VERSION ""

NS_ :

BS_:

BU_: Device Host
VAL_TABLE_ vtBridgeOperation 0 "Freewheeling" 1 "Forward" 2 "Reverse" 3 "Brake" 6 "Error" 7 "Not Available" ;
VAL_TABLE_ vtBridgeStatus 0 "OK" 1 "Shutdown" 2 "Unconfigured" 3 "Not Available" ;
VAL_TABLE_ vtDigitalInput 0 "InputLow" 1 "InputHigh" 2 "Error" 3 "Not Available" ;
VAL_TABLE_ vtOnOff 0 "Off" 1 "On" 2 "Error" 3 "Not Available" ;
VAL_TABLE_ vtPinMode 0 "Disabled" 1 "VREF" 2 "HighSide" 3 "LowSide" 4 "InputOnly" 5 "Bridge" 14 "Error" 15 "Not Available" ;
VAL_TABLE_ vtPinPullMode 0 "None" 1 "PullDown" 2 "PullUp" 3 "Not Available" ;
VAL_TABLE_ vtPwmFreq 0 "1 Hz" 1 "2 Hz" 2 "5 Hz" 3 "10 Hz" 4 "20 Hz" 5 "50 Hz" 6 "100 Hz" 7 "200 Hz" 8 "500 Hz" 9 "1 KHz" 10 "2 KHz" 11 "5 KHz" 14 "Error" 15 "Not Available" ;
VAL_TABLE_ vtQEncoderDirection 0 "Stopped" 1 "Forward" 2 "Reverse" 3 "NotAvailable" ;

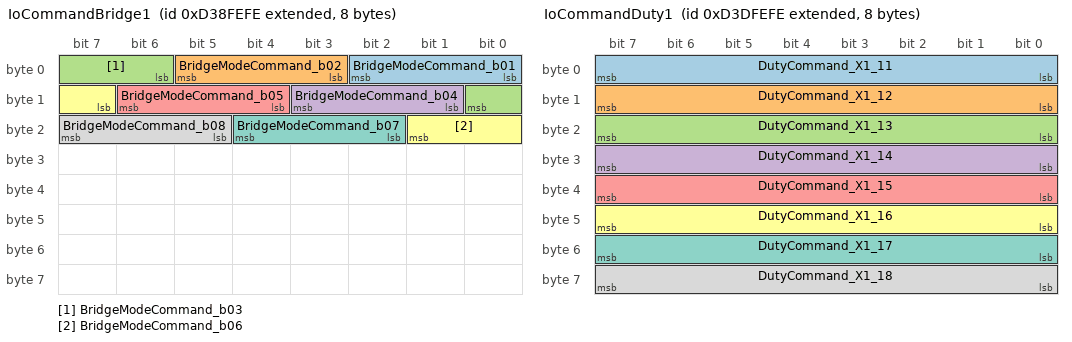
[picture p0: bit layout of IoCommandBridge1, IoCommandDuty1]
BO_ 2369322750 IoCommandBridge1: 8 Host
 SG_ BridgeModeCommand_b01 : 0|3@1+ (1,0) [0|7] ""  Device
 SG_ BridgeModeCommand_b02 : 3|3@1+ (1,0) [0|7] ""  Device
 SG_ BridgeModeCommand_b03 : 6|3@1+ (1,0) [0|7] ""  Device
 SG_ BridgeModeCommand_b04 : 9|3@1+ (1,0) [0|7] ""  Device
 SG_ BridgeModeCommand_b05 : 12|3@1+ (1,0) [0|7] ""  Device
 SG_ BridgeModeCommand_b06 : 15|3@1+ (1,0) [0|7] ""  Device
 SG_ BridgeModeCommand_b07 : 18|3@1+ (1,0) [0|7] ""  Device
 SG_ BridgeModeCommand_b08 : 21|3@1+ (1,0) [0|7] ""  Device

BO_ 2369650430 IoCommandDuty1: 8 Host
 SG_ DutyCommand_X1_11 : 0|8@1+ (0.5,0) [0|100] "%"  Device
 SG_ DutyCommand_X1_12 : 8|8@1+ (0.5,0) [0|100] "%"  Device
 SG_ DutyCommand_X1_13 : 16|8@1+ (0.5,0) [0|100] "%"  Device
 SG_ DutyCommand_X1_14 : 24|8@1+ (0.5,0) [0|100] "%"  Device
 SG_ DutyCommand_X1_15 : 32|8@1+ (0.5,0) [0|100] "%"  Device
 SG_ DutyCommand_X1_16 : 40|8@1+ (0.5,0) [0|100] "%"  Device
 SG_ DutyCommand_X1_17 : 48|8@1+ (0.5,0) [0|100] "%"  Device
 SG_ DutyCommand_X1_18 : 56|8@1+ (0.5,0) [0|100] "%"  Device

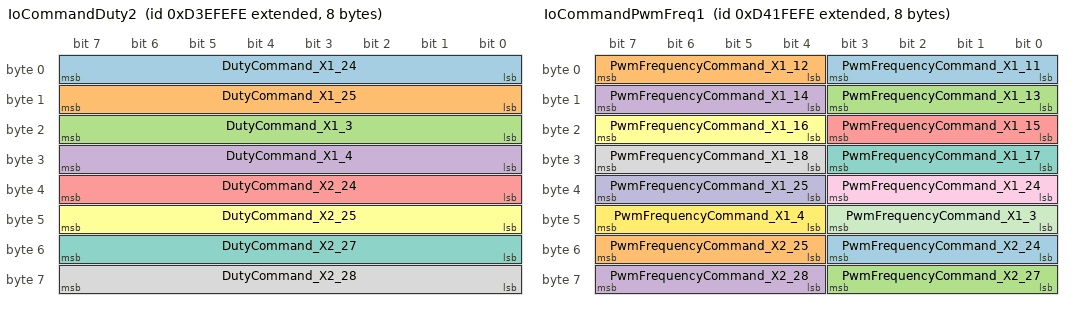
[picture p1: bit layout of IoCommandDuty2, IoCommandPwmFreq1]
BO_ 2369715966 IoCommandDuty2: 8 Host
 SG_ DutyCommand_X1_24 : 0|8@1+ (0.5,0) [0|100] "%"  Device
 SG_ DutyCommand_X1_25 : 8|8@1+ (0.5,0) [0|100] "%"  Device
 SG_ DutyCommand_X1_3 : 16|8@1+ (0.5,0) [0|100] "%"  Device
 SG_ DutyCommand_X1_4 : 24|8@1+ (0.5,0) [0|100] "%"  Device
 SG_ DutyCommand_X2_24 : 32|8@1+ (0.5,0) [0|100] "%"  Device
 SG_ DutyCommand_X2_25 : 40|8@1+ (0.5,0) [0|100] "%"  Device
 SG_ DutyCommand_X2_27 : 48|8@1+ (0.5,0) [0|100] "%"  Device
 SG_ DutyCommand_X2_28 : 56|8@1+ (0.5,0) [0|100] "%"  Device

BO_ 2370043646 IoCommandDutyFD: 32 Host
 SG_ DutyCommand_X1_11 : 0|8@1+ (0.5,0) [0|100] "%"  Device
 SG_ DutyCommand_X1_12 : 8|8@1+ (0.5,0) [0|100] "%"  Device
 SG_ DutyCommand_X1_13 : 16|8@1+ (0.5,0) [0|100] "%"  Device
 SG_ DutyCommand_X1_14 : 24|8@1+ (0.5,0) [0|100] "%"  Device
 SG_ DutyCommand_X1_15 : 32|8@1+ (0.5,0) [0|100] "%"  Device
 SG_ DutyCommand_X1_16 : 40|8@1+ (0.5,0) [0|100] "%"  Device
 SG_ DutyCommand_X1_17 : 48|8@1+ (0.5,0) [0|100] "%"  Device
 SG_ DutyCommand_X1_18 : 56|8@1+ (0.5,0) [0|100] "%"  Device
 SG_ DutyCommand_X1_24 : 64|8@1+ (0.5,0) [0|100] "%"  Device
 SG_ DutyCommand_X1_25 : 72|8@1+ (0.5,0) [0|100] "%"  Device
 SG_ DutyCommand_X1_3 : 80|8@1+ (0.5,0) [0|100] "%"  Device
 SG_ DutyCommand_X1_4 : 88|8@1+ (0.5,0) [0|100] "%"  Device
 SG_ DutyCommand_X2_24 : 96|8@1+ (0.5,0) [0|100] "%"  Device
 SG_ DutyCommand_X2_25 : 104|8@1+ (0.5,0) [0|100] "%"  Device
 SG_ DutyCommand_X2_27 : 112|8@1+ (0.5,0) [0|100] "%"  Device
 SG_ DutyCommand_X2_28 : 120|8@1+ (0.5,0) [0|100] "%"  Device

BO_ 2369388286 IoCommandPinMode1: 8 Host
 SG_ PinModeCommand_X1_11 : 0|4@1+ (1,0) [0|0] ""  Device
 SG_ PinPullModeCommand_X1_11 : 4|2@1+ (1,0) [0|0] ""  Device
 SG_ LoadDetectionCommand_X1_11 : 6|2@1+ (1,0) [0|0] ""  Device
 SG_ PinModeCommand_X1_12 : 8|4@1+ (1,0) [0|0] ""  Device
 SG_ PinPullModeCommand_X1_12 : 12|2@1+ (1,0) [0|0] ""  Device
 SG_ LoadDetectionCommand_X1_12 : 14|2@1+ (1,0) [0|0] ""  Device
 SG_ PinModeCommand_X1_13 : 16|4@1+ (1,0) [0|0] ""  Device
 SG_ PinPullModeCommand_X1_13 : 20|2@1+ (1,0) [0|0] ""  Device
 SG_ LoadDetectionCommand_X1_13 : 22|2@1+ (1,0) [0|0] ""  Device
 SG_ PinModeCommand_X1_14 : 24|4@1+ (1,0) [0|0] ""  Device
 SG_ PinPullModeCommand_X1_14 : 28|2@1+ (1,0) [0|0] ""  Device
 SG_ LoadDetectionCommand_X1_14 : 30|2@1+ (1,0) [0|0] ""  Device
 SG_ PinModeCommand_X1_15 : 32|4@1+ (1,0) [0|0] ""  Device
 SG_ PinPullModeCommand_X1_15 : 36|2@1+ (1,0) [0|0] ""  Device
 SG_ LoadDetectionCommand_X1_15 : 38|2@1+ (1,0) [0|0] ""  Device
 SG_ PinModeCommand_X1_16 : 40|4@1+ (1,0) [0|0] ""  Device
 SG_ PinPullModeCommand_X1_16 : 44|2@1+ (1,0) [0|0] ""  Device
 SG_ LoadDetectionCommand_X1_16 : 46|2@1+ (1,0) [0|0] ""  Device
 SG_ PinModeCommand_X1_17 : 48|4@1+ (1,0) [0|0] ""  Device
 SG_ PinPullModeCommand_X1_17 : 52|2@1+ (1,0) [0|0] ""  Device
 SG_ LoadDetectionCommand_X1_17 : 54|2@1+ (1,0) [0|0] ""  Device
 SG_ PinModeCommand_X1_18 : 56|4@1+ (1,0) [0|0] ""  Device
 SG_ PinPullModeCommand_X1_18 : 60|2@1+ (1,0) [0|0] ""  Device
 SG_ LoadDetectionCommand_X1_18 : 62|2@1+ (1,0) [0|0] ""  Device

BO_ 2369453822 IoCommandPinMode2: 8 Host
 SG_ PinModeCommand_X1_24 : 0|4@1+ (1,0) [0|0] ""  Device
 SG_ PinPullModeCommand_X1_24 : 4|2@1+ (1,0) [0|0] ""  Device
 SG_ LoadDetectionCommand_X1_24 : 6|2@1+ (1,0) [0|0] ""  Device
 SG_ PinModeCommand_X1_25 : 8|4@1+ (1,0) [0|0] ""  Device
 SG_ PinPullModeCommand_X1_25 : 12|2@1+ (1,0) [0|0] ""  Device
 SG_ LoadDetectionCommand_X1_25 : 14|2@1+ (1,0) [0|0] ""  Device
 SG_ PinModeCommand_X1_3 : 16|4@1+ (1,0) [0|0] ""  Device
 SG_ PinPullModeCommand_X1_3 : 20|2@1+ (1,0) [0|0] ""  Device
 SG_ LoadDetectionCommand_X1_3 : 22|2@1+ (1,0) [0|0] ""  Device
 SG_ PinModeCommand_X1_4 : 24|4@1+ (1,0) [0|0] ""  Device
 SG_ PinPullModeCommand_X1_4 : 28|2@1+ (1,0) [0|0] ""  Device
 SG_ LoadDetectionCommand_X1_4 : 30|2@1+ (1,0) [0|0] ""  Device
 SG_ PinModeCommand_X2_24 : 32|4@1+ (1,0) [0|0] ""  Device
 SG_ PinPullModeCommand_X2_24 : 36|2@1+ (1,0) [0|0] ""  Device
 SG_ LoadDetectionCommand_X2_24 : 38|2@1+ (1,0) [0|0] ""  Device
 SG_ PinModeCommand_X2_25 : 40|4@1+ (1,0) [0|0] ""  Device
 SG_ PinPullModeCommand_X2_25 : 44|2@1+ (1,0) [0|0] ""  Device
 SG_ LoadDetectionCommand_X2_25 : 46|2@1+ (1,0) [0|0] ""  Device
 SG_ PinModeCommand_X2_27 : 48|4@1+ (1,0) [0|0] ""  Device
 SG_ PinPullModeCommand_X2_27 : 52|2@1+ (1,0) [0|0] ""  Device
 SG_ LoadDetectionCommand_X2_27 : 54|2@1+ (1,0) [0|0] ""  Device
 SG_ PinModeCommand_X2_28 : 56|4@1+ (1,0) [0|0] ""  Device
 SG_ PinPullModeCommand_X2_28 : 60|2@1+ (1,0) [0|0] ""  Device
 SG_ LoadDetectionCommand_X2_28 : 62|2@1+ (1,0) [0|0] ""  Device

BO_ 2369519358 IoCommandPinMode3: 8 Host
 SG_ PinModeCommand_X2_11 : 0|4@1+ (1,0) [0|0] ""  Device
 SG_ PinPullModeCommand_X2_11 : 4|2@1+ (1,0) [0|0] ""  Device
 SG_ LoadDetectionCommand_X2_11 : 6|2@1+ (1,0) [0|0] ""  Device
 SG_ PinModeCommand_X2_12 : 8|4@1+ (1,0) [0|0] ""  Device
 SG_ PinPullModeCommand_X2_12 : 12|2@1+ (1,0) [0|0] ""  Device
 SG_ LoadDetectionCommand_X2_12 : 14|2@1+ (1,0) [0|0] ""  Device
 SG_ PinModeCommand_X2_13 : 16|4@1+ (1,0) [0|0] ""  Device
 SG_ PinPullModeCommand_X2_13 : 20|2@1+ (1,0) [0|0] ""  Device
 SG_ LoadDetectionCommand_X2_13 : 22|2@1+ (1,0) [0|0] ""  Device
 SG_ PinModeCommand_X2_14 : 24|4@1+ (1,0) [0|0] ""  Device
 SG_ PinPullModeCommand_X2_14 : 28|2@1+ (1,0) [0|0] ""  Device
 SG_ LoadDetectionCommand_X2_14 : 30|2@1+ (1,0) [0|0] ""  Device
 SG_ PinModeCommand_X2_15 : 32|4@1+ (1,0) [0|0] ""  Device
 SG_ PinPullModeCommand_X2_15 : 36|2@1+ (1,0) [0|0] ""  Device
 SG_ LoadDetectionCommand_X2_15 : 38|2@1+ (1,0) [0|0] ""  Device
 SG_ PinModeCommand_X2_16 : 40|4@1+ (1,0) [0|0] ""  Device
 SG_ PinPullModeCommand_X2_16 : 44|2@1+ (1,0) [0|0] ""  Device
 SG_ LoadDetectionCommand_X2_16 : 46|2@1+ (1,0) [0|0] ""  Device
 SG_ PinModeCommand_X2_17 : 48|4@1+ (1,0) [0|0] ""  Device
 SG_ PinPullModeCommand_X2_17 : 52|2@1+ (1,0) [0|0] ""  Device
 SG_ LoadDetectionCommand_X2_17 : 54|2@1+ (1,0) [0|0] ""  Device
 SG_ PinModeCommand_X2_18 : 56|4@1+ (1,0) [0|0] ""  Device
 SG_ PinPullModeCommand_X2_18 : 60|2@1+ (1,0) [0|0] ""  Device
 SG_ LoadDetectionCommand_X2_18 : 62|2@1+ (1,0) [0|0] ""  Device

BO_ 2369912574 IoCommandPwmFreq1: 8 Host
 SG_ PwmFrequencyCommand_X1_11 : 0|4@1+ (1,0) [0|15] ""  Device
 SG_ PwmFrequencyCommand_X1_12 : 4|4@1+ (1,0) [0|15] ""  Device
 SG_ PwmFrequencyCommand_X1_13 : 8|4@1+ (1,0) [0|15] ""  Device
 SG_ PwmFrequencyCommand_X1_14 : 12|4@1+ (1,0) [0|15] ""  Device
 SG_ PwmFrequencyCommand_X1_15 : 16|4@1+ (1,0) [0|15] ""  Device
 SG_ PwmFrequencyCommand_X1_16 : 20|4@1+ (1,0) [0|15] ""  Device
 SG_ PwmFrequencyCommand_X1_17 : 24|4@1+ (1,0) [0|15] ""  Device
 SG_ PwmFrequencyCommand_X1_18 : 28|4@1+ (1,0) [0|15] ""  Device
 SG_ PwmFrequencyCommand_X1_24 : 32|4@1+ (1,0) [0|15] ""  Device
 SG_ PwmFrequencyCommand_X1_25 : 36|4@1+ (1,0) [0|15] ""  Device
 SG_ PwmFrequencyCommand_X1_3 : 40|4@1+ (1,0) [0|15] ""  Device
 SG_ PwmFrequencyCommand_X1_4 : 44|4@1+ (1,0) [0|15] ""  Device
 SG_ PwmFrequencyCommand_X2_24 : 48|4@1+ (1,0) [0|15] ""  Device
 SG_ PwmFrequencyCommand_X2_25 : 52|4@1+ (1,0) [0|15] ""  Device
 SG_ PwmFrequencyCommand_X2_27 : 56|4@1+ (1,0) [0|15] ""  Device
 SG_ PwmFrequencyCommand_X2_28 : 60|4@1+ (1,0) [0|15] ""  Device

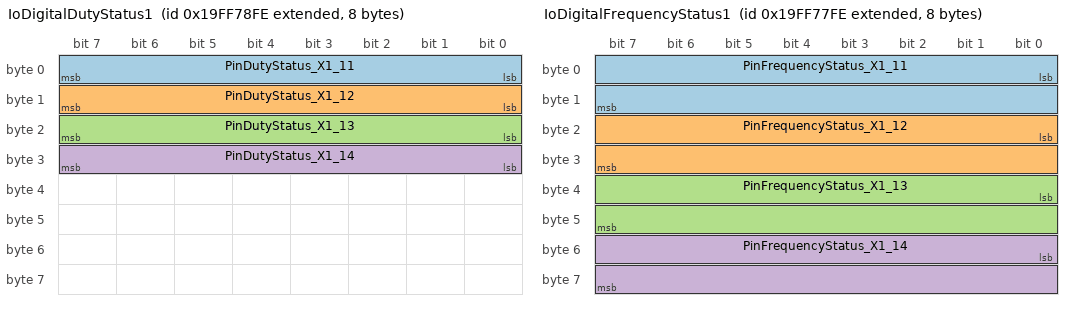
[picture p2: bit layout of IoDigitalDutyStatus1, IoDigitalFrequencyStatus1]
BO_ 2583656702 IoDigitalDutyStatus1: 8 Device
 SG_ PinDutyStatus_X1_11 : 0|8@1+ (0.5,0) [0|100] "%"  Host
 SG_ PinDutyStatus_X1_12 : 8|8@1+ (0.5,0) [0|100] "%"  Host
 SG_ PinDutyStatus_X1_13 : 16|8@1+ (0.5,0) [0|100] "%"  Host
 SG_ PinDutyStatus_X1_14 : 24|8@1+ (0.5,0) [0|100] "%"  Host

BO_ 2583656446 IoDigitalFrequencyStatus1: 8 Device
 SG_ PinFrequencyStatus_X1_11 : 0|16@1+ (0.1,0) [0|6425.5] "Hz"  Host
 SG_ PinFrequencyStatus_X1_12 : 16|16@1+ (0.1,0) [0|6425.5] "Hz"  Host
 SG_ PinFrequencyStatus_X1_13 : 32|16@1+ (0.1,0) [0|6425.5] "Hz"  Host
 SG_ PinFrequencyStatus_X1_14 : 48|16@1+ (0.1,0) [0|6425.5] "Hz"  Host

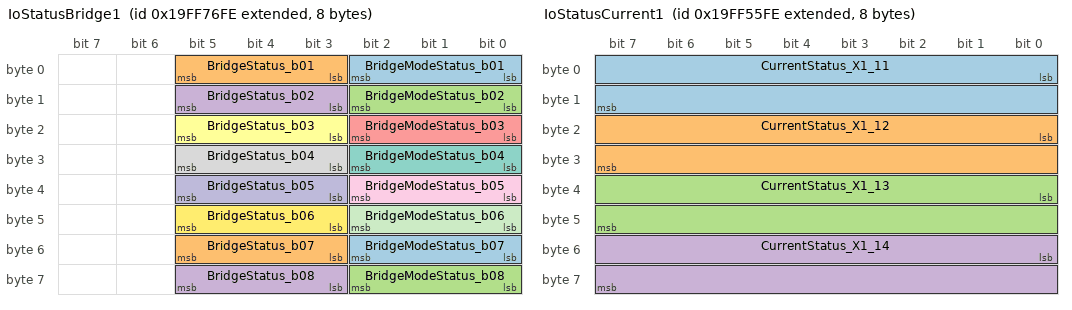
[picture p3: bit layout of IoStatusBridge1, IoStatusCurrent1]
BO_ 2583656190 IoStatusBridge1: 8 Device
 SG_ BridgeModeStatus_b01 : 0|3@1+ (1,0) [0|7] ""  Host
 SG_ BridgeStatus_b01 : 3|3@1+ (1,0) [0|7] ""  Host
 SG_ BridgeModeStatus_b02 : 8|3@1+ (1,0) [0|7] ""  Host
 SG_ BridgeStatus_b02 : 11|3@1+ (1,0) [0|7] ""  Host
 SG_ BridgeModeStatus_b03 : 16|3@1+ (1,0) [0|7] ""  Host
 SG_ BridgeStatus_b03 : 19|3@1+ (1,0) [0|7] ""  Host
 SG_ BridgeModeStatus_b04 : 24|3@1+ (1,0) [0|7] ""  Host
 SG_ BridgeStatus_b04 : 27|3@1+ (1,0) [0|7] ""  Host
 SG_ BridgeModeStatus_b05 : 32|3@1+ (1,0) [0|7] ""  Host
 SG_ BridgeStatus_b05 : 35|3@1+ (1,0) [0|7] ""  Host
 SG_ BridgeModeStatus_b06 : 40|3@1+ (1,0) [0|7] ""  Host
 SG_ BridgeStatus_b06 : 43|3@1+ (1,0) [0|7] ""  Host
 SG_ BridgeModeStatus_b07 : 48|3@1+ (1,0) [0|7] ""  Host
 SG_ BridgeStatus_b07 : 51|3@1+ (1,0) [0|7] ""  Host
 SG_ BridgeModeStatus_b08 : 56|3@1+ (1,0) [0|7] ""  Host
 SG_ BridgeStatus_b08 : 59|3@1+ (1,0) [0|7] ""  Host

BO_ 2583647742 IoStatusCurrent1: 8 Device
 SG_ CurrentStatus_X1_11 : 0|16@1+ (0.01,-320) [-320|320] "A"  Host
 SG_ CurrentStatus_X1_12 : 16|16@1+ (0.01,-320) [-320|320] "A"  Host
 SG_ CurrentStatus_X1_13 : 32|16@1+ (0.01,-320) [-320|320] "A"  Host
 SG_ CurrentStatus_X1_14 : 48|16@1+ (0.01,-320) [-320|320] "A"  Host

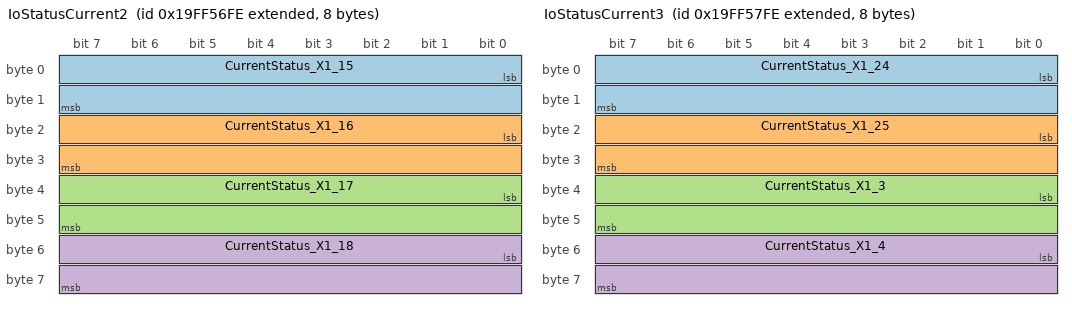
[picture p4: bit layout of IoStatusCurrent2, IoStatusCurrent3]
BO_ 2583647998 IoStatusCurrent2: 8 Device
 SG_ CurrentStatus_X1_15 : 0|16@1+ (0.01,-320) [-320|320] "A"  Host
 SG_ CurrentStatus_X1_16 : 16|16@1+ (0.01,-320) [-320|320] "A"  Host
 SG_ CurrentStatus_X1_17 : 32|16@1+ (0.01,-320) [-320|320] "A"  Host
 SG_ CurrentStatus_X1_18 : 48|16@1+ (0.01,-320) [-320|320] "A"  Host

BO_ 2583648254 IoStatusCurrent3: 8 Device
 SG_ CurrentStatus_X1_24 : 0|16@1+ (0.01,-320) [-320|320] "A"  Host
 SG_ CurrentStatus_X1_25 : 16|16@1+ (0.01,-320) [-320|320] "A"  Host
 SG_ CurrentStatus_X1_3 : 32|16@1+ (0.01,-320) [-320|320] "A"  Host
 SG_ CurrentStatus_X1_4 : 48|16@1+ (0.01,-320) [-320|320] "A"  Host

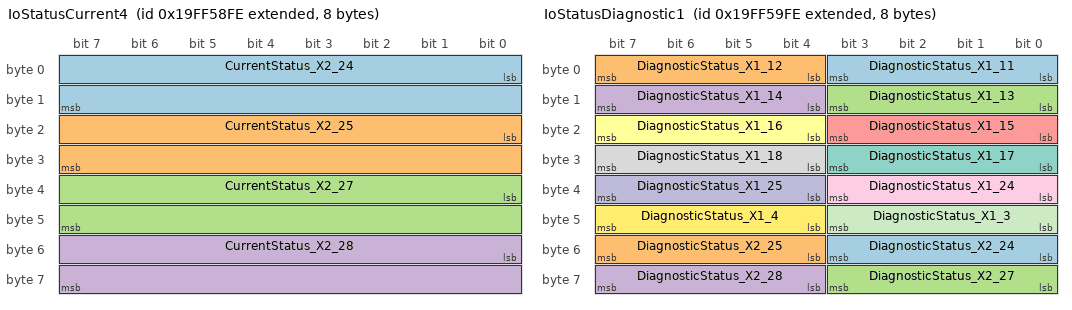
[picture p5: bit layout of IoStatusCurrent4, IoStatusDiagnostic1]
BO_ 2583648510 IoStatusCurrent4: 8 Device
 SG_ CurrentStatus_X2_24 : 0|16@1+ (0.01,-320) [-320|320] "A"  Host
 SG_ CurrentStatus_X2_25 : 16|16@1+ (0.01,-320) [-320|320] "A"  Host
 SG_ CurrentStatus_X2_27 : 32|16@1+ (0.01,-320) [-320|320] "A"  Host
 SG_ CurrentStatus_X2_28 : 48|16@1+ (0.01,-320) [-320|320] "A"  Host

BO_ 2582845950 IoStatusCurrentFD: 64 Device
 SG_ CurrentStatus_X1_11 : 0|16@1+ (0.01,-320) [-320|320] "A"  Host
 SG_ CurrentStatus_X1_12 : 16|16@1+ (0.01,-320) [-320|320] "A"  Host
 SG_ CurrentStatus_X1_13 : 32|16@1+ (0.01,-320) [-320|320] "A"  Host
 SG_ CurrentStatus_X1_14 : 48|16@1+ (0.01,-320) [-320|320] "A"  Host
 SG_ CurrentStatus_X1_15 : 64|16@1+ (0.01,-320) [-320|320] "A"  Host
 SG_ CurrentStatus_X1_16 : 80|16@1+ (0.01,-320) [-320|320] "A"  Host
 SG_ CurrentStatus_X1_17 : 96|16@1+ (0.01,-320) [-320|320] "A"  Host
 SG_ CurrentStatus_X1_18 : 112|16@1+ (0.01,-320) [-320|320] "A"  Host
 SG_ CurrentStatus_X1_24 : 128|16@1+ (0.01,-320) [-320|320] "A"  Host
 SG_ CurrentStatus_X1_25 : 144|16@1+ (0.01,-320) [-320|320] "A"  Host
 SG_ CurrentStatus_X1_3 : 160|16@1+ (0.01,-320) [-320|320] "A"  Host
 SG_ CurrentStatus_X1_4 : 176|16@1+ (0.01,-320) [-320|320] "A"  Host
 SG_ CurrentStatus_X2_24 : 192|16@1+ (0.01,-320) [-320|320] "A"  Host
 SG_ CurrentStatus_X2_25 : 208|16@1+ (0.01,-320) [-320|320] "A"  Host
 SG_ CurrentStatus_X2_27 : 224|16@1+ (0.01,-320) [-320|320] "A"  Host
 SG_ CurrentStatus_X2_28 : 240|16@1+ (0.01,-320) [-320|320] "A"  Host

BO_ 2583648766 IoStatusDiagnostic1: 8 Device
 SG_ DiagnosticStatus_X1_11 : 0|4@1+ (1,0) [0|0] ""  Host
 SG_ DiagnosticStatus_X1_12 : 4|4@1+ (1,0) [0|0] ""  Host
 SG_ DiagnosticStatus_X1_13 : 8|4@1+ (1,0) [0|0] ""  Host
 SG_ DiagnosticStatus_X1_14 : 12|4@1+ (1,0) [0|0] ""  Host
 SG_ DiagnosticStatus_X1_15 : 16|4@1+ (1,0) [0|0] ""  Host
 SG_ DiagnosticStatus_X1_16 : 20|4@1+ (1,0) [0|0] ""  Host
 SG_ DiagnosticStatus_X1_17 : 24|4@1+ (1,0) [0|0] ""  Host
 SG_ DiagnosticStatus_X1_18 : 28|4@1+ (1,0) [0|0] ""  Host
 SG_ DiagnosticStatus_X1_24 : 32|4@1+ (1,0) [0|0] ""  Host
 SG_ DiagnosticStatus_X1_25 : 36|4@1+ (1,0) [0|0] ""  Host
 SG_ DiagnosticStatus_X1_3 : 40|4@1+ (1,0) [0|0] ""  Host
 SG_ DiagnosticStatus_X1_4 : 44|4@1+ (1,0) [0|0] ""  Host
 SG_ DiagnosticStatus_X2_24 : 48|4@1+ (1,0) [0|0] ""  Host
 SG_ DiagnosticStatus_X2_25 : 52|4@1+ (1,0) [0|0] ""  Host
 SG_ DiagnosticStatus_X2_27 : 56|4@1+ (1,0) [0|0] ""  Host
 SG_ DiagnosticStatus_X2_28 : 60|4@1+ (1,0) [0|0] ""  Host

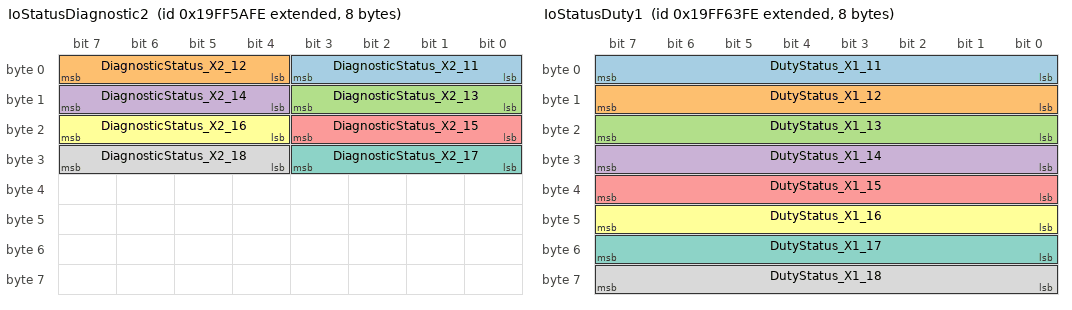
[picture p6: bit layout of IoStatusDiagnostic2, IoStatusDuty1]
BO_ 2583649022 IoStatusDiagnostic2: 8 Device
 SG_ DiagnosticStatus_X2_11 : 0|4@1+ (1,0) [0|0] ""  Host
 SG_ DiagnosticStatus_X2_12 : 4|4@1+ (1,0) [0|0] ""  Host
 SG_ DiagnosticStatus_X2_13 : 8|4@1+ (1,0) [0|0] ""  Host
 SG_ DiagnosticStatus_X2_14 : 12|4@1+ (1,0) [0|0] ""  Host
 SG_ DiagnosticStatus_X2_15 : 16|4@1+ (1,0) [0|0] ""  Host
 SG_ DiagnosticStatus_X2_16 : 20|4@1+ (1,0) [0|0] ""  Host
 SG_ DiagnosticStatus_X2_17 : 24|4@1+ (1,0) [0|0] ""  Host
 SG_ DiagnosticStatus_X2_18 : 28|4@1+ (1,0) [0|0] ""  Host

BO_ 2582847486 IoStatusDiagnosticFD: 16 Device
 SG_ DiagnosticStatus_X1_11 : 0|4@1+ (1,0) [0|0] ""  Host
 SG_ DiagnosticStatus_X1_12 : 4|4@1+ (1,0) [0|0] ""  Host
 SG_ DiagnosticStatus_X1_13 : 8|4@1+ (1,0) [0|0] ""  Host
 SG_ DiagnosticStatus_X1_14 : 12|4@1+ (1,0) [0|0] ""  Host
 SG_ DiagnosticStatus_X1_15 : 16|4@1+ (1,0) [0|0] ""  Host
 SG_ DiagnosticStatus_X1_16 : 20|4@1+ (1,0) [0|0] ""  Host
 SG_ DiagnosticStatus_X1_17 : 24|4@1+ (1,0) [0|0] ""  Host
 SG_ DiagnosticStatus_X1_18 : 28|4@1+ (1,0) [0|0] ""  Host
 SG_ DiagnosticStatus_X1_24 : 32|4@1+ (1,0) [0|0] ""  Host
 SG_ DiagnosticStatus_X1_25 : 36|4@1+ (1,0) [0|0] ""  Host
 SG_ DiagnosticStatus_X1_3 : 40|4@1+ (1,0) [0|0] ""  Host
 SG_ DiagnosticStatus_X1_4 : 44|4@1+ (1,0) [0|0] ""  Host
 SG_ DiagnosticStatus_X2_24 : 48|4@1+ (1,0) [0|0] ""  Host
 SG_ DiagnosticStatus_X2_25 : 52|4@1+ (1,0) [0|0] ""  Host
 SG_ DiagnosticStatus_X2_27 : 56|4@1+ (1,0) [0|0] ""  Host
 SG_ DiagnosticStatus_X2_28 : 60|4@1+ (1,0) [0|0] ""  Host
 SG_ DiagnosticStatus_X2_11 : 64|4@1+ (1,0) [0|0] ""  Host
 SG_ DiagnosticStatus_X2_12 : 68|4@1+ (1,0) [0|0] ""  Host
 SG_ DiagnosticStatus_X2_13 : 72|4@1+ (1,0) [0|0] ""  Host
 SG_ DiagnosticStatus_X2_14 : 76|4@1+ (1,0) [0|0] ""  Host
 SG_ DiagnosticStatus_X2_15 : 80|4@1+ (1,0) [0|0] ""  Host
 SG_ DiagnosticStatus_X2_16 : 84|4@1+ (1,0) [0|0] ""  Host
 SG_ DiagnosticStatus_X2_17 : 88|4@1+ (1,0) [0|0] ""  Host
 SG_ DiagnosticStatus_X2_18 : 92|4@1+ (1,0) [0|0] ""  Host

BO_ 2583651326 IoStatusDuty1: 8 Device
 SG_ DutyStatus_X1_11 : 0|8@1+ (0.5,0) [0|100] "%"  Host
 SG_ DutyStatus_X1_12 : 8|8@1+ (0.5,0) [0|100] "%"  Host
 SG_ DutyStatus_X1_13 : 16|8@1+ (0.5,0) [0|100] "%"  Host
 SG_ DutyStatus_X1_14 : 24|8@1+ (0.5,0) [0|100] "%"  Host
 SG_ DutyStatus_X1_15 : 32|8@1+ (0.5,0) [0|100] "%"  Host
 SG_ DutyStatus_X1_16 : 40|8@1+ (0.5,0) [0|100] "%"  Host
 SG_ DutyStatus_X1_17 : 48|8@1+ (0.5,0) [0|100] "%"  Host
 SG_ DutyStatus_X1_18 : 56|8@1+ (0.5,0) [0|100] "%"  Host

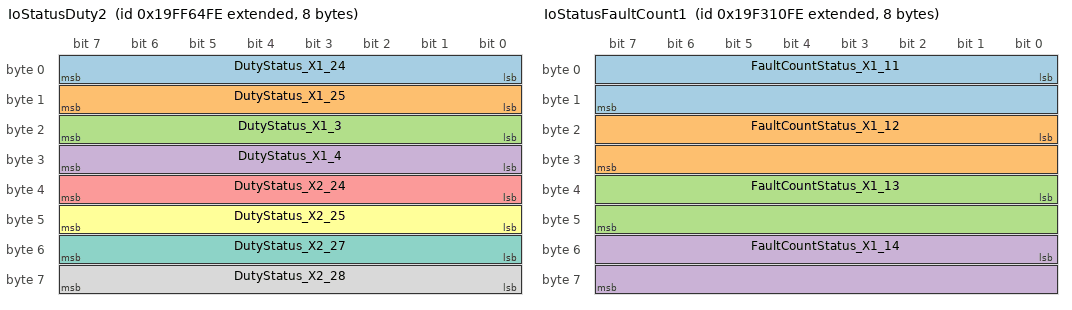
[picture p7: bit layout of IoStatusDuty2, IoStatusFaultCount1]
BO_ 2583651582 IoStatusDuty2: 8 Device
 SG_ DutyStatus_X1_24 : 0|8@1+ (0.5,0) [0|100] "%"  Host
 SG_ DutyStatus_X1_25 : 8|8@1+ (0.5,0) [0|100] "%"  Host
 SG_ DutyStatus_X1_3 : 16|8@1+ (0.5,0) [0|100] "%"  Host
 SG_ DutyStatus_X1_4 : 24|8@1+ (0.5,0) [0|100] "%"  Host
 SG_ DutyStatus_X2_24 : 32|8@1+ (0.5,0) [0|100] "%"  Host
 SG_ DutyStatus_X2_25 : 40|8@1+ (0.5,0) [0|100] "%"  Host
 SG_ DutyStatus_X2_27 : 48|8@1+ (0.5,0) [0|100] "%"  Host
 SG_ DutyStatus_X2_28 : 56|8@1+ (0.5,0) [0|100] "%"  Host

BO_ 2582847742 IoStatusDutyFD: 32 Device
 SG_ DutyStatus_X1_11 : 0|8@1+ (0.5,0) [0|100] "%"  Host
 SG_ DutyStatus_X1_12 : 8|8@1+ (0.5,0) [0|100] "%"  Host
 SG_ DutyStatus_X1_13 : 16|8@1+ (0.5,0) [0|100] "%"  Host
 SG_ DutyStatus_X1_14 : 24|8@1+ (0.5,0) [0|100] "%"  Host
 SG_ DutyStatus_X1_15 : 32|8@1+ (0.5,0) [0|100] "%"  Host
 SG_ DutyStatus_X1_16 : 40|8@1+ (0.5,0) [0|100] "%"  Host
 SG_ DutyStatus_X1_17 : 48|8@1+ (0.5,0) [0|100] "%"  Host
 SG_ DutyStatus_X1_18 : 56|8@1+ (0.5,0) [0|100] "%"  Host
 SG_ DutyStatus_X1_24 : 64|8@1+ (0.5,0) [0|100] "%"  Host
 SG_ DutyStatus_X1_25 : 72|8@1+ (0.5,0) [0|100] "%"  Host
 SG_ DutyStatus_X1_3 : 80|8@1+ (0.5,0) [0|100] "%"  Host
 SG_ DutyStatus_X1_4 : 88|8@1+ (0.5,0) [0|100] "%"  Host
 SG_ DutyStatus_X2_24 : 96|8@1+ (0.5,0) [0|100] "%"  Host
 SG_ DutyStatus_X2_25 : 104|8@1+ (0.5,0) [0|100] "%"  Host
 SG_ DutyStatus_X2_27 : 112|8@1+ (0.5,0) [0|100] "%"  Host
 SG_ DutyStatus_X2_28 : 120|8@1+ (0.5,0) [0|100] "%"  Host

BO_ 2582843646 IoStatusFaultCount1: 8 Device
 SG_ FaultCountStatus_X1_11 : 0|16@1+ (1,0) [0|64255] ""  Host
 SG_ FaultCountStatus_X1_12 : 16|16@1+ (1,0) [0|64255] ""  Host
 SG_ FaultCountStatus_X1_13 : 32|16@1+ (1,0) [0|64255] ""  Host
 SG_ FaultCountStatus_X1_14 : 48|16@1+ (1,0) [0|64255] ""  Host

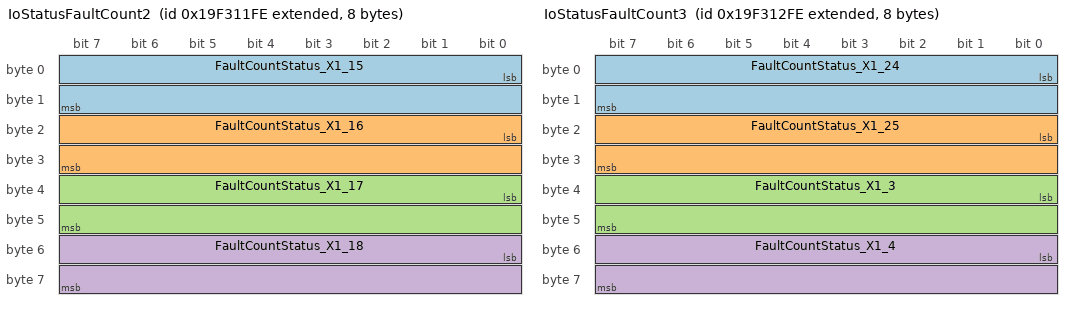
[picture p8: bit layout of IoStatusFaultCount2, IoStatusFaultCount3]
BO_ 2582843902 IoStatusFaultCount2: 8 Device
 SG_ FaultCountStatus_X1_15 : 0|16@1+ (1,0) [0|64255] ""  Host
 SG_ FaultCountStatus_X1_16 : 16|16@1+ (1,0) [0|64255] ""  Host
 SG_ FaultCountStatus_X1_17 : 32|16@1+ (1,0) [0|64255] ""  Host
 SG_ FaultCountStatus_X1_18 : 48|16@1+ (1,0) [0|64255] ""  Host

BO_ 2582844158 IoStatusFaultCount3: 8 Device
 SG_ FaultCountStatus_X1_24 : 0|16@1+ (1,0) [0|64255] ""  Host
 SG_ FaultCountStatus_X1_25 : 16|16@1+ (1,0) [0|64255] ""  Host
 SG_ FaultCountStatus_X1_3 : 32|16@1+ (1,0) [0|64255] ""  Host
 SG_ FaultCountStatus_X1_4 : 48|16@1+ (1,0) [0|64255] ""  Host

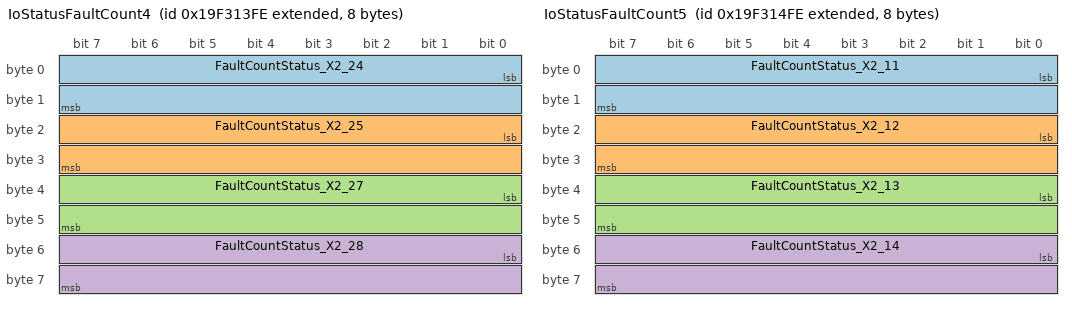
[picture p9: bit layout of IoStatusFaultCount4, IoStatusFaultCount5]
BO_ 2582844414 IoStatusFaultCount4: 8 Device
 SG_ FaultCountStatus_X2_24 : 0|16@1+ (1,0) [0|64255] ""  Host
 SG_ FaultCountStatus_X2_25 : 16|16@1+ (1,0) [0|64255] ""  Host
 SG_ FaultCountStatus_X2_27 : 32|16@1+ (1,0) [0|64255] ""  Host
 SG_ FaultCountStatus_X2_28 : 48|16@1+ (1,0) [0|64255] ""  Host

BO_ 2582844670 IoStatusFaultCount5: 8 Device
 SG_ FaultCountStatus_X2_11 : 0|16@1+ (1,0) [0|64255] ""  Host
 SG_ FaultCountStatus_X2_12 : 16|16@1+ (1,0) [0|64255] ""  Host
 SG_ FaultCountStatus_X2_13 : 32|16@1+ (1,0) [0|64255] ""  Host
 SG_ FaultCountStatus_X2_14 : 48|16@1+ (1,0) [0|64255] ""  Host

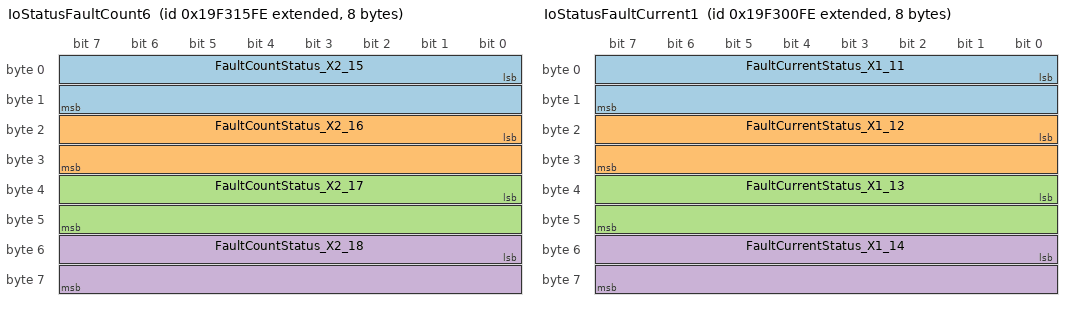
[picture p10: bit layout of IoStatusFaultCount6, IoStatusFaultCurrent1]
BO_ 2582844926 IoStatusFaultCount6: 8 Device
 SG_ FaultCountStatus_X2_15 : 0|16@1+ (1,0) [0|64255] ""  Host
 SG_ FaultCountStatus_X2_16 : 16|16@1+ (1,0) [0|64255] ""  Host
 SG_ FaultCountStatus_X2_17 : 32|16@1+ (1,0) [0|64255] ""  Host
 SG_ FaultCountStatus_X2_18 : 48|16@1+ (1,0) [0|64255] ""  Host

BO_ 2582846206 IoStatusFaultCountFD: 64 Device
 SG_ FaultCountStatus_X1_11 : 0|16@1+ (1,0) [0|64255] ""  Host
 SG_ FaultCountStatus_X1_12 : 16|16@1+ (1,0) [0|64255] ""  Host
 SG_ FaultCountStatus_X1_13 : 32|16@1+ (1,0) [0|64255] ""  Host
 SG_ FaultCountStatus_X1_14 : 48|16@1+ (1,0) [0|64255] ""  Host
 SG_ FaultCountStatus_X1_15 : 64|16@1+ (1,0) [0|64255] ""  Host
 SG_ FaultCountStatus_X1_16 : 80|16@1+ (1,0) [0|64255] ""  Host
 SG_ FaultCountStatus_X1_17 : 96|16@1+ (1,0) [0|64255] ""  Host
 SG_ FaultCountStatus_X1_18 : 112|16@1+ (1,0) [0|64255] ""  Host
 SG_ FaultCountStatus_X1_24 : 128|16@1+ (1,0) [0|64255] ""  Host
 SG_ FaultCountStatus_X1_25 : 144|16@1+ (1,0) [0|64255] ""  Host
 SG_ FaultCountStatus_X1_3 : 160|16@1+ (1,0) [0|64255] ""  Host
 SG_ FaultCountStatus_X1_4 : 176|16@1+ (1,0) [0|64255] ""  Host
 SG_ FaultCountStatus_X2_24 : 192|16@1+ (1,0) [0|64255] ""  Host
 SG_ FaultCountStatus_X2_25 : 208|16@1+ (1,0) [0|64255] ""  Host
 SG_ FaultCountStatus_X2_27 : 224|16@1+ (1,0) [0|64255] ""  Host
 SG_ FaultCountStatus_X2_28 : 240|16@1+ (1,0) [0|64255] ""  Host
 SG_ FaultCountStatus_X2_11 : 256|16@1+ (1,0) [0|64255] ""  Host
 SG_ FaultCountStatus_X2_12 : 272|16@1+ (1,0) [0|64255] ""  Host
 SG_ FaultCountStatus_X2_13 : 288|16@1+ (1,0) [0|64255] ""  Host
 SG_ FaultCountStatus_X2_14 : 304|16@1+ (1,0) [0|64255] ""  Host
 SG_ FaultCountStatus_X2_15 : 320|16@1+ (1,0) [0|64255] ""  Host
 SG_ FaultCountStatus_X2_16 : 336|16@1+ (1,0) [0|64255] ""  Host
 SG_ FaultCountStatus_X2_17 : 352|16@1+ (1,0) [0|64255] ""  Host
 SG_ FaultCountStatus_X2_18 : 368|16@1+ (1,0) [0|64255] ""  Host

BO_ 2582839550 IoStatusFaultCurrent1: 8 Device
 SG_ FaultCurrentStatus_X1_11 : 0|16@1+ (0.01,-320) [-320|320] "A"  Host
 SG_ FaultCurrentStatus_X1_12 : 16|16@1+ (0.01,-320) [-320|320] "A"  Host
 SG_ FaultCurrentStatus_X1_13 : 32|16@1+ (0.01,-320) [-320|320] "A"  Host
 SG_ FaultCurrentStatus_X1_14 : 48|16@1+ (0.01,-320) [-320|320] "A"  Host

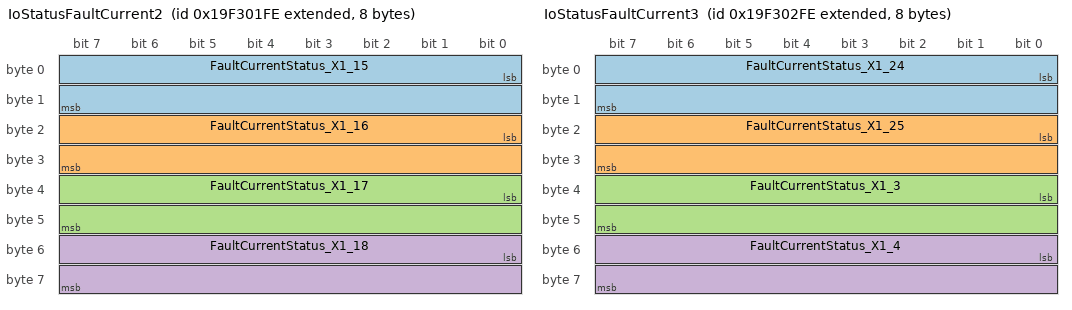
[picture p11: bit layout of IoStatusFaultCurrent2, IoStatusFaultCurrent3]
BO_ 2582839806 IoStatusFaultCurrent2: 8 Device
 SG_ FaultCurrentStatus_X1_15 : 0|16@1+ (0.01,-320) [-320|320] "A"  Host
 SG_ FaultCurrentStatus_X1_16 : 16|16@1+ (0.01,-320) [-320|320] "A"  Host
 SG_ FaultCurrentStatus_X1_17 : 32|16@1+ (0.01,-320) [-320|320] "A"  Host
 SG_ FaultCurrentStatus_X1_18 : 48|16@1+ (0.01,-320) [-320|320] "A"  Host

BO_ 2582840062 IoStatusFaultCurrent3: 8 Device
 SG_ FaultCurrentStatus_X1_24 : 0|16@1+ (0.01,-320) [-320|320] "A"  Host
 SG_ FaultCurrentStatus_X1_25 : 16|16@1+ (0.01,-320) [-320|320] "A"  Host
 SG_ FaultCurrentStatus_X1_3 : 32|16@1+ (0.01,-320) [-320|320] "A"  Host
 SG_ FaultCurrentStatus_X1_4 : 48|16@1+ (0.01,-320) [-320|320] "A"  Host

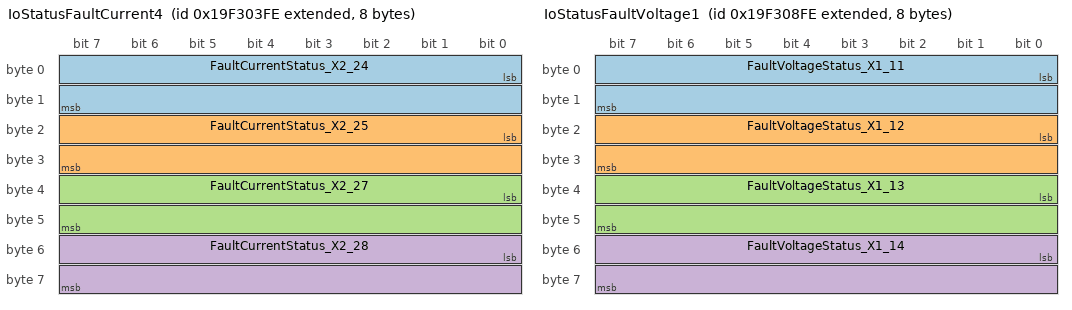
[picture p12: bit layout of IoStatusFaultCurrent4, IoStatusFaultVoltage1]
BO_ 2582840318 IoStatusFaultCurrent4: 8 Device
 SG_ FaultCurrentStatus_X2_24 : 0|16@1+ (0.01,-320) [-320|320] "A"  Host
 SG_ FaultCurrentStatus_X2_25 : 16|16@1+ (0.01,-320) [-320|320] "A"  Host
 SG_ FaultCurrentStatus_X2_27 : 32|16@1+ (0.01,-320) [-320|320] "A"  Host
 SG_ FaultCurrentStatus_X2_28 : 48|16@1+ (0.01,-320) [-320|320] "A"  Host

BO_ 2582846462 IoStatusFaultCurrentFD: 64 Device
 SG_ FaultCurrentStatus_X1_11 : 0|16@1+ (0.01,-320) [-320|320] "A"  Host
 SG_ FaultCurrentStatus_X1_12 : 16|16@1+ (0.01,-320) [-320|320] "A"  Host
 SG_ FaultCurrentStatus_X1_13 : 32|16@1+ (0.01,-320) [-320|320] "A"  Host
 SG_ FaultCurrentStatus_X1_14 : 48|16@1+ (0.01,-320) [-320|320] "A"  Host
 SG_ FaultCurrentStatus_X1_15 : 64|16@1+ (0.01,-320) [-320|320] "A"  Host
 SG_ FaultCurrentStatus_X1_16 : 80|16@1+ (0.01,-320) [-320|320] "A"  Host
 SG_ FaultCurrentStatus_X1_17 : 96|16@1+ (0.01,-320) [-320|320] "A"  Host
 SG_ FaultCurrentStatus_X1_18 : 112|16@1+ (0.01,-320) [-320|320] "A"  Host
 SG_ FaultCurrentStatus_X1_24 : 128|16@1+ (0.01,-320) [-320|320] "A"  Host
 SG_ FaultCurrentStatus_X1_25 : 144|16@1+ (0.01,-320) [-320|320] "A"  Host
 SG_ FaultCurrentStatus_X1_3 : 160|16@1+ (0.01,-320) [-320|320] "A"  Host
 SG_ FaultCurrentStatus_X1_4 : 176|16@1+ (0.01,-320) [-320|320] "A"  Host
 SG_ FaultCurrentStatus_X2_24 : 192|16@1+ (0.01,-320) [-320|320] "A"  Host
 SG_ FaultCurrentStatus_X2_25 : 208|16@1+ (0.01,-320) [-320|320] "A"  Host
 SG_ FaultCurrentStatus_X2_27 : 224|16@1+ (0.01,-320) [-320|320] "A"  Host
 SG_ FaultCurrentStatus_X2_28 : 240|16@1+ (0.01,-320) [-320|320] "A"  Host

BO_ 2582841598 IoStatusFaultVoltage1: 8 Device
 SG_ FaultVoltageStatus_X1_11 : 0|16@1+ (0.001,0) [0|64.255] "V"  Host
 SG_ FaultVoltageStatus_X1_12 : 16|16@1+ (0.001,0) [0|64.255] "V"  Host
 SG_ FaultVoltageStatus_X1_13 : 32|16@1+ (0.001,0) [0|64.255] "V"  Host
 SG_ FaultVoltageStatus_X1_14 : 48|16@1+ (0.001,0) [0|64.255] "V"  Host

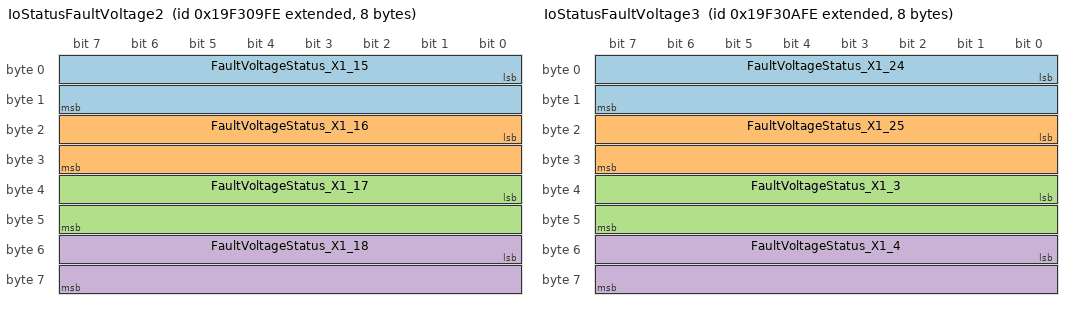
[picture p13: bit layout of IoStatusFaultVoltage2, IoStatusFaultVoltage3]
BO_ 2582841854 IoStatusFaultVoltage2: 8 Device
 SG_ FaultVoltageStatus_X1_15 : 0|16@1+ (0.001,0) [0|64.255] "V"  Host
 SG_ FaultVoltageStatus_X1_16 : 16|16@1+ (0.001,0) [0|64.255] "V"  Host
 SG_ FaultVoltageStatus_X1_17 : 32|16@1+ (0.001,0) [0|64.255] "V"  Host
 SG_ FaultVoltageStatus_X1_18 : 48|16@1+ (0.001,0) [0|64.255] "V"  Host

BO_ 2582842110 IoStatusFaultVoltage3: 8 Device
 SG_ FaultVoltageStatus_X1_24 : 0|16@1+ (0.001,0) [0|64.255] "V"  Host
 SG_ FaultVoltageStatus_X1_25 : 16|16@1+ (0.001,0) [0|64.255] "V"  Host
 SG_ FaultVoltageStatus_X1_3 : 32|16@1+ (0.001,0) [0|64.255] "V"  Host
 SG_ FaultVoltageStatus_X1_4 : 48|16@1+ (0.001,0) [0|64.255] "V"  Host

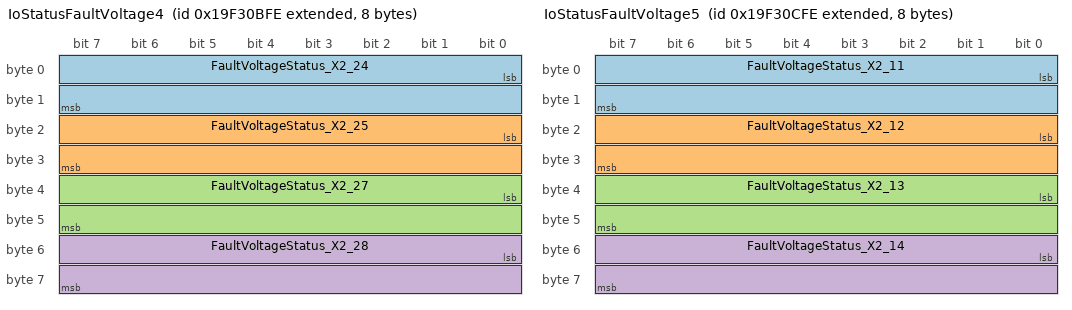
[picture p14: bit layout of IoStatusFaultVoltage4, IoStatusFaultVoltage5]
BO_ 2582842366 IoStatusFaultVoltage4: 8 Device
 SG_ FaultVoltageStatus_X2_24 : 0|16@1+ (0.001,0) [0|64.255] "V"  Host
 SG_ FaultVoltageStatus_X2_25 : 16|16@1+ (0.001,0) [0|64.255] "V"  Host
 SG_ FaultVoltageStatus_X2_27 : 32|16@1+ (0.001,0) [0|64.255] "V"  Host
 SG_ FaultVoltageStatus_X2_28 : 48|16@1+ (0.001,0) [0|64.255] "V"  Host

BO_ 2582842622 IoStatusFaultVoltage5: 8 Device
 SG_ FaultVoltageStatus_X2_11 : 0|16@1+ (0.001,0) [0|64.255] "V"  Host
 SG_ FaultVoltageStatus_X2_12 : 16|16@1+ (0.001,0) [0|64.255] "V"  Host
 SG_ FaultVoltageStatus_X2_13 : 32|16@1+ (0.001,0) [0|64.255] "V"  Host
 SG_ FaultVoltageStatus_X2_14 : 48|16@1+ (0.001,0) [0|64.255] "V"  Host

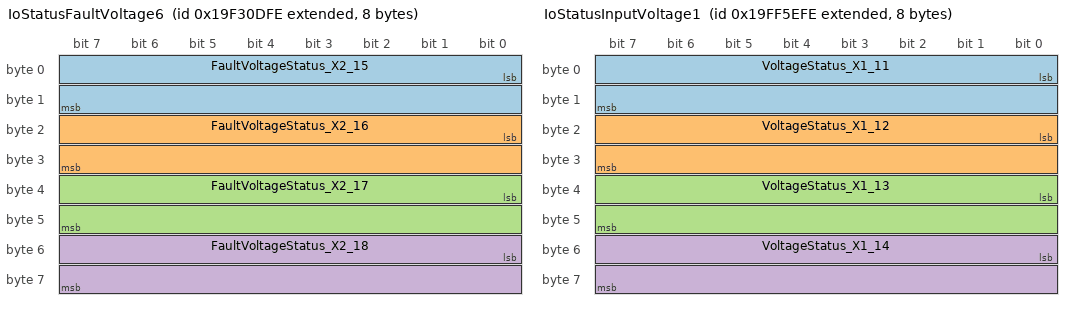
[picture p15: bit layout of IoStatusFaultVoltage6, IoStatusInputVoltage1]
BO_ 2582842878 IoStatusFaultVoltage6: 8 Device
 SG_ FaultVoltageStatus_X2_15 : 0|16@1+ (0.001,0) [0|64.255] "V"  Host
 SG_ FaultVoltageStatus_X2_16 : 16|16@1+ (0.001,0) [0|64.255] "V"  Host
 SG_ FaultVoltageStatus_X2_17 : 32|16@1+ (0.001,0) [0|64.255] "V"  Host
 SG_ FaultVoltageStatus_X2_18 : 48|16@1+ (0.001,0) [0|64.255] "V"  Host

BO_ 2582846718 IoStatusFaultVoltageFD: 64 Device
 SG_ FaultVoltageStatus_X1_11 : 0|16@1+ (0.001,0) [0|64.255] "V"  Host
 SG_ FaultVoltageStatus_X1_12 : 16|16@1+ (0.001,0) [0|64.255] "V"  Host
 SG_ FaultVoltageStatus_X1_13 : 32|16@1+ (0.001,0) [0|64.255] "V"  Host
 SG_ FaultVoltageStatus_X1_14 : 48|16@1+ (0.001,0) [0|64.255] "V"  Host
 SG_ FaultVoltageStatus_X1_15 : 64|16@1+ (0.001,0) [0|64.255] "V"  Host
 SG_ FaultVoltageStatus_X1_16 : 80|16@1+ (0.001,0) [0|64.255] "V"  Host
 SG_ FaultVoltageStatus_X1_17 : 96|16@1+ (0.001,0) [0|64.255] "V"  Host
 SG_ FaultVoltageStatus_X1_18 : 112|16@1+ (0.001,0) [0|64.255] "V"  Host
 SG_ FaultVoltageStatus_X1_24 : 128|16@1+ (0.001,0) [0|64.255] "V"  Host
 SG_ FaultVoltageStatus_X1_25 : 144|16@1+ (0.001,0) [0|64.255] "V"  Host
 SG_ FaultVoltageStatus_X1_3 : 160|16@1+ (0.001,0) [0|64.255] "V"  Host
 SG_ FaultVoltageStatus_X1_4 : 176|16@1+ (0.001,0) [0|64.255] "V"  Host
 SG_ FaultVoltageStatus_X2_24 : 192|16@1+ (0.001,0) [0|64.255] "V"  Host
 SG_ FaultVoltageStatus_X2_25 : 208|16@1+ (0.001,0) [0|64.255] "V"  Host
 SG_ FaultVoltageStatus_X2_27 : 224|16@1+ (0.001,0) [0|64.255] "V"  Host
 SG_ FaultVoltageStatus_X2_28 : 240|16@1+ (0.001,0) [0|64.255] "V"  Host
 SG_ FaultVoltageStatus_X2_11 : 256|16@1+ (0.001,0) [0|64.255] "V"  Host
 SG_ FaultVoltageStatus_X2_12 : 272|16@1+ (0.001,0) [0|64.255] "V"  Host
 SG_ FaultVoltageStatus_X2_13 : 288|16@1+ (0.001,0) [0|64.255] "V"  Host
 SG_ FaultVoltageStatus_X2_14 : 304|16@1+ (0.001,0) [0|64.255] "V"  Host
 SG_ FaultVoltageStatus_X2_15 : 320|16@1+ (0.001,0) [0|64.255] "V"  Host
 SG_ FaultVoltageStatus_X2_16 : 336|16@1+ (0.001,0) [0|64.255] "V"  Host
 SG_ FaultVoltageStatus_X2_17 : 352|16@1+ (0.001,0) [0|64.255] "V"  Host
 SG_ FaultVoltageStatus_X2_18 : 368|16@1+ (0.001,0) [0|64.255] "V"  Host

BO_ 2583650046 IoStatusInputVoltage1: 8 Device
 SG_ VoltageStatus_X1_11 : 0|16@1+ (0.001,0) [0|64.255] "V"  Host
 SG_ VoltageStatus_X1_12 : 16|16@1+ (0.001,0) [0|64.255] "V"  Host
 SG_ VoltageStatus_X1_13 : 32|16@1+ (0.001,0) [0|64.255] "V"  Host
 SG_ VoltageStatus_X1_14 : 48|16@1+ (0.001,0) [0|64.255] "V"  Host

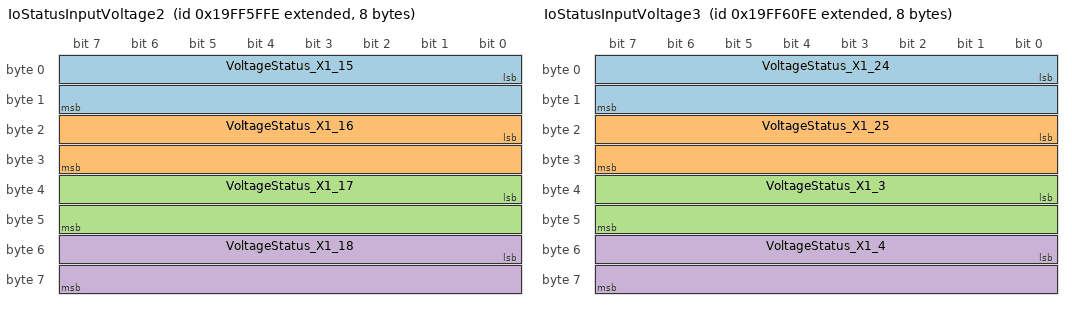
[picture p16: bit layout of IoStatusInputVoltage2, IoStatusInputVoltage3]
BO_ 2583650302 IoStatusInputVoltage2: 8 Device
 SG_ VoltageStatus_X1_15 : 0|16@1+ (0.001,0) [0|64.255] "V"  Host
 SG_ VoltageStatus_X1_16 : 16|16@1+ (0.001,0) [0|64.255] "V"  Host
 SG_ VoltageStatus_X1_17 : 32|16@1+ (0.001,0) [0|64.255] "V"  Host
 SG_ VoltageStatus_X1_18 : 48|16@1+ (0.001,0) [0|64.255] "V"  Host

BO_ 2583650558 IoStatusInputVoltage3: 8 Device
 SG_ VoltageStatus_X1_24 : 0|16@1+ (0.001,0) [0|64.255] "V"  Host
 SG_ VoltageStatus_X1_25 : 16|16@1+ (0.001,0) [0|64.255] "V"  Host
 SG_ VoltageStatus_X1_3 : 32|16@1+ (0.001,0) [0|64.255] "V"  Host
 SG_ VoltageStatus_X1_4 : 48|16@1+ (0.001,0) [0|64.255] "V"  Host

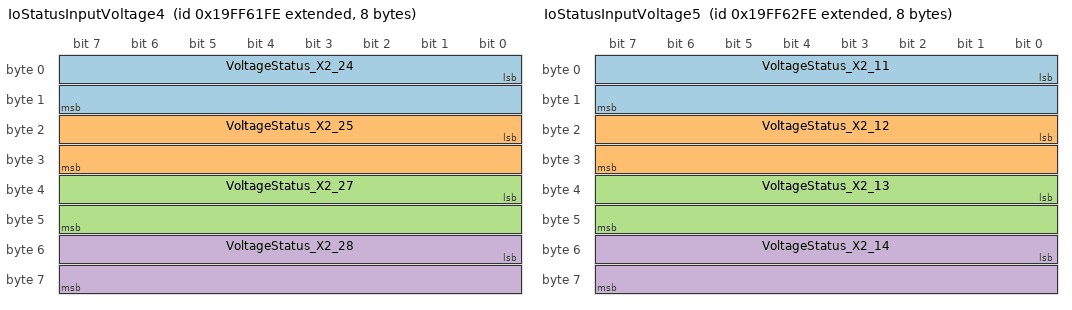
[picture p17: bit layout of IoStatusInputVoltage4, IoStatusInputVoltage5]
BO_ 2583650814 IoStatusInputVoltage4: 8 Device
 SG_ VoltageStatus_X2_24 : 0|16@1+ (0.001,0) [0|64.255] "V"  Host
 SG_ VoltageStatus_X2_25 : 16|16@1+ (0.001,0) [0|64.255] "V"  Host
 SG_ VoltageStatus_X2_27 : 32|16@1+ (0.001,0) [0|64.255] "V"  Host
 SG_ VoltageStatus_X2_28 : 48|16@1+ (0.001,0) [0|64.255] "V"  Host

BO_ 2583651070 IoStatusInputVoltage5: 8 Device
 SG_ VoltageStatus_X2_11 : 0|16@1+ (0.001,0) [0|64.255] "V"  Host
 SG_ VoltageStatus_X2_12 : 16|16@1+ (0.001,0) [0|64.255] "V"  Host
 SG_ VoltageStatus_X2_13 : 32|16@1+ (0.001,0) [0|64.255] "V"  Host
 SG_ VoltageStatus_X2_14 : 48|16@1+ (0.001,0) [0|64.255] "V"  Host

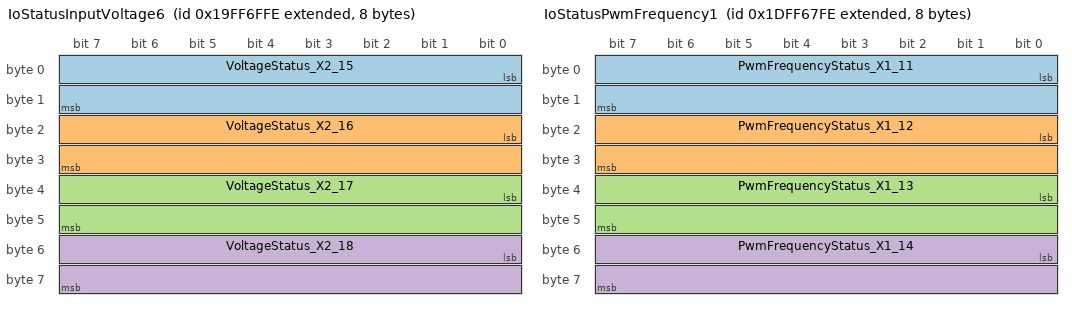
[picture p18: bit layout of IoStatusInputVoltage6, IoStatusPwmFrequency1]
BO_ 2583654398 IoStatusInputVoltage6: 8 Device
 SG_ VoltageStatus_X2_15 : 0|16@1+ (0.001,0) [0|64.255] "V"  Host
 SG_ VoltageStatus_X2_16 : 16|16@1+ (0.001,0) [0|64.255] "V"  Host
 SG_ VoltageStatus_X2_17 : 32|16@1+ (0.001,0) [0|64.255] "V"  Host
 SG_ VoltageStatus_X2_18 : 48|16@1+ (0.001,0) [0|64.255] "V"  Host

BO_ 2582845694 IoStatusInputVoltageFD: 64 Device
 SG_ VoltageStatus_X1_11 : 0|16@1+ (0.001,0) [0|64.255] "V"  Host
 SG_ VoltageStatus_X1_12 : 16|16@1+ (0.001,0) [0|64.255] "V"  Host
 SG_ VoltageStatus_X1_13 : 32|16@1+ (0.001,0) [0|64.255] "V"  Host
 SG_ VoltageStatus_X1_14 : 48|16@1+ (0.001,0) [0|64.255] "V"  Host
 SG_ VoltageStatus_X1_15 : 64|16@1+ (0.001,0) [0|64.255] "V"  Host
 SG_ VoltageStatus_X1_16 : 80|16@1+ (0.001,0) [0|64.255] "V"  Host
 SG_ VoltageStatus_X1_17 : 96|16@1+ (0.001,0) [0|64.255] "V"  Host
 SG_ VoltageStatus_X1_18 : 112|16@1+ (0.001,0) [0|64.255] "V"  Host
 SG_ VoltageStatus_X1_24 : 128|16@1+ (0.001,0) [0|64.255] "V"  Host
 SG_ VoltageStatus_X1_25 : 144|16@1+ (0.001,0) [0|64.255] "V"  Host
 SG_ VoltageStatus_X1_3 : 160|16@1+ (0.001,0) [0|64.255] "V"  Host
 SG_ VoltageStatus_X1_4 : 176|16@1+ (0.001,0) [0|64.255] "V"  Host
 SG_ VoltageStatus_X2_24 : 192|16@1+ (0.001,0) [0|64.255] "V"  Host
 SG_ VoltageStatus_X2_25 : 208|16@1+ (0.001,0) [0|64.255] "V"  Host
 SG_ VoltageStatus_X2_27 : 224|16@1+ (0.001,0) [0|64.255] "V"  Host
 SG_ VoltageStatus_X2_28 : 240|16@1+ (0.001,0) [0|64.255] "V"  Host
 SG_ VoltageStatus_X2_11 : 256|16@1+ (0.001,0) [0|64.255] "V"  Host
 SG_ VoltageStatus_X2_12 : 272|16@1+ (0.001,0) [0|64.255] "V"  Host
 SG_ VoltageStatus_X2_13 : 288|16@1+ (0.001,0) [0|64.255] "V"  Host
 SG_ VoltageStatus_X2_14 : 304|16@1+ (0.001,0) [0|64.255] "V"  Host
 SG_ VoltageStatus_X2_15 : 320|16@1+ (0.001,0) [0|64.255] "V"  Host
 SG_ VoltageStatus_X2_16 : 336|16@1+ (0.001,0) [0|64.255] "V"  Host
 SG_ VoltageStatus_X2_17 : 352|16@1+ (0.001,0) [0|64.255] "V"  Host
 SG_ VoltageStatus_X2_18 : 368|16@1+ (0.001,0) [0|64.255] "V"  Host

BO_ 2583646718 IoStatusPinMode1: 8 Device
 SG_ PinModeStatus_X1_11 : 0|4@1+ (1,0) [0|0] ""  Host
 SG_ PinPullModeStatus_X1_11 : 4|2@1+ (1,0) [0|0] ""  Host
 SG_ LoadDetectionStatus_X1_11 : 6|2@1+ (1,0) [0|0] ""  Host
 SG_ PinModeStatus_X1_12 : 8|4@1+ (1,0) [0|0] ""  Host
 SG_ PinPullModeStatus_X1_12 : 12|2@1+ (1,0) [0|0] ""  Host
 SG_ LoadDetectionStatus_X1_12 : 14|2@1+ (1,0) [0|0] ""  Host
 SG_ PinModeStatus_X1_13 : 16|4@1+ (1,0) [0|0] ""  Host
 SG_ PinPullModeStatus_X1_13 : 20|2@1+ (1,0) [0|0] ""  Host
 SG_ LoadDetectionStatus_X1_13 : 22|2@1+ (1,0) [0|0] ""  Host
 SG_ PinModeStatus_X1_14 : 24|4@1+ (1,0) [0|0] ""  Host
 SG_ PinPullModeStatus_X1_14 : 28|2@1+ (1,0) [0|0] ""  Host
 SG_ LoadDetectionStatus_X1_14 : 30|2@1+ (1,0) [0|0] ""  Host
 SG_ PinModeStatus_X1_15 : 32|4@1+ (1,0) [0|0] ""  Host
 SG_ PinPullModeStatus_X1_15 : 36|2@1+ (1,0) [0|0] ""  Host
 SG_ LoadDetectionStatus_X1_15 : 38|2@1+ (1,0) [0|0] ""  Host
 SG_ PinModeStatus_X1_16 : 40|4@1+ (1,0) [0|0] ""  Host
 SG_ PinPullModeStatus_X1_16 : 44|2@1+ (1,0) [0|0] ""  Host
 SG_ LoadDetectionStatus_X1_16 : 46|2@1+ (1,0) [0|0] ""  Host
 SG_ PinModeStatus_X1_17 : 48|4@1+ (1,0) [0|0] ""  Host
 SG_ PinPullModeStatus_X1_17 : 52|2@1+ (1,0) [0|0] ""  Host
 SG_ LoadDetectionStatus_X1_17 : 54|2@1+ (1,0) [0|0] ""  Host
 SG_ PinModeStatus_X1_18 : 56|4@1+ (1,0) [0|0] ""  Host
 SG_ PinPullModeStatus_X1_18 : 60|2@1+ (1,0) [0|0] ""  Host
 SG_ LoadDetectionStatus_X1_18 : 62|2@1+ (1,0) [0|0] ""  Host

BO_ 2583646974 IoStatusPinMode2: 8 Device
 SG_ PinModeStatus_X1_24 : 0|4@1+ (1,0) [0|0] ""  Host
 SG_ PinPullModeStatus_X1_24 : 4|2@1+ (1,0) [0|0] ""  Host
 SG_ LoadDetectionStatus_X1_24 : 6|2@1+ (1,0) [0|0] ""  Host
 SG_ PinModeStatus_X1_25 : 8|4@1+ (1,0) [0|0] ""  Host
 SG_ PinPullModeStatus_X1_25 : 12|2@1+ (1,0) [0|0] ""  Host
 SG_ LoadDetectionStatus_X1_25 : 14|2@1+ (1,0) [0|0] ""  Host
 SG_ PinModeStatus_X1_3 : 16|4@1+ (1,0) [0|0] ""  Host
 SG_ PinPullModeStatus_X1_3 : 20|2@1+ (1,0) [0|0] ""  Host
 SG_ LoadDetectionStatus_X1_3 : 22|2@1+ (1,0) [0|0] ""  Host
 SG_ PinModeStatus_X1_4 : 24|4@1+ (1,0) [0|0] ""  Host
 SG_ PinPullModeStatus_X1_4 : 28|2@1+ (1,0) [0|0] ""  Host
 SG_ LoadDetectionStatus_X1_4 : 30|2@1+ (1,0) [0|0] ""  Host
 SG_ PinModeStatus_X2_24 : 32|4@1+ (1,0) [0|0] ""  Host
 SG_ PinPullModeStatus_X2_24 : 36|2@1+ (1,0) [0|0] ""  Host
 SG_ LoadDetectionStatus_X2_24 : 38|2@1+ (1,0) [0|0] ""  Host
 SG_ PinModeStatus_X2_25 : 40|4@1+ (1,0) [0|0] ""  Host
 SG_ PinPullModeStatus_X2_25 : 44|2@1+ (1,0) [0|0] ""  Host
 SG_ LoadDetectionStatus_X2_25 : 46|2@1+ (1,0) [0|0] ""  Host
 SG_ PinModeStatus_X2_27 : 48|4@1+ (1,0) [0|0] ""  Host
 SG_ PinPullModeStatus_X2_27 : 52|2@1+ (1,0) [0|0] ""  Host
 SG_ LoadDetectionStatus_X2_27 : 54|2@1+ (1,0) [0|0] ""  Host
 SG_ PinModeStatus_X2_28 : 56|4@1+ (1,0) [0|0] ""  Host
 SG_ PinPullModeStatus_X2_28 : 60|2@1+ (1,0) [0|0] ""  Host
 SG_ LoadDetectionStatus_X2_28 : 62|2@1+ (1,0) [0|0] ""  Host

BO_ 2583647230 IoStatusPinMode3: 8 Device
 SG_ PinModeStatus_X2_11 : 0|4@1+ (1,0) [0|0] ""  Host
 SG_ PinPullModeStatus_X2_11 : 4|2@1+ (1,0) [0|0] ""  Host
 SG_ LoadDetectionStatus_X2_11 : 6|2@1+ (1,0) [0|0] ""  Host
 SG_ PinModeStatus_X2_12 : 8|4@1+ (1,0) [0|0] ""  Host
 SG_ PinPullModeStatus_X2_12 : 12|2@1+ (1,0) [0|0] ""  Host
 SG_ LoadDetectionStatus_X2_12 : 14|2@1+ (1,0) [0|0] ""  Host
 SG_ PinModeStatus_X2_13 : 16|4@1+ (1,0) [0|0] ""  Host
 SG_ PinPullModeStatus_X2_13 : 20|2@1+ (1,0) [0|0] ""  Host
 SG_ LoadDetectionStatus_X2_13 : 22|2@1+ (1,0) [0|0] ""  Host
 SG_ PinModeStatus_X2_14 : 24|4@1+ (1,0) [0|0] ""  Host
 SG_ PinPullModeStatus_X2_14 : 28|2@1+ (1,0) [0|0] ""  Host
 SG_ LoadDetectionStatus_X2_14 : 30|2@1+ (1,0) [0|0] ""  Host
 SG_ PinModeStatus_X2_15 : 32|4@1+ (1,0) [0|0] ""  Host
 SG_ PinPullModeStatus_X2_15 : 36|2@1+ (1,0) [0|0] ""  Host
 SG_ LoadDetectionStatus_X2_15 : 38|2@1+ (1,0) [0|0] ""  Host
 SG_ PinModeStatus_X2_16 : 40|4@1+ (1,0) [0|0] ""  Host
 SG_ PinPullModeStatus_X2_16 : 44|2@1+ (1,0) [0|0] ""  Host
 SG_ LoadDetectionStatus_X2_16 : 46|2@1+ (1,0) [0|0] ""  Host
 SG_ PinModeStatus_X2_17 : 48|4@1+ (1,0) [0|0] ""  Host
 SG_ PinPullModeStatus_X2_17 : 52|2@1+ (1,0) [0|0] ""  Host
 SG_ LoadDetectionStatus_X2_17 : 54|2@1+ (1,0) [0|0] ""  Host
 SG_ PinModeStatus_X2_18 : 56|4@1+ (1,0) [0|0] ""  Host
 SG_ PinPullModeStatus_X2_18 : 60|2@1+ (1,0) [0|0] ""  Host
 SG_ LoadDetectionStatus_X2_18 : 62|2@1+ (1,0) [0|0] ""  Host

BO_ 2582846974 IoStatusPinModeFD: 32 Device
 SG_ PinModeStatus_X1_11 : 0|4@1+ (1,0) [0|0] ""  Host
 SG_ PinPullModeStatus_X1_11 : 4|2@1+ (1,0) [0|0] ""  Host
 SG_ LoadDetectionStatus_X1_11 : 6|2@1+ (1,0) [0|0] ""  Host
 SG_ PinModeStatus_X1_12 : 8|4@1+ (1,0) [0|0] ""  Host
 SG_ PinPullModeStatus_X1_12 : 12|2@1+ (1,0) [0|0] ""  Host
 SG_ LoadDetectionStatus_X1_12 : 14|2@1+ (1,0) [0|0] ""  Host
 SG_ PinModeStatus_X1_13 : 16|4@1+ (1,0) [0|0] ""  Host
 SG_ PinPullModeStatus_X1_13 : 20|2@1+ (1,0) [0|0] ""  Host
 SG_ LoadDetectionStatus_X1_13 : 22|2@1+ (1,0) [0|0] ""  Host
 SG_ PinModeStatus_X1_14 : 24|4@1+ (1,0) [0|0] ""  Host
 SG_ PinPullModeStatus_X1_14 : 28|2@1+ (1,0) [0|0] ""  Host
 SG_ LoadDetectionStatus_X1_14 : 30|2@1+ (1,0) [0|0] ""  Host
 SG_ PinModeStatus_X1_15 : 32|4@1+ (1,0) [0|0] ""  Host
 SG_ PinPullModeStatus_X1_15 : 36|2@1+ (1,0) [0|0] ""  Host
 SG_ LoadDetectionStatus_X1_15 : 38|2@1+ (1,0) [0|0] ""  Host
 SG_ PinModeStatus_X1_16 : 40|4@1+ (1,0) [0|0] ""  Host
 SG_ PinPullModeStatus_X1_16 : 44|2@1+ (1,0) [0|0] ""  Host
 SG_ LoadDetectionStatus_X1_16 : 46|2@1+ (1,0) [0|0] ""  Host
 SG_ PinModeStatus_X1_17 : 48|4@1+ (1,0) [0|0] ""  Host
 SG_ PinPullModeStatus_X1_17 : 52|2@1+ (1,0) [0|0] ""  Host
 SG_ LoadDetectionStatus_X1_17 : 54|2@1+ (1,0) [0|0] ""  Host
 SG_ PinModeStatus_X1_18 : 56|4@1+ (1,0) [0|0] ""  Host
 SG_ PinPullModeStatus_X1_18 : 60|2@1+ (1,0) [0|0] ""  Host
 SG_ LoadDetectionStatus_X1_18 : 62|2@1+ (1,0) [0|0] ""  Host
 SG_ PinModeStatus_X1_24 : 64|4@1+ (1,0) [0|0] ""  Host
 SG_ PinPullModeStatus_X1_24 : 68|2@1+ (1,0) [0|0] ""  Host
 SG_ LoadDetectionStatus_X1_24 : 70|2@1+ (1,0) [0|0] ""  Host
 SG_ PinModeStatus_X1_25 : 72|4@1+ (1,0) [0|0] ""  Host
 SG_ PinPullModeStatus_X1_25 : 76|2@1+ (1,0) [0|0] ""  Host
 SG_ LoadDetectionStatus_X1_25 : 78|2@1+ (1,0) [0|0] ""  Host
 SG_ PinModeStatus_X1_3 : 80|4@1+ (1,0) [0|0] ""  Host
 SG_ PinPullModeStatus_X1_3 : 84|2@1+ (1,0) [0|0] ""  Host
 SG_ LoadDetectionStatus_X1_3 : 86|2@1+ (1,0) [0|0] ""  Host
 SG_ PinModeStatus_X1_4 : 88|4@1+ (1,0) [0|0] ""  Host
 SG_ PinPullModeStatus_X1_4 : 92|2@1+ (1,0) [0|0] ""  Host
 SG_ LoadDetectionStatus_X1_4 : 94|2@1+ (1,0) [0|0] ""  Host
 SG_ PinModeStatus_X2_24 : 96|4@1+ (1,0) [0|0] ""  Host
 SG_ PinPullModeStatus_X2_24 : 100|2@1+ (1,0) [0|0] ""  Host
 SG_ LoadDetectionStatus_X2_24 : 102|2@1+ (1,0) [0|0] ""  Host
 SG_ PinModeStatus_X2_25 : 104|4@1+ (1,0) [0|0] ""  Host
 SG_ PinPullModeStatus_X2_25 : 108|2@1+ (1,0) [0|0] ""  Host
 SG_ LoadDetectionStatus_X2_25 : 110|2@1+ (1,0) [0|0] ""  Host
 SG_ PinModeStatus_X2_27 : 112|4@1+ (1,0) [0|0] ""  Host
 SG_ PinPullModeStatus_X2_27 : 116|2@1+ (1,0) [0|0] ""  Host
 SG_ LoadDetectionStatus_X2_27 : 118|2@1+ (1,0) [0|0] ""  Host
 SG_ PinModeStatus_X2_28 : 120|4@1+ (1,0) [0|0] ""  Host
 SG_ PinPullModeStatus_X2_28 : 124|2@1+ (1,0) [0|0] ""  Host
 SG_ LoadDetectionStatus_X2_28 : 126|2@1+ (1,0) [0|0] ""  Host
 SG_ PinModeStatus_X2_11 : 128|4@1+ (1,0) [0|0] ""  Host
 SG_ PinPullModeStatus_X2_11 : 132|2@1+ (1,0) [0|0] ""  Host
 SG_ LoadDetectionStatus_X2_11 : 134|2@1+ (1,0) [0|0] ""  Host
 SG_ PinModeStatus_X2_12 : 136|4@1+ (1,0) [0|0] ""  Host
 SG_ PinPullModeStatus_X2_12 : 140|2@1+ (1,0) [0|0] ""  Host
 SG_ LoadDetectionStatus_X2_12 : 142|2@1+ (1,0) [0|0] ""  Host
 SG_ PinModeStatus_X2_13 : 144|4@1+ (1,0) [0|0] ""  Host
 SG_ PinPullModeStatus_X2_13 : 148|2@1+ (1,0) [0|0] ""  Host
 SG_ LoadDetectionStatus_X2_13 : 150|2@1+ (1,0) [0|0] ""  Host
 SG_ PinModeStatus_X2_14 : 152|4@1+ (1,0) [0|0] ""  Host
 SG_ PinPullModeStatus_X2_14 : 156|2@1+ (1,0) [0|0] ""  Host
 SG_ LoadDetectionStatus_X2_14 : 158|2@1+ (1,0) [0|0] ""  Host
 SG_ PinModeStatus_X2_15 : 160|4@1+ (1,0) [0|0] ""  Host
 SG_ PinPullModeStatus_X2_15 : 164|2@1+ (1,0) [0|0] ""  Host
 SG_ LoadDetectionStatus_X2_15 : 166|2@1+ (1,0) [0|0] ""  Host
 SG_ PinModeStatus_X2_16 : 168|4@1+ (1,0) [0|0] ""  Host
 SG_ PinPullModeStatus_X2_16 : 172|2@1+ (1,0) [0|0] ""  Host
 SG_ LoadDetectionStatus_X2_16 : 174|2@1+ (1,0) [0|0] ""  Host
 SG_ PinModeStatus_X2_17 : 176|4@1+ (1,0) [0|0] ""  Host
 SG_ PinPullModeStatus_X2_17 : 180|2@1+ (1,0) [0|0] ""  Host
 SG_ LoadDetectionStatus_X2_17 : 182|2@1+ (1,0) [0|0] ""  Host
 SG_ PinModeStatus_X2_18 : 184|4@1+ (1,0) [0|0] ""  Host
 SG_ PinPullModeStatus_X2_18 : 188|2@1+ (1,0) [0|0] ""  Host
 SG_ LoadDetectionStatus_X2_18 : 190|2@1+ (1,0) [0|0] ""  Host

BO_ 2650761214 IoStatusPwmFrequency1: 8 Device
 SG_ PwmFrequencyStatus_X1_11 : 0|16@1+ (0.1,0) [0|6425.5] "Hz"  Host
 SG_ PwmFrequencyStatus_X1_12 : 16|16@1+ (0.1,0) [0|6425.5] "Hz"  Host
 SG_ PwmFrequencyStatus_X1_13 : 32|16@1+ (0.1,0) [0|6425.5] "Hz"  Host
 SG_ PwmFrequencyStatus_X1_14 : 48|16@1+ (0.1,0) [0|6425.5] "Hz"  Host

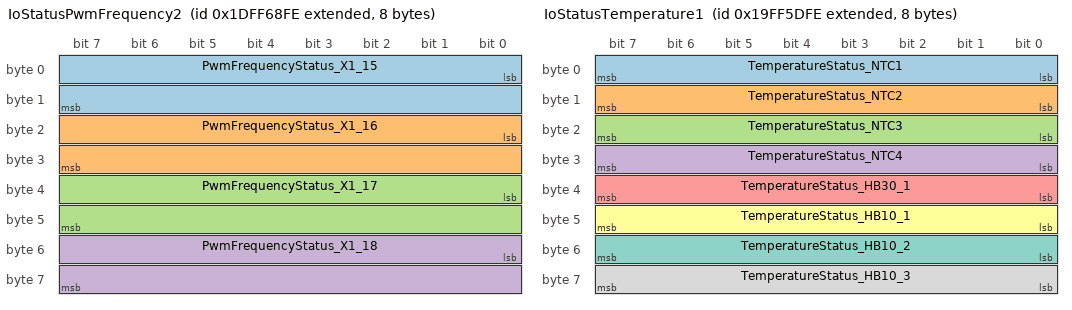
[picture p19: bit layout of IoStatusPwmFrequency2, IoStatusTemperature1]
BO_ 2650761470 IoStatusPwmFrequency2: 8 Device
 SG_ PwmFrequencyStatus_X1_15 : 0|16@1+ (0.1,0) [0|6425.5] "Hz"  Host
 SG_ PwmFrequencyStatus_X1_16 : 16|16@1+ (0.1,0) [0|6425.5] "Hz"  Host
 SG_ PwmFrequencyStatus_X1_17 : 32|16@1+ (0.1,0) [0|6425.5] "Hz"  Host
 SG_ PwmFrequencyStatus_X1_18 : 48|16@1+ (0.1,0) [0|6425.5] "Hz"  Host

BO_ 2650761726 IoStatusPwmFrequency3: 8 Device
 SG_ PwmFrequencyStatus_X1_24 : 0|16@1+ (0.1,0) [0|6425.5] "Hz"  Host
 SG_ PwmFrequencyStatus_X1_25 : 16|16@1+ (0.1,0) [0|6425.5] "Hz"  Host
 SG_ PwmFrequencyStatus_X1_3 : 32|16@1+ (0.1,0) [0|6425.5] "Hz"  Host
 SG_ PwmFrequencyStatus_X1_4 : 48|16@1+ (0.1,0) [0|6425.5] "Hz"  Host

BO_ 2650761982 IoStatusPwmFrequency4: 8 Device
 SG_ PwmFrequencyStatus_X2_24 : 0|16@1+ (0.1,0) [0|6425.5] "Hz"  Host
 SG_ PwmFrequencyStatus_X2_25 : 16|16@1+ (0.1,0) [0|6425.5] "Hz"  Host
 SG_ PwmFrequencyStatus_X2_27 : 32|16@1+ (0.1,0) [0|6425.5] "Hz"  Host

BO_ 2649956094 IoStatusPwmFrequencyFD: 64 Device
 SG_ PwmFrequencyStatus_X1_11 : 0|16@1+ (0.1,0) [0|6425.5] "Hz"  Host
 SG_ PwmFrequencyStatus_X1_12 : 16|16@1+ (0.1,0) [0|6425.5] "Hz"  Host
 SG_ PwmFrequencyStatus_X1_13 : 32|16@1+ (0.1,0) [0|6425.5] "Hz"  Host
 SG_ PwmFrequencyStatus_X1_14 : 48|16@1+ (0.1,0) [0|6425.5] "Hz"  Host
 SG_ PwmFrequencyStatus_X1_15 : 64|16@1+ (0.1,0) [0|6425.5] "Hz"  Host
 SG_ PwmFrequencyStatus_X1_16 : 80|16@1+ (0.1,0) [0|6425.5] "Hz"  Host
 SG_ PwmFrequencyStatus_X1_17 : 96|16@1+ (0.1,0) [0|6425.5] "Hz"  Host
 SG_ PwmFrequencyStatus_X1_18 : 112|16@1+ (0.1,0) [0|6425.5] "Hz"  Host
 SG_ PwmFrequencyStatus_X1_24 : 128|16@1+ (0.1,0) [0|6425.5] "Hz"  Host
 SG_ PwmFrequencyStatus_X1_25 : 144|16@1+ (0.1,0) [0|6425.5] "Hz"  Host
 SG_ PwmFrequencyStatus_X1_3 : 160|16@1+ (0.1,0) [0|6425.5] "Hz"  Host
 SG_ PwmFrequencyStatus_X1_4 : 176|16@1+ (0.1,0) [0|6425.5] "Hz"  Host
 SG_ PwmFrequencyStatus_X2_24 : 192|16@1+ (0.1,0) [0|6425.5] "Hz"  Host
 SG_ PwmFrequencyStatus_X2_25 : 208|16@1+ (0.1,0) [0|6425.5] "Hz"  Host
 SG_ PwmFrequencyStatus_X2_27 : 224|16@1+ (0.1,0) [0|6425.5] "Hz"  Host

BO_ 2582847998 IoStatusQEncoder1: 8 Device
 SG_ QEncoderDirection_Q01 : 0|2@1+ (1,0) [0|0] ""  Host
 SG_ QEncoderCounter_Q01 : 8|24@1+ (1,-8000000) [-8000000|8000000] ""  Host

BO_ 2583649790 IoStatusTemperature1: 8 Device
 SG_ TemperatureStatus_NTC1 : 0|8@1+ (1,-40) [-40|210] "C"  Host
 SG_ TemperatureStatus_NTC2 : 8|8@1+ (1,-40) [-40|210] "C"  Host
 SG_ TemperatureStatus_NTC3 : 16|8@1+ (1,-40) [-40|210] "C"  Host
 SG_ TemperatureStatus_NTC4 : 24|8@1+ (1,-40) [-40|210] "C"  Host
 SG_ TemperatureStatus_HB30_1 : 32|8@1+ (1,-40) [-40|210] "C"  Host
 SG_ TemperatureStatus_HB10_1 : 40|8@1+ (1,-40) [-40|210] "C"  Host
 SG_ TemperatureStatus_HB10_2 : 48|8@1+ (1,-40) [-40|210] "C"  Host
 SG_ TemperatureStatus_HB10_3 : 56|8@1+ (1,-40) [-40|210] "C"  Host

CM_ "Universal IO (UIO) messages
$File: //system_software/components/boards/IO_V4_A/0.36.1.0/dbc/IO_A_v4.dbc $
$Change: 214332 $
$DateTime: 2024/07/01 06:45:19 $
$Revision: #1 $";
CM_ BO_ 2369322750 "Bridge management command";
CM_ BO_ 2369650430 "Comand to change pin duty value. This value will be used if pin on HighSide, LowSide or Bridge mode.";
CM_ BO_ 2369715966 "Comand to change pin duty value. This value will be used if pin on HighSide, LowSide or Bridge mode.";
CM_ BO_ 2370043646 "Comand to change pin duty value. This value will be used if pin on HighSide, LowSide or Bridge mode.";
CM_ BO_ 2369388286 "Command to change pin mode on fly";
CM_ SG_ 2369388286 PinModeCommand_X1_11 "Pin mode Command";
CM_ SG_ 2369388286 PinPullModeCommand_X1_11 "Pin pullup/pulldown mode Command";
CM_ SG_ 2369388286 LoadDetectionCommand_X1_11 "Enable/disable load detection diagnostic";
CM_ SG_ 2369388286 PinModeCommand_X1_12 "Pin mode Command";
CM_ SG_ 2369388286 PinPullModeCommand_X1_12 "Pin pullup/pulldown mode Command";
CM_ SG_ 2369388286 LoadDetectionCommand_X1_12 "Enable/disable load detection diagnostic";
CM_ SG_ 2369388286 PinModeCommand_X1_13 "Pin mode Command";
CM_ SG_ 2369388286 PinPullModeCommand_X1_13 "Pin pullup/pulldown mode Command";
CM_ SG_ 2369388286 LoadDetectionCommand_X1_13 "Enable/disable load detection diagnostic";
CM_ SG_ 2369388286 PinModeCommand_X1_14 "Pin mode Command";
CM_ SG_ 2369388286 PinPullModeCommand_X1_14 "Pin pullup/pulldown mode Command";
CM_ SG_ 2369388286 LoadDetectionCommand_X1_14 "Enable/disable load detection diagnostic";
CM_ SG_ 2369388286 PinModeCommand_X1_15 "Pin mode Command";
CM_ SG_ 2369388286 PinPullModeCommand_X1_15 "Pin pullup/pulldown mode Command";
CM_ SG_ 2369388286 LoadDetectionCommand_X1_15 "Enable/disable load detection diagnostic";
CM_ SG_ 2369388286 PinModeCommand_X1_16 "Pin mode Command";
CM_ SG_ 2369388286 PinPullModeCommand_X1_16 "Pin pullup/pulldown mode Command";
CM_ SG_ 2369388286 LoadDetectionCommand_X1_16 "Enable/disable load detection diagnostic";
CM_ SG_ 2369388286 PinModeCommand_X1_17 "Pin mode Command";
CM_ SG_ 2369388286 PinPullModeCommand_X1_17 "Pin pullup/pulldown mode Command";
CM_ SG_ 2369388286 LoadDetectionCommand_X1_17 "Enable/disable load detection diagnostic";
CM_ SG_ 2369388286 PinModeCommand_X1_18 "Pin mode Command";
CM_ SG_ 2369388286 PinPullModeCommand_X1_18 "Pin pullup/pulldown mode Command";
CM_ SG_ 2369388286 LoadDetectionCommand_X1_18 "Enable/disable load detection diagnostic";
CM_ BO_ 2369453822 "Command to change pin mode on fly";
CM_ SG_ 2369453822 PinModeCommand_X1_24 "Pin mode Command";
CM_ SG_ 2369453822 PinPullModeCommand_X1_24 "Pin pullup/pulldown mode Command";
CM_ SG_ 2369453822 LoadDetectionCommand_X1_24 "Enable/disable load detection diagnostic";
CM_ SG_ 2369453822 PinModeCommand_X1_25 "Pin mode Command";
CM_ SG_ 2369453822 PinPullModeCommand_X1_25 "Pin pullup/pulldown mode Command";
CM_ SG_ 2369453822 LoadDetectionCommand_X1_25 "Enable/disable load detection diagnostic";
CM_ SG_ 2369453822 PinModeCommand_X1_3 "Pin mode Command";
CM_ SG_ 2369453822 PinPullModeCommand_X1_3 "Pin pullup/pulldown mode Command";
CM_ SG_ 2369453822 LoadDetectionCommand_X1_3 "Enable/disable load detection diagnostic";
CM_ SG_ 2369453822 PinModeCommand_X1_4 "Pin mode Command";
CM_ SG_ 2369453822 PinPullModeCommand_X1_4 "Pin pullup/pulldown mode Command";
CM_ SG_ 2369453822 LoadDetectionCommand_X1_4 "Enable/disable load detection diagnostic";
CM_ SG_ 2369453822 PinModeCommand_X2_24 "Pin mode Command";
CM_ SG_ 2369453822 PinPullModeCommand_X2_24 "Pin pullup/pulldown mode Command";
CM_ SG_ 2369453822 LoadDetectionCommand_X2_24 "Enable/disable load detection diagnostic";
CM_ SG_ 2369453822 PinModeCommand_X2_25 "Pin mode Command";
CM_ SG_ 2369453822 PinPullModeCommand_X2_25 "Pin pullup/pulldown mode Command";
CM_ SG_ 2369453822 LoadDetectionCommand_X2_25 "Enable/disable load detection diagnostic";
CM_ SG_ 2369453822 PinModeCommand_X2_27 "Pin mode Command";
CM_ SG_ 2369453822 PinPullModeCommand_X2_27 "Pin pullup/pulldown mode Command";
CM_ SG_ 2369453822 LoadDetectionCommand_X2_27 "Enable/disable load detection diagnostic";
CM_ SG_ 2369453822 PinModeCommand_X2_28 "Pin mode Command";
CM_ SG_ 2369453822 PinPullModeCommand_X2_28 "Pin pullup/pulldown mode Command";
CM_ SG_ 2369453822 LoadDetectionCommand_X2_28 "Enable/disable load detection diagnostic";
CM_ BO_ 2369519358 "Command to change pin mode on fly";
CM_ SG_ 2369519358 PinModeCommand_X2_11 "Pin mode Command";
CM_ SG_ 2369519358 PinPullModeCommand_X2_11 "Pin pullup/pulldown mode Command";
CM_ SG_ 2369519358 LoadDetectionCommand_X2_11 "Enable/disable load detection diagnostic";
CM_ SG_ 2369519358 PinModeCommand_X2_12 "Pin mode Command";
CM_ SG_ 2369519358 PinPullModeCommand_X2_12 "Pin pullup/pulldown mode Command";
CM_ SG_ 2369519358 LoadDetectionCommand_X2_12 "Enable/disable load detection diagnostic";
CM_ SG_ 2369519358 PinModeCommand_X2_13 "Pin mode Command";
CM_ SG_ 2369519358 PinPullModeCommand_X2_13 "Pin pullup/pulldown mode Command";
CM_ SG_ 2369519358 LoadDetectionCommand_X2_13 "Enable/disable load detection diagnostic";
CM_ SG_ 2369519358 PinModeCommand_X2_14 "Pin mode Command";
CM_ SG_ 2369519358 PinPullModeCommand_X2_14 "Pin pullup/pulldown mode Command";
CM_ SG_ 2369519358 LoadDetectionCommand_X2_14 "Enable/disable load detection diagnostic";
CM_ SG_ 2369519358 PinModeCommand_X2_15 "Pin mode Command";
CM_ SG_ 2369519358 PinPullModeCommand_X2_15 "Pin pullup/pulldown mode Command";
CM_ SG_ 2369519358 LoadDetectionCommand_X2_15 "Enable/disable load detection diagnostic";
CM_ SG_ 2369519358 PinModeCommand_X2_16 "Pin mode Command";
CM_ SG_ 2369519358 PinPullModeCommand_X2_16 "Pin pullup/pulldown mode Command";
CM_ SG_ 2369519358 LoadDetectionCommand_X2_16 "Enable/disable load detection diagnostic";
CM_ SG_ 2369519358 PinModeCommand_X2_17 "Pin mode Command";
CM_ SG_ 2369519358 PinPullModeCommand_X2_17 "Pin pullup/pulldown mode Command";
CM_ SG_ 2369519358 LoadDetectionCommand_X2_17 "Enable/disable load detection diagnostic";
CM_ SG_ 2369519358 PinModeCommand_X2_18 "Pin mode Command";
CM_ SG_ 2369519358 PinPullModeCommand_X2_18 "Pin pullup/pulldown mode Command";
CM_ SG_ 2369519358 LoadDetectionCommand_X2_18 "Enable/disable load detection diagnostic";
CM_ BO_ 2369912574 "Comand to change pin PWM frequency value. This value will be used if pin on HighSide, LowSide or Bridge mode.";
CM_ BO_ 2583656702 "Measured frequency on inputs 1";
CM_ SG_ 2583656702 PinDutyStatus_X1_11 "Measured PWM duty in input";
CM_ SG_ 2583656702 PinDutyStatus_X1_12 "Measured PWM duty in input";
CM_ SG_ 2583656702 PinDutyStatus_X1_13 "Measured PWM duty in input";
CM_ SG_ 2583656702 PinDutyStatus_X1_14 "Measured PWM duty in input";
CM_ BO_ 2583656446 "Measured frequency on inputs 1";
CM_ SG_ 2583656446 PinFrequencyStatus_X1_11 "Measured frequency on input 01";
CM_ SG_ 2583656446 PinFrequencyStatus_X1_12 "Measured frequency on input 02";
CM_ SG_ 2583656446 PinFrequencyStatus_X1_13 "Measured frequency on input 03";
CM_ SG_ 2583656446 PinFrequencyStatus_X1_14 "Measured frequency on input 04";
CM_ BO_ 2583656190 "Bridge status";
CM_ BO_ 2583647742 "Measured output current";
CM_ BO_ 2583647998 "Measured output current";
CM_ BO_ 2583648254 "Measured output current";
CM_ BO_ 2583648510 "Measured output current";
CM_ BO_ 2582845950 "Measured output current";
CM_ BO_ 2583648766 "Diagnostic state";
CM_ BO_ 2583649022 "Diagnostic state";
CM_ BO_ 2582847486 "Diagnostic state";
CM_ BO_ 2583651326 "Current configured output duty value";
CM_ SG_ 2583651326 DutyStatus_X1_11 "Configured PWM duty on output";
CM_ SG_ 2583651326 DutyStatus_X1_12 "Configured PWM duty on output";
CM_ SG_ 2583651326 DutyStatus_X1_13 "Configured PWM duty on output";
CM_ SG_ 2583651326 DutyStatus_X1_14 "Configured PWM duty on output";
CM_ SG_ 2583651326 DutyStatus_X1_15 "Configured PWM duty on output";
CM_ SG_ 2583651326 DutyStatus_X1_16 "Configured PWM duty on output";
CM_ SG_ 2583651326 DutyStatus_X1_17 "Configured PWM duty on output";
CM_ SG_ 2583651326 DutyStatus_X1_18 "Configured PWM duty on output";
CM_ BO_ 2583651582 "Current configured output duty value";
CM_ SG_ 2583651582 DutyStatus_X1_24 "Configured PWM duty on output";
CM_ SG_ 2583651582 DutyStatus_X1_25 "Configured PWM duty on output";
CM_ SG_ 2583651582 DutyStatus_X1_3 "Configured PWM duty on output";
CM_ SG_ 2583651582 DutyStatus_X1_4 "Configured PWM duty on output";
CM_ SG_ 2583651582 DutyStatus_X2_24 "Configured PWM duty on output";
CM_ SG_ 2583651582 DutyStatus_X2_25 "Configured PWM duty on output";
CM_ SG_ 2583651582 DutyStatus_X2_27 "Configured PWM duty on output";
CM_ SG_ 2583651582 DutyStatus_X2_28 "Configured PWM duty on output";
CM_ BO_ 2582847742 "Current configured output duty value";
CM_ SG_ 2582847742 DutyStatus_X1_11 "Configured PWM duty on output";
CM_ SG_ 2582847742 DutyStatus_X1_12 "Configured PWM duty on output";
CM_ SG_ 2582847742 DutyStatus_X1_13 "Configured PWM duty on output";
CM_ SG_ 2582847742 DutyStatus_X1_14 "Configured PWM duty on output";
CM_ SG_ 2582847742 DutyStatus_X1_15 "Configured PWM duty on output";
CM_ SG_ 2582847742 DutyStatus_X1_16 "Configured PWM duty on output";
CM_ SG_ 2582847742 DutyStatus_X1_17 "Configured PWM duty on output";
CM_ SG_ 2582847742 DutyStatus_X1_18 "Configured PWM duty on output";
CM_ SG_ 2582847742 DutyStatus_X1_24 "Configured PWM duty on output";
CM_ SG_ 2582847742 DutyStatus_X1_25 "Configured PWM duty on output";
CM_ SG_ 2582847742 DutyStatus_X1_3 "Configured PWM duty on output";
CM_ SG_ 2582847742 DutyStatus_X1_4 "Configured PWM duty on output";
CM_ SG_ 2582847742 DutyStatus_X2_24 "Configured PWM duty on output";
CM_ SG_ 2582847742 DutyStatus_X2_25 "Configured PWM duty on output";
CM_ SG_ 2582847742 DutyStatus_X2_27 "Configured PWM duty on output";
CM_ SG_ 2582847742 DutyStatus_X2_28 "Configured PWM duty on output";
CM_ BO_ 2582843646 "Faults count";
CM_ SG_ 2582843646 FaultCountStatus_X1_11 "Detected faults count";
CM_ SG_ 2582843646 FaultCountStatus_X1_12 "Detected faults count";
CM_ SG_ 2582843646 FaultCountStatus_X1_13 "Detected faults count";
CM_ SG_ 2582843646 FaultCountStatus_X1_14 "Detected faults count";
CM_ BO_ 2582843902 "Faults count";
CM_ SG_ 2582843902 FaultCountStatus_X1_15 "Detected faults count";
CM_ SG_ 2582843902 FaultCountStatus_X1_16 "Detected faults count";
CM_ SG_ 2582843902 FaultCountStatus_X1_17 "Detected faults count";
CM_ SG_ 2582843902 FaultCountStatus_X1_18 "Detected faults count";
CM_ BO_ 2582844158 "Faults count";
CM_ SG_ 2582844158 FaultCountStatus_X1_24 "Detected faults count";
CM_ SG_ 2582844158 FaultCountStatus_X1_25 "Detected faults count";
CM_ SG_ 2582844158 FaultCountStatus_X1_3 "Detected faults count";
CM_ SG_ 2582844158 FaultCountStatus_X1_4 "Detected faults count";
CM_ BO_ 2582844414 "Faults count";
CM_ SG_ 2582844414 FaultCountStatus_X2_24 "Detected faults count";
CM_ SG_ 2582844414 FaultCountStatus_X2_25 "Detected faults count";
CM_ SG_ 2582844414 FaultCountStatus_X2_27 "Detected faults count";
CM_ SG_ 2582844414 FaultCountStatus_X2_28 "Detected faults count";
CM_ BO_ 2582844670 "Faults count";
CM_ SG_ 2582844670 FaultCountStatus_X2_11 "Detected faults count";
CM_ SG_ 2582844670 FaultCountStatus_X2_12 "Detected faults count";
CM_ SG_ 2582844670 FaultCountStatus_X2_13 "Detected faults count";
CM_ SG_ 2582844670 FaultCountStatus_X2_14 "Detected faults count";
CM_ BO_ 2582844926 "Faults count";
CM_ SG_ 2582844926 FaultCountStatus_X2_15 "Detected faults count";
CM_ SG_ 2582844926 FaultCountStatus_X2_16 "Detected faults count";
CM_ SG_ 2582844926 FaultCountStatus_X2_17 "Detected faults count";
CM_ SG_ 2582844926 FaultCountStatus_X2_18 "Detected faults count";
CM_ BO_ 2582846206 "Faults count";
CM_ SG_ 2582846206 FaultCountStatus_X1_11 "Detected faults count";
CM_ SG_ 2582846206 FaultCountStatus_X1_12 "Detected faults count";
CM_ SG_ 2582846206 FaultCountStatus_X1_13 "Detected faults count";
CM_ SG_ 2582846206 FaultCountStatus_X1_14 "Detected faults count";
CM_ SG_ 2582846206 FaultCountStatus_X1_15 "Detected faults count";
CM_ SG_ 2582846206 FaultCountStatus_X1_16 "Detected faults count";
CM_ SG_ 2582846206 FaultCountStatus_X1_17 "Detected faults count";
CM_ SG_ 2582846206 FaultCountStatus_X1_18 "Detected faults count";
CM_ SG_ 2582846206 FaultCountStatus_X1_24 "Detected faults count";
CM_ SG_ 2582846206 FaultCountStatus_X1_25 "Detected faults count";
CM_ SG_ 2582846206 FaultCountStatus_X1_3 "Detected faults count";
CM_ SG_ 2582846206 FaultCountStatus_X1_4 "Detected faults count";
CM_ SG_ 2582846206 FaultCountStatus_X2_24 "Detected faults count";
CM_ SG_ 2582846206 FaultCountStatus_X2_25 "Detected faults count";
CM_ SG_ 2582846206 FaultCountStatus_X2_27 "Detected faults count";
CM_ SG_ 2582846206 FaultCountStatus_X2_28 "Detected faults count";
CM_ SG_ 2582846206 FaultCountStatus_X2_11 "Detected faults count";
CM_ SG_ 2582846206 FaultCountStatus_X2_12 "Detected faults count";
CM_ SG_ 2582846206 FaultCountStatus_X2_13 "Detected faults count";
CM_ SG_ 2582846206 FaultCountStatus_X2_14 "Detected faults count";
CM_ SG_ 2582846206 FaultCountStatus_X2_15 "Detected faults count";
CM_ SG_ 2582846206 FaultCountStatus_X2_16 "Detected faults count";
CM_ SG_ 2582846206 FaultCountStatus_X2_17 "Detected faults count";
CM_ SG_ 2582846206 FaultCountStatus_X2_18 "Detected faults count";
CM_ BO_ 2582839550 "Measured output current when fault occured";
CM_ SG_ 2582839550 FaultCurrentStatus_X1_11 "Measured current when fault detected";
CM_ SG_ 2582839550 FaultCurrentStatus_X1_12 "Measured current when fault detected";
CM_ SG_ 2582839550 FaultCurrentStatus_X1_13 "Measured current when fault detected";
CM_ SG_ 2582839550 FaultCurrentStatus_X1_14 "Measured current when fault detected";
CM_ BO_ 2582839806 "Measured output current when fault occured";
CM_ SG_ 2582839806 FaultCurrentStatus_X1_15 "Measured current when fault detected";
CM_ SG_ 2582839806 FaultCurrentStatus_X1_16 "Measured current when fault detected";
CM_ SG_ 2582839806 FaultCurrentStatus_X1_17 "Measured current when fault detected";
CM_ SG_ 2582839806 FaultCurrentStatus_X1_18 "Measured current when fault detected";
CM_ BO_ 2582840062 "Measured output current when fault occured";
CM_ SG_ 2582840062 FaultCurrentStatus_X1_24 "Measured current when fault detected";
CM_ SG_ 2582840062 FaultCurrentStatus_X1_25 "Measured current when fault detected";
CM_ SG_ 2582840062 FaultCurrentStatus_X1_3 "Measured current when fault detected";
CM_ SG_ 2582840062 FaultCurrentStatus_X1_4 "Measured current when fault detected";
CM_ BO_ 2582840318 "Measured output current when fault occured";
CM_ SG_ 2582840318 FaultCurrentStatus_X2_24 "Measured current when fault detected";
CM_ SG_ 2582840318 FaultCurrentStatus_X2_25 "Measured current when fault detected";
CM_ SG_ 2582840318 FaultCurrentStatus_X2_27 "Measured current when fault detected";
CM_ SG_ 2582840318 FaultCurrentStatus_X2_28 "Measured current when fault detected";
CM_ BO_ 2582846462 "Measured output current when fault occured";
CM_ SG_ 2582846462 FaultCurrentStatus_X1_11 "Measured current when fault detected";
CM_ SG_ 2582846462 FaultCurrentStatus_X1_12 "Measured current when fault detected";
CM_ SG_ 2582846462 FaultCurrentStatus_X1_13 "Measured current when fault detected";
CM_ SG_ 2582846462 FaultCurrentStatus_X1_14 "Measured current when fault detected";
CM_ SG_ 2582846462 FaultCurrentStatus_X1_15 "Measured current when fault detected";
CM_ SG_ 2582846462 FaultCurrentStatus_X1_16 "Measured current when fault detected";
CM_ SG_ 2582846462 FaultCurrentStatus_X1_17 "Measured current when fault detected";
CM_ SG_ 2582846462 FaultCurrentStatus_X1_18 "Measured current when fault detected";
CM_ SG_ 2582846462 FaultCurrentStatus_X1_24 "Measured current when fault detected";
CM_ SG_ 2582846462 FaultCurrentStatus_X1_25 "Measured current when fault detected";
CM_ SG_ 2582846462 FaultCurrentStatus_X1_3 "Measured current when fault detected";
CM_ SG_ 2582846462 FaultCurrentStatus_X1_4 "Measured current when fault detected";
CM_ SG_ 2582846462 FaultCurrentStatus_X2_24 "Measured current when fault detected";
CM_ SG_ 2582846462 FaultCurrentStatus_X2_25 "Measured current when fault detected";
CM_ SG_ 2582846462 FaultCurrentStatus_X2_27 "Measured current when fault detected";
CM_ SG_ 2582846462 FaultCurrentStatus_X2_28 "Measured current when fault detected";
CM_ BO_ 2582841598 "Measured input voltage when fault occured";
CM_ SG_ 2582841598 FaultVoltageStatus_X1_11 "Measured voltage when fault occured";
CM_ SG_ 2582841598 FaultVoltageStatus_X1_12 "Measured voltage when fault occured";
CM_ SG_ 2582841598 FaultVoltageStatus_X1_13 "Measured voltage when fault occured";
CM_ SG_ 2582841598 FaultVoltageStatus_X1_14 "Measured voltage when fault occured";
CM_ BO_ 2582841854 "Measured input voltage when fault occured";
CM_ SG_ 2582841854 FaultVoltageStatus_X1_15 "Measured voltage when fault occured";
CM_ SG_ 2582841854 FaultVoltageStatus_X1_16 "Measured voltage when fault occured";
CM_ SG_ 2582841854 FaultVoltageStatus_X1_17 "Measured voltage when fault occured";
CM_ SG_ 2582841854 FaultVoltageStatus_X1_18 "Measured voltage when fault occured";
CM_ BO_ 2582842110 "Measured input voltage when fault occured";
CM_ SG_ 2582842110 FaultVoltageStatus_X1_24 "Measured voltage when fault occured";
CM_ SG_ 2582842110 FaultVoltageStatus_X1_25 "Measured voltage when fault occured";
CM_ SG_ 2582842110 FaultVoltageStatus_X1_3 "Measured voltage when fault occured";
CM_ SG_ 2582842110 FaultVoltageStatus_X1_4 "Measured voltage when fault occured";
CM_ BO_ 2582842366 "Measured input voltage when fault occured";
CM_ SG_ 2582842366 FaultVoltageStatus_X2_24 "Measured voltage when fault occured";
CM_ SG_ 2582842366 FaultVoltageStatus_X2_25 "Measured voltage when fault occured";
CM_ SG_ 2582842366 FaultVoltageStatus_X2_27 "Measured voltage when fault occured";
CM_ SG_ 2582842366 FaultVoltageStatus_X2_28 "Measured voltage when fault occured";
CM_ BO_ 2582842622 "Measured input voltage when fault occured";
CM_ SG_ 2582842622 FaultVoltageStatus_X2_11 "Measured voltage when fault occured";
CM_ SG_ 2582842622 FaultVoltageStatus_X2_12 "Measured voltage when fault occured";
CM_ SG_ 2582842622 FaultVoltageStatus_X2_13 "Measured voltage when fault occured";
CM_ SG_ 2582842622 FaultVoltageStatus_X2_14 "Measured voltage when fault occured";
CM_ BO_ 2582842878 "Measured input voltage when fault occured";
CM_ SG_ 2582842878 FaultVoltageStatus_X2_15 "Measured voltage when fault occured";
CM_ SG_ 2582842878 FaultVoltageStatus_X2_16 "Measured voltage when fault occured";
CM_ SG_ 2582842878 FaultVoltageStatus_X2_17 "Measured voltage when fault occured";
CM_ SG_ 2582842878 FaultVoltageStatus_X2_18 "Measured voltage when fault occured";
CM_ BO_ 2582846718 "Measured input voltage when fault occured";
CM_ SG_ 2582846718 FaultVoltageStatus_X1_11 "Measured voltage when fault occured";
CM_ SG_ 2582846718 FaultVoltageStatus_X1_12 "Measured voltage when fault occured";
CM_ SG_ 2582846718 FaultVoltageStatus_X1_13 "Measured voltage when fault occured";
CM_ SG_ 2582846718 FaultVoltageStatus_X1_14 "Measured voltage when fault occured";
CM_ SG_ 2582846718 FaultVoltageStatus_X1_15 "Measured voltage when fault occured";
CM_ SG_ 2582846718 FaultVoltageStatus_X1_16 "Measured voltage when fault occured";
CM_ SG_ 2582846718 FaultVoltageStatus_X1_17 "Measured voltage when fault occured";
CM_ SG_ 2582846718 FaultVoltageStatus_X1_18 "Measured voltage when fault occured";
CM_ SG_ 2582846718 FaultVoltageStatus_X1_24 "Measured voltage when fault occured";
CM_ SG_ 2582846718 FaultVoltageStatus_X1_25 "Measured voltage when fault occured";
CM_ SG_ 2582846718 FaultVoltageStatus_X1_3 "Measured voltage when fault occured";
CM_ SG_ 2582846718 FaultVoltageStatus_X1_4 "Measured voltage when fault occured";
CM_ SG_ 2582846718 FaultVoltageStatus_X2_24 "Measured voltage when fault occured";
CM_ SG_ 2582846718 FaultVoltageStatus_X2_25 "Measured voltage when fault occured";
CM_ SG_ 2582846718 FaultVoltageStatus_X2_27 "Measured voltage when fault occured";
CM_ SG_ 2582846718 FaultVoltageStatus_X2_28 "Measured voltage when fault occured";
CM_ SG_ 2582846718 FaultVoltageStatus_X2_11 "Measured voltage when fault occured";
CM_ SG_ 2582846718 FaultVoltageStatus_X2_12 "Measured voltage when fault occured";
CM_ SG_ 2582846718 FaultVoltageStatus_X2_13 "Measured voltage when fault occured";
CM_ SG_ 2582846718 FaultVoltageStatus_X2_14 "Measured voltage when fault occured";
CM_ SG_ 2582846718 FaultVoltageStatus_X2_15 "Measured voltage when fault occured";
CM_ SG_ 2582846718 FaultVoltageStatus_X2_16 "Measured voltage when fault occured";
CM_ SG_ 2582846718 FaultVoltageStatus_X2_17 "Measured voltage when fault occured";
CM_ SG_ 2582846718 FaultVoltageStatus_X2_18 "Measured voltage when fault occured";
CM_ BO_ 2583650046 "Measured inputs voltages";
CM_ BO_ 2583650302 "Measured inputs voltages";
CM_ BO_ 2583650558 "Measured inputs voltages";
CM_ BO_ 2583650814 "Measured inputs voltages";
CM_ BO_ 2583651070 "Measured inputs voltages";
CM_ BO_ 2583654398 "Measured inputs voltages";
CM_ BO_ 2582845694 "Measured inputs voltages";
CM_ BO_ 2583646718 "This mesage reports current pin mode";
CM_ SG_ 2583646718 PinModeStatus_X1_11 "Pin mode status";
CM_ SG_ 2583646718 PinPullModeStatus_X1_11 "Pin pullup/pulldown mode status";
CM_ SG_ 2583646718 LoadDetectionStatus_X1_11 "Report status of enabled/disabled load detection mode";
CM_ SG_ 2583646718 PinModeStatus_X1_12 "Pin mode status";
CM_ SG_ 2583646718 PinPullModeStatus_X1_12 "Pin pullup/pulldown mode status";
CM_ SG_ 2583646718 LoadDetectionStatus_X1_12 "Report status of enabled/disabled load detection mode";
CM_ SG_ 2583646718 PinModeStatus_X1_13 "Pin mode status";
CM_ SG_ 2583646718 PinPullModeStatus_X1_13 "Pin pullup/pulldown mode status";
CM_ SG_ 2583646718 LoadDetectionStatus_X1_13 "Report status of enabled/disabled load detection mode";
CM_ SG_ 2583646718 PinModeStatus_X1_14 "Pin mode status";
CM_ SG_ 2583646718 PinPullModeStatus_X1_14 "Pin pullup/pulldown mode status";
CM_ SG_ 2583646718 LoadDetectionStatus_X1_14 "Report status of enabled/disabled load detection mode";
CM_ SG_ 2583646718 PinModeStatus_X1_15 "Pin mode status";
CM_ SG_ 2583646718 PinPullModeStatus_X1_15 "Pin pullup/pulldown mode status";
CM_ SG_ 2583646718 LoadDetectionStatus_X1_15 "Report status of enabled/disabled load detection mode";
CM_ SG_ 2583646718 PinModeStatus_X1_16 "Pin mode status";
CM_ SG_ 2583646718 PinPullModeStatus_X1_16 "Pin pullup/pulldown mode status";
CM_ SG_ 2583646718 LoadDetectionStatus_X1_16 "Report status of enabled/disabled load detection mode";
CM_ SG_ 2583646718 PinModeStatus_X1_17 "Pin mode status";
CM_ SG_ 2583646718 PinPullModeStatus_X1_17 "Pin pullup/pulldown mode status";
CM_ SG_ 2583646718 LoadDetectionStatus_X1_17 "Report status of enabled/disabled load detection mode";
CM_ SG_ 2583646718 PinModeStatus_X1_18 "Pin mode status";
CM_ SG_ 2583646718 PinPullModeStatus_X1_18 "Pin pullup/pulldown mode status";
CM_ SG_ 2583646718 LoadDetectionStatus_X1_18 "Report status of enabled/disabled load detection mode";
CM_ BO_ 2583646974 "This mesage reports current pin mode";
CM_ SG_ 2583646974 PinModeStatus_X1_24 "Pin mode status";
CM_ SG_ 2583646974 PinPullModeStatus_X1_24 "Pin pullup/pulldown mode status";
CM_ SG_ 2583646974 LoadDetectionStatus_X1_24 "Report status of enabled/disabled load detection mode";
CM_ SG_ 2583646974 PinModeStatus_X1_25 "Pin mode status";
CM_ SG_ 2583646974 PinPullModeStatus_X1_25 "Pin pullup/pulldown mode status";
CM_ SG_ 2583646974 LoadDetectionStatus_X1_25 "Report status of enabled/disabled load detection mode";
CM_ SG_ 2583646974 PinModeStatus_X1_3 "Pin mode status";
CM_ SG_ 2583646974 PinPullModeStatus_X1_3 "Pin pullup/pulldown mode status";
CM_ SG_ 2583646974 LoadDetectionStatus_X1_3 "Report status of enabled/disabled load detection mode";
CM_ SG_ 2583646974 PinModeStatus_X1_4 "Pin mode status";
CM_ SG_ 2583646974 PinPullModeStatus_X1_4 "Pin pullup/pulldown mode status";
CM_ SG_ 2583646974 LoadDetectionStatus_X1_4 "Report status of enabled/disabled load detection mode";
CM_ SG_ 2583646974 PinModeStatus_X2_24 "Pin mode status";
CM_ SG_ 2583646974 PinPullModeStatus_X2_24 "Pin pullup/pulldown mode status";
CM_ SG_ 2583646974 LoadDetectionStatus_X2_24 "Report status of enabled/disabled load detection mode";
CM_ SG_ 2583646974 PinModeStatus_X2_25 "Pin mode status";
CM_ SG_ 2583646974 PinPullModeStatus_X2_25 "Pin pullup/pulldown mode status";
CM_ SG_ 2583646974 LoadDetectionStatus_X2_25 "Report status of enabled/disabled load detection mode";
CM_ SG_ 2583646974 PinModeStatus_X2_27 "Pin mode status";
CM_ SG_ 2583646974 PinPullModeStatus_X2_27 "Pin pullup/pulldown mode status";
CM_ SG_ 2583646974 LoadDetectionStatus_X2_27 "Report status of enabled/disabled load detection mode";
CM_ SG_ 2583646974 PinModeStatus_X2_28 "Pin mode status";
CM_ SG_ 2583646974 PinPullModeStatus_X2_28 "Pin pullup/pulldown mode status";
CM_ SG_ 2583646974 LoadDetectionStatus_X2_28 "Report status of enabled/disabled load detection mode";
CM_ BO_ 2583647230 "This mesage reports current pin mode";
CM_ SG_ 2583647230 PinModeStatus_X2_11 "Pin mode status";
CM_ SG_ 2583647230 PinPullModeStatus_X2_11 "Pin pullup/pulldown mode status";
CM_ SG_ 2583647230 LoadDetectionStatus_X2_11 "Report status of enabled/disabled load detection mode";
CM_ SG_ 2583647230 PinModeStatus_X2_12 "Pin mode status";
CM_ SG_ 2583647230 PinPullModeStatus_X2_12 "Pin pullup/pulldown mode status";
CM_ SG_ 2583647230 LoadDetectionStatus_X2_12 "Report status of enabled/disabled load detection mode";
CM_ SG_ 2583647230 PinModeStatus_X2_13 "Pin mode status";
CM_ SG_ 2583647230 PinPullModeStatus_X2_13 "Pin pullup/pulldown mode status";
CM_ SG_ 2583647230 LoadDetectionStatus_X2_13 "Report status of enabled/disabled load detection mode";
CM_ SG_ 2583647230 PinModeStatus_X2_14 "Pin mode status";
CM_ SG_ 2583647230 PinPullModeStatus_X2_14 "Pin pullup/pulldown mode status";
CM_ SG_ 2583647230 LoadDetectionStatus_X2_14 "Report status of enabled/disabled load detection mode";
CM_ SG_ 2583647230 PinModeStatus_X2_15 "Pin mode status";
CM_ SG_ 2583647230 PinPullModeStatus_X2_15 "Pin pullup/pulldown mode status";
CM_ SG_ 2583647230 LoadDetectionStatus_X2_15 "Report status of enabled/disabled load detection mode";
CM_ SG_ 2583647230 PinModeStatus_X2_16 "Pin mode status";
CM_ SG_ 2583647230 PinPullModeStatus_X2_16 "Pin pullup/pulldown mode status";
CM_ SG_ 2583647230 LoadDetectionStatus_X2_16 "Report status of enabled/disabled load detection mode";
CM_ SG_ 2583647230 PinModeStatus_X2_17 "Pin mode status";
CM_ SG_ 2583647230 PinPullModeStatus_X2_17 "Pin pullup/pulldown mode status";
CM_ SG_ 2583647230 LoadDetectionStatus_X2_17 "Report status of enabled/disabled load detection mode";
CM_ SG_ 2583647230 PinModeStatus_X2_18 "Pin mode status";
CM_ SG_ 2583647230 PinPullModeStatus_X2_18 "Pin pullup/pulldown mode status";
CM_ SG_ 2583647230 LoadDetectionStatus_X2_18 "Report status of enabled/disabled load detection mode";
CM_ BO_ 2582846974 "This mesage reports current pin mode";
CM_ SG_ 2582846974 PinModeStatus_X1_11 "Pin mode status";
CM_ SG_ 2582846974 PinPullModeStatus_X1_11 "Pin pullup/pulldown mode status";
CM_ SG_ 2582846974 LoadDetectionStatus_X1_11 "Report status of enabled/disabled load detection mode";
CM_ SG_ 2582846974 PinModeStatus_X1_12 "Pin mode status";
CM_ SG_ 2582846974 PinPullModeStatus_X1_12 "Pin pullup/pulldown mode status";
CM_ SG_ 2582846974 LoadDetectionStatus_X1_12 "Report status of enabled/disabled load detection mode";
CM_ SG_ 2582846974 PinModeStatus_X1_13 "Pin mode status";
CM_ SG_ 2582846974 PinPullModeStatus_X1_13 "Pin pullup/pulldown mode status";
CM_ SG_ 2582846974 LoadDetectionStatus_X1_13 "Report status of enabled/disabled load detection mode";
CM_ SG_ 2582846974 PinModeStatus_X1_14 "Pin mode status";
CM_ SG_ 2582846974 PinPullModeStatus_X1_14 "Pin pullup/pulldown mode status";
CM_ SG_ 2582846974 LoadDetectionStatus_X1_14 "Report status of enabled/disabled load detection mode";
CM_ SG_ 2582846974 PinModeStatus_X1_15 "Pin mode status";
CM_ SG_ 2582846974 PinPullModeStatus_X1_15 "Pin pullup/pulldown mode status";
CM_ SG_ 2582846974 LoadDetectionStatus_X1_15 "Report status of enabled/disabled load detection mode";
CM_ SG_ 2582846974 PinModeStatus_X1_16 "Pin mode status";
CM_ SG_ 2582846974 PinPullModeStatus_X1_16 "Pin pullup/pulldown mode status";
CM_ SG_ 2582846974 LoadDetectionStatus_X1_16 "Report status of enabled/disabled load detection mode";
CM_ SG_ 2582846974 PinModeStatus_X1_17 "Pin mode status";
CM_ SG_ 2582846974 PinPullModeStatus_X1_17 "Pin pullup/pulldown mode status";
CM_ SG_ 2582846974 LoadDetectionStatus_X1_17 "Report status of enabled/disabled load detection mode";
CM_ SG_ 2582846974 PinModeStatus_X1_18 "Pin mode status";
CM_ SG_ 2582846974 PinPullModeStatus_X1_18 "Pin pullup/pulldown mode status";
CM_ SG_ 2582846974 LoadDetectionStatus_X1_18 "Report status of enabled/disabled load detection mode";
CM_ SG_ 2582846974 PinModeStatus_X1_24 "Pin mode status";
CM_ SG_ 2582846974 PinPullModeStatus_X1_24 "Pin pullup/pulldown mode status";
CM_ SG_ 2582846974 LoadDetectionStatus_X1_24 "Report status of enabled/disabled load detection mode";
CM_ SG_ 2582846974 PinModeStatus_X1_25 "Pin mode status";
CM_ SG_ 2582846974 PinPullModeStatus_X1_25 "Pin pullup/pulldown mode status";
CM_ SG_ 2582846974 LoadDetectionStatus_X1_25 "Report status of enabled/disabled load detection mode";
CM_ SG_ 2582846974 PinModeStatus_X1_3 "Pin mode status";
CM_ SG_ 2582846974 PinPullModeStatus_X1_3 "Pin pullup/pulldown mode status";
CM_ SG_ 2582846974 LoadDetectionStatus_X1_3 "Report status of enabled/disabled load detection mode";
CM_ SG_ 2582846974 PinModeStatus_X1_4 "Pin mode status";
CM_ SG_ 2582846974 PinPullModeStatus_X1_4 "Pin pullup/pulldown mode status";
CM_ SG_ 2582846974 LoadDetectionStatus_X1_4 "Report status of enabled/disabled load detection mode";
CM_ SG_ 2582846974 PinModeStatus_X2_24 "Pin mode status";
CM_ SG_ 2582846974 PinPullModeStatus_X2_24 "Pin pullup/pulldown mode status";
CM_ SG_ 2582846974 LoadDetectionStatus_X2_24 "Report status of enabled/disabled load detection mode";
CM_ SG_ 2582846974 PinModeStatus_X2_25 "Pin mode status";
CM_ SG_ 2582846974 PinPullModeStatus_X2_25 "Pin pullup/pulldown mode status";
CM_ SG_ 2582846974 LoadDetectionStatus_X2_25 "Report status of enabled/disabled load detection mode";
CM_ SG_ 2582846974 PinModeStatus_X2_27 "Pin mode status";
CM_ SG_ 2582846974 PinPullModeStatus_X2_27 "Pin pullup/pulldown mode status";
CM_ SG_ 2582846974 LoadDetectionStatus_X2_27 "Report status of enabled/disabled load detection mode";
CM_ SG_ 2582846974 PinModeStatus_X2_28 "Pin mode status";
CM_ SG_ 2582846974 PinPullModeStatus_X2_28 "Pin pullup/pulldown mode status";
CM_ SG_ 2582846974 LoadDetectionStatus_X2_28 "Report status of enabled/disabled load detection mode";
CM_ SG_ 2582846974 PinModeStatus_X2_11 "Pin mode status";
CM_ SG_ 2582846974 PinPullModeStatus_X2_11 "Pin pullup/pulldown mode status";
CM_ SG_ 2582846974 LoadDetectionStatus_X2_11 "Report status of enabled/disabled load detection mode";
CM_ SG_ 2582846974 PinModeStatus_X2_12 "Pin mode status";
CM_ SG_ 2582846974 PinPullModeStatus_X2_12 "Pin pullup/pulldown mode status";
CM_ SG_ 2582846974 LoadDetectionStatus_X2_12 "Report status of enabled/disabled load detection mode";
CM_ SG_ 2582846974 PinModeStatus_X2_13 "Pin mode status";
CM_ SG_ 2582846974 PinPullModeStatus_X2_13 "Pin pullup/pulldown mode status";
CM_ SG_ 2582846974 LoadDetectionStatus_X2_13 "Report status of enabled/disabled load detection mode";
CM_ SG_ 2582846974 PinModeStatus_X2_14 "Pin mode status";
CM_ SG_ 2582846974 PinPullModeStatus_X2_14 "Pin pullup/pulldown mode status";
CM_ SG_ 2582846974 LoadDetectionStatus_X2_14 "Report status of enabled/disabled load detection mode";
CM_ SG_ 2582846974 PinModeStatus_X2_15 "Pin mode status";
CM_ SG_ 2582846974 PinPullModeStatus_X2_15 "Pin pullup/pulldown mode status";
CM_ SG_ 2582846974 LoadDetectionStatus_X2_15 "Report status of enabled/disabled load detection mode";
CM_ SG_ 2582846974 PinModeStatus_X2_16 "Pin mode status";
CM_ SG_ 2582846974 PinPullModeStatus_X2_16 "Pin pullup/pulldown mode status";
CM_ SG_ 2582846974 LoadDetectionStatus_X2_16 "Report status of enabled/disabled load detection mode";
CM_ SG_ 2582846974 PinModeStatus_X2_17 "Pin mode status";
CM_ SG_ 2582846974 PinPullModeStatus_X2_17 "Pin pullup/pulldown mode status";
CM_ SG_ 2582846974 LoadDetectionStatus_X2_17 "Report status of enabled/disabled load detection mode";
CM_ SG_ 2582846974 PinModeStatus_X2_18 "Pin mode status";
CM_ SG_ 2582846974 PinPullModeStatus_X2_18 "Pin pullup/pulldown mode status";
CM_ SG_ 2582846974 LoadDetectionStatus_X2_18 "Report status of enabled/disabled load detection mode";
CM_ BO_ 2650761214 "PWM Outputs Frequencies";
CM_ SG_ 2650761214 PwmFrequencyStatus_X1_11 "PWM Frequency on output 01";
CM_ SG_ 2650761214 PwmFrequencyStatus_X1_12 "PWM Frequency on output 02";
CM_ SG_ 2650761214 PwmFrequencyStatus_X1_13 "PWM Frequency on output 03";
CM_ SG_ 2650761214 PwmFrequencyStatus_X1_14 "PWM Frequency on output 04";
CM_ BO_ 2650761470 "PWM Outputs Frequencies";
CM_ SG_ 2650761470 PwmFrequencyStatus_X1_15 "PWM Frequency on output 05";
CM_ SG_ 2650761470 PwmFrequencyStatus_X1_16 "PWM Frequency on output 06";
CM_ SG_ 2650761470 PwmFrequencyStatus_X1_17 "PWM Frequency on output 07";
CM_ SG_ 2650761470 PwmFrequencyStatus_X1_18 "PWM Frequency on output 08";
CM_ BO_ 2650761726 "PWM Outputs Frequencies";
CM_ SG_ 2650761726 PwmFrequencyStatus_X1_24 "PWM Frequency on output 09";
CM_ SG_ 2650761726 PwmFrequencyStatus_X1_25 "PWM Frequency on output 10";
CM_ SG_ 2650761726 PwmFrequencyStatus_X1_3 "PWM Frequency on output 11";
CM_ SG_ 2650761726 PwmFrequencyStatus_X1_4 "PWM Frequency on output 12";
CM_ BO_ 2650761982 "PWM Outputs Frequencies";
CM_ SG_ 2650761982 PwmFrequencyStatus_X2_24 "PWM Frequency on output 13";
CM_ SG_ 2650761982 PwmFrequencyStatus_X2_25 "PWM Frequency on output 14";
CM_ SG_ 2650761982 PwmFrequencyStatus_X2_27 "PWM Frequency on output 15";
CM_ BO_ 2649956094 "PWM Outputs Frequencies";
CM_ SG_ 2649956094 PwmFrequencyStatus_X1_11 "PWM Frequency on output 01";
CM_ SG_ 2649956094 PwmFrequencyStatus_X1_12 "PWM Frequency on output 02";
CM_ SG_ 2649956094 PwmFrequencyStatus_X1_13 "PWM Frequency on output 03";
CM_ SG_ 2649956094 PwmFrequencyStatus_X1_14 "PWM Frequency on output 04";
CM_ SG_ 2649956094 PwmFrequencyStatus_X1_15 "PWM Frequency on output 05";
CM_ SG_ 2649956094 PwmFrequencyStatus_X1_16 "PWM Frequency on output 06";
CM_ SG_ 2649956094 PwmFrequencyStatus_X1_17 "PWM Frequency on output 07";
CM_ SG_ 2649956094 PwmFrequencyStatus_X1_18 "PWM Frequency on output 08";
CM_ SG_ 2649956094 PwmFrequencyStatus_X1_24 "PWM Frequency on output 09";
CM_ SG_ 2649956094 PwmFrequencyStatus_X1_25 "PWM Frequency on output 10";
CM_ SG_ 2649956094 PwmFrequencyStatus_X1_3 "PWM Frequency on output 11";
CM_ SG_ 2649956094 PwmFrequencyStatus_X1_4 "PWM Frequency on output 12";
CM_ SG_ 2649956094 PwmFrequencyStatus_X2_24 "PWM Frequency on output 13";
CM_ SG_ 2649956094 PwmFrequencyStatus_X2_25 "PWM Frequency on output 14";
CM_ SG_ 2649956094 PwmFrequencyStatus_X2_27 "PWM Frequency on output 15";
CM_ BO_ 2582847998 "Current configured output duty value";
CM_ SG_ 2582847998 QEncoderDirection_Q01 "Quadrature encoder direction";
CM_ SG_ 2582847998 QEncoderCounter_Q01 "Quadrature encoder impulse counter";
CM_ BO_ 2583649790 "Measured output temperature 1";
CM_ SG_ 2583649790 TemperatureStatus_NTC1 "Temperature sensor 1";
CM_ SG_ 2583649790 TemperatureStatus_NTC2 "Temperature sensor 2";
CM_ SG_ 2583649790 TemperatureStatus_NTC3 "Temperature sensor 3";
CM_ SG_ 2583649790 TemperatureStatus_NTC4 "Temperature sensor 4";
CM_ SG_ 2583649790 TemperatureStatus_HB30_1 "Temperature sensor 5";
CM_ SG_ 2583649790 TemperatureStatus_HB10_1 "Temperature sensor 6";
CM_ SG_ 2583649790 TemperatureStatus_HB10_2 "Temperature sensor 7";
CM_ SG_ 2583649790 TemperatureStatus_HB10_3 "Temperature sensor 8";
BA_DEF_  "BusType" STRING ;
BA_DEF_  "DBName" STRING ;
BA_DEF_  "DatabaseVersion" STRING ;
BA_DEF_ BO_  "GenMsgCycleTime" INT 0 3600000;
BA_DEF_ BO_  "GenMsgILSupport" ENUM  "No","Yes";
BA_DEF_ BO_  "GenMsgRequestable" INT 0 1;
BA_DEF_ BO_  "GenMsgSendType" ENUM  "cyclic","NotUsed","NotUsed","NotUsed","NotUsed","NotUsed","NotUsed","IfActive","noMsgSendType";
BA_DEF_ SG_  "GenSigEVName" STRING ;
BA_DEF_ SG_  "GenSigILSupport" ENUM  "No","Yes";
BA_DEF_ SG_  "GenSigSendType" ENUM  "Cyclic","OnWrite","OnWriteWithRepetition","OnChange","OnChangeWithRepetition","IfActive","IfActiveWithRepetition","NoSigSendType";
BA_DEF_ SG_  "GenSigStartValue" INT 0 2147483647;
BA_DEF_ BU_  "NmStationAddress" INT 0 255;
BA_DEF_  "ProtocolType" STRING ;
BA_DEF_  "SAE_J1939_21_SpecVersion" STRING ;
BA_DEF_  "SAE_J1939_71_SpecVersion" STRING ;
BA_DEF_  "SAE_J1939_73_SpecVersion" STRING ;
BA_DEF_  "SAE_J1939_75_SpecVersion" STRING ;
BA_DEF_  "SAE_J1939_81_SpecVersion" STRING ;
BA_DEF_  "SAE_J1939_DA_SpecVersion" STRING ;
BA_DEF_ SG_  "SPN" INT 0 524287;
BA_DEF_ BO_  "SendOnChange" ENUM  "No","Yes";
BA_DEF_ SG_  "SigType" ENUM  "Default","Range","RangeSigned","ASCII","Discrete","Control","ReferencePGN","DTC","StringDelimiter","StringLength","StringLengthControl","MessageCounter","MessageChecksum";
BA_DEF_ BO_  "VFrameFormat" ENUM  "StandardCAN","ExtendedCAN","reserved","J1939PG","reserved","reserved","reserved","reserved","reserved","reserved","reserved","reserved","reserved","reserved","StandardCAN_FD","ExtendedCAN_FD";
BA_DEF_DEF_  "BusType" "";
BA_DEF_DEF_  "DBName" "";
BA_DEF_DEF_  "DatabaseVersion" "";
BA_DEF_DEF_  "GenMsgCycleTime" 0;
BA_DEF_DEF_  "GenMsgILSupport" "Yes";
BA_DEF_DEF_  "GenMsgRequestable" 1;
BA_DEF_DEF_  "GenMsgSendType" "noMsgSendType";
BA_DEF_DEF_  "GenSigEVName" "Env@Nodename_@Signame";
BA_DEF_DEF_  "GenSigILSupport" "Yes";
BA_DEF_DEF_  "GenSigSendType" "NoSigSendType";
BA_DEF_DEF_  "GenSigStartValue" 0;
BA_DEF_DEF_  "NmStationAddress" 254;
BA_DEF_DEF_  "ProtocolType" "";
BA_DEF_DEF_  "SAE_J1939_21_SpecVersion" "";
BA_DEF_DEF_  "SAE_J1939_71_SpecVersion" "";
BA_DEF_DEF_  "SAE_J1939_73_SpecVersion" "";
BA_DEF_DEF_  "SAE_J1939_75_SpecVersion" "";
BA_DEF_DEF_  "SAE_J1939_81_SpecVersion" "";
BA_DEF_DEF_  "SAE_J1939_DA_SpecVersion" "";
BA_DEF_DEF_  "SPN" 0;
BA_DEF_DEF_  "SendOnChange" "No";
BA_DEF_DEF_  "SigType" "Default";
BA_DEF_DEF_  "VFrameFormat" "J1939PG";
BA_ "BusType" "CAN";
BA_ "DBName" "IO_V4_A_Generic";
BA_ "DatabaseVersion" "8.5";
BA_ "ProtocolType" "J1939";
BA_ "SAE_J1939_21_SpecVersion" "2006-10";
BA_ "SAE_J1939_71_SpecVersion" "2012-10";
BA_ "SAE_J1939_73_SpecVersion" "2012-10";
BA_ "SAE_J1939_75_SpecVersion" "2012-05";
BA_ "SAE_J1939_81_SpecVersion" "2012-05";
BA_ "SAE_J1939_DA_SpecVersion" "2015-01";
BA_ "GenMsgCycleTime" BO_ 2369322750 100;
BA_ "GenMsgRequestable" BO_ 2369322750 0;
BA_ "GenMsgSendType" BO_ 2369322750 0;
BA_ "SendOnChange" BO_ 2369322750 1;
BA_ "GenMsgCycleTime" BO_ 2369650430 100;
BA_ "GenMsgRequestable" BO_ 2369650430 0;
BA_ "GenMsgSendType" BO_ 2369650430 0;
BA_ "SendOnChange" BO_ 2369650430 1;
BA_ "GenMsgCycleTime" BO_ 2369715966 100;
BA_ "GenMsgRequestable" BO_ 2369715966 0;
BA_ "GenMsgSendType" BO_ 2369715966 0;
BA_ "SendOnChange" BO_ 2369715966 1;
BA_ "GenMsgCycleTime" BO_ 2370043646 100;
BA_ "GenMsgRequestable" BO_ 2370043646 0;
BA_ "GenMsgSendType" BO_ 2370043646 0;
BA_ "GenMsgCycleTime" BO_ 2369388286 100;
BA_ "GenMsgRequestable" BO_ 2369388286 0;
BA_ "GenMsgSendType" BO_ 2369388286 0;
BA_ "SendOnChange" BO_ 2369388286 1;
BA_ "GenMsgCycleTime" BO_ 2369453822 100;
BA_ "GenMsgRequestable" BO_ 2369453822 0;
BA_ "GenMsgSendType" BO_ 2369453822 0;
BA_ "SendOnChange" BO_ 2369453822 1;
BA_ "GenMsgCycleTime" BO_ 2369519358 100;
BA_ "GenMsgRequestable" BO_ 2369519358 0;
BA_ "GenMsgSendType" BO_ 2369519358 0;
BA_ "SendOnChange" BO_ 2369519358 1;
BA_ "GenMsgCycleTime" BO_ 2369912574 10000;
BA_ "GenMsgRequestable" BO_ 2369912574 0;
BA_ "GenMsgSendType" BO_ 2369912574 0;
BA_ "SendOnChange" BO_ 2369912574 1;
BA_ "GenMsgCycleTime" BO_ 2583656702 100;
BA_ "GenMsgRequestable" BO_ 2583656702 0;
BA_ "GenMsgSendType" BO_ 2583656702 0;
BA_ "GenMsgCycleTime" BO_ 2583656446 100;
BA_ "GenMsgRequestable" BO_ 2583656446 0;
BA_ "GenMsgSendType" BO_ 2583656446 0;
BA_ "GenMsgCycleTime" BO_ 2583656190 100;
BA_ "GenMsgRequestable" BO_ 2583656190 0;
BA_ "GenMsgSendType" BO_ 2583656190 0;
BA_ "GenMsgCycleTime" BO_ 2583647742 100;
BA_ "GenMsgRequestable" BO_ 2583647742 0;
BA_ "GenMsgSendType" BO_ 2583647742 0;
BA_ "GenMsgCycleTime" BO_ 2583647998 100;
BA_ "GenMsgRequestable" BO_ 2583647998 0;
BA_ "GenMsgSendType" BO_ 2583647998 0;
BA_ "GenMsgCycleTime" BO_ 2583648254 100;
BA_ "GenMsgRequestable" BO_ 2583648254 0;
BA_ "GenMsgSendType" BO_ 2583648254 0;
BA_ "GenMsgCycleTime" BO_ 2583648510 100;
BA_ "GenMsgRequestable" BO_ 2583648510 0;
BA_ "GenMsgSendType" BO_ 2583648510 0;
BA_ "GenMsgCycleTime" BO_ 2582845950 100;
BA_ "GenMsgRequestable" BO_ 2582845950 0;
BA_ "GenMsgSendType" BO_ 2582845950 0;
BA_ "GenMsgCycleTime" BO_ 2583648766 10000;
BA_ "GenMsgRequestable" BO_ 2583648766 0;
BA_ "GenMsgSendType" BO_ 2583648766 0;
BA_ "GenMsgCycleTime" BO_ 2583649022 10000;
BA_ "GenMsgRequestable" BO_ 2583649022 0;
BA_ "GenMsgSendType" BO_ 2583649022 0;
BA_ "GenMsgCycleTime" BO_ 2582847486 10000;
BA_ "GenMsgRequestable" BO_ 2582847486 0;
BA_ "GenMsgSendType" BO_ 2582847486 0;
BA_ "GenMsgCycleTime" BO_ 2583651326 100;
BA_ "GenMsgRequestable" BO_ 2583651326 0;
BA_ "GenMsgSendType" BO_ 2583651326 0;
BA_ "GenMsgCycleTime" BO_ 2583651582 100;
BA_ "GenMsgRequestable" BO_ 2583651582 0;
BA_ "GenMsgSendType" BO_ 2583651582 0;
BA_ "GenMsgCycleTime" BO_ 2582847742 100;
BA_ "GenMsgRequestable" BO_ 2582847742 0;
BA_ "GenMsgSendType" BO_ 2582847742 0;
BA_ "GenMsgCycleTime" BO_ 2582843646 10000;
BA_ "GenMsgRequestable" BO_ 2582843646 0;
BA_ "GenMsgSendType" BO_ 2582843646 0;
BA_ "GenMsgCycleTime" BO_ 2582843902 10000;
BA_ "GenMsgRequestable" BO_ 2582843902 0;
BA_ "GenMsgSendType" BO_ 2582843902 0;
BA_ "GenMsgCycleTime" BO_ 2582844158 10000;
BA_ "GenMsgRequestable" BO_ 2582844158 0;
BA_ "GenMsgSendType" BO_ 2582844158 0;
BA_ "GenMsgCycleTime" BO_ 2582844414 10000;
BA_ "GenMsgRequestable" BO_ 2582844414 0;
BA_ "GenMsgSendType" BO_ 2582844414 0;
BA_ "GenMsgCycleTime" BO_ 2582844670 10000;
BA_ "GenMsgRequestable" BO_ 2582844670 0;
BA_ "GenMsgSendType" BO_ 2582844670 0;
BA_ "GenMsgCycleTime" BO_ 2582844926 10000;
BA_ "GenMsgRequestable" BO_ 2582844926 0;
BA_ "GenMsgSendType" BO_ 2582844926 0;
BA_ "GenMsgCycleTime" BO_ 2582846206 10000;
BA_ "GenMsgRequestable" BO_ 2582846206 0;
BA_ "GenMsgSendType" BO_ 2582846206 0;
BA_ "GenMsgCycleTime" BO_ 2582839550 10000;
BA_ "GenMsgRequestable" BO_ 2582839550 0;
BA_ "GenMsgSendType" BO_ 2582839550 0;
BA_ "GenMsgCycleTime" BO_ 2582839806 10000;
BA_ "GenMsgRequestable" BO_ 2582839806 0;
BA_ "GenMsgSendType" BO_ 2582839806 0;
BA_ "GenMsgCycleTime" BO_ 2582840062 10000;
BA_ "GenMsgRequestable" BO_ 2582840062 0;
BA_ "GenMsgSendType" BO_ 2582840062 0;
BA_ "GenMsgCycleTime" BO_ 2582840318 10000;
BA_ "GenMsgRequestable" BO_ 2582840318 0;
BA_ "GenMsgSendType" BO_ 2582840318 0;
BA_ "GenMsgCycleTime" BO_ 2582846462 10000;
BA_ "GenMsgRequestable" BO_ 2582846462 0;
BA_ "GenMsgSendType" BO_ 2582846462 0;
BA_ "GenMsgCycleTime" BO_ 2582841598 10000;
BA_ "GenMsgRequestable" BO_ 2582841598 0;
BA_ "GenMsgSendType" BO_ 2582841598 0;
BA_ "GenMsgCycleTime" BO_ 2582841854 10000;
BA_ "GenMsgRequestable" BO_ 2582841854 0;
BA_ "GenMsgSendType" BO_ 2582841854 0;
BA_ "GenMsgCycleTime" BO_ 2582842110 10000;
BA_ "GenMsgRequestable" BO_ 2582842110 0;
BA_ "GenMsgSendType" BO_ 2582842110 0;
BA_ "GenMsgCycleTime" BO_ 2582842366 10000;
BA_ "GenMsgRequestable" BO_ 2582842366 0;
BA_ "GenMsgSendType" BO_ 2582842366 0;
BA_ "GenMsgCycleTime" BO_ 2582842622 10000;
BA_ "GenMsgRequestable" BO_ 2582842622 0;
BA_ "GenMsgSendType" BO_ 2582842622 0;
BA_ "GenMsgCycleTime" BO_ 2582842878 10000;
BA_ "GenMsgRequestable" BO_ 2582842878 0;
BA_ "GenMsgSendType" BO_ 2582842878 0;
BA_ "GenMsgCycleTime" BO_ 2582846718 10000;
BA_ "GenMsgRequestable" BO_ 2582846718 0;
BA_ "GenMsgSendType" BO_ 2582846718 0;
BA_ "GenMsgCycleTime" BO_ 2583650046 100;
BA_ "GenMsgRequestable" BO_ 2583650046 0;
BA_ "GenMsgSendType" BO_ 2583650046 0;
BA_ "GenMsgCycleTime" BO_ 2583650302 100;
BA_ "GenMsgRequestable" BO_ 2583650302 0;
BA_ "GenMsgSendType" BO_ 2583650302 0;
BA_ "GenMsgCycleTime" BO_ 2583650558 100;
BA_ "GenMsgRequestable" BO_ 2583650558 0;
BA_ "GenMsgSendType" BO_ 2583650558 0;
BA_ "GenMsgCycleTime" BO_ 2583650814 100;
BA_ "GenMsgRequestable" BO_ 2583650814 0;
BA_ "GenMsgSendType" BO_ 2583650814 0;
BA_ "GenMsgCycleTime" BO_ 2583651070 100;
BA_ "GenMsgRequestable" BO_ 2583651070 0;
BA_ "GenMsgSendType" BO_ 2583651070 0;
BA_ "GenMsgCycleTime" BO_ 2583654398 100;
BA_ "GenMsgRequestable" BO_ 2583654398 0;
BA_ "GenMsgSendType" BO_ 2583654398 0;
BA_ "GenMsgCycleTime" BO_ 2582845694 100;
BA_ "GenMsgRequestable" BO_ 2582845694 0;
BA_ "GenMsgSendType" BO_ 2582845694 0;
BA_ "GenMsgCycleTime" BO_ 2583646718 10000;
BA_ "GenMsgRequestable" BO_ 2583646718 0;
BA_ "GenMsgSendType" BO_ 2583646718 0;
BA_ "GenMsgCycleTime" BO_ 2583646974 10000;
BA_ "GenMsgRequestable" BO_ 2583646974 0;
BA_ "GenMsgSendType" BO_ 2583646974 0;
BA_ "GenMsgCycleTime" BO_ 2583647230 10000;
BA_ "GenMsgRequestable" BO_ 2583647230 0;
BA_ "GenMsgSendType" BO_ 2583647230 0;
BA_ "GenMsgCycleTime" BO_ 2582846974 10000;
BA_ "GenMsgRequestable" BO_ 2582846974 0;
BA_ "GenMsgSendType" BO_ 2582846974 0;
BA_ "GenMsgCycleTime" BO_ 2650761214 10000;
BA_ "GenMsgSendType" BO_ 2650761214 0;
BA_ "GenMsgCycleTime" BO_ 2650761470 10000;
BA_ "GenMsgSendType" BO_ 2650761470 0;
BA_ "GenMsgCycleTime" BO_ 2650761726 10000;
BA_ "GenMsgSendType" BO_ 2650761726 0;
BA_ "GenMsgCycleTime" BO_ 2650761982 10000;
BA_ "GenMsgSendType" BO_ 2650761982 0;
BA_ "GenMsgCycleTime" BO_ 2649956094 10000;
BA_ "GenMsgSendType" BO_ 2649956094 0;
BA_ "GenMsgCycleTime" BO_ 2582847998 100;
BA_ "GenMsgRequestable" BO_ 2582847998 0;
BA_ "GenMsgSendType" BO_ 2582847998 0;
BA_ "GenMsgCycleTime" BO_ 2583649790 100;
BA_ "GenMsgRequestable" BO_ 2583649790 0;
BA_ "GenMsgSendType" BO_ 2583649790 0;
BA_ "SPN" SG_ 2369322750 BridgeModeCommand_b01 516600;
BA_ "SPN" SG_ 2369322750 BridgeModeCommand_b02 516601;
BA_ "SPN" SG_ 2369322750 BridgeModeCommand_b03 516602;
BA_ "SPN" SG_ 2369322750 BridgeModeCommand_b04 516603;
BA_ "SPN" SG_ 2369322750 BridgeModeCommand_b05 516604;
BA_ "SPN" SG_ 2369322750 BridgeModeCommand_b06 516605;
BA_ "SPN" SG_ 2369322750 BridgeModeCommand_b07 516606;
BA_ "SPN" SG_ 2369322750 BridgeModeCommand_b08 516607;
BA_ "SPN" SG_ 2369650430 DutyCommand_X1_11 516608;
BA_ "SigType" SG_ 2369650430 DutyCommand_X1_11 1;
BA_ "SPN" SG_ 2369650430 DutyCommand_X1_12 516609;
BA_ "SigType" SG_ 2369650430 DutyCommand_X1_12 1;
BA_ "SPN" SG_ 2369650430 DutyCommand_X1_13 516610;
BA_ "SigType" SG_ 2369650430 DutyCommand_X1_13 1;
BA_ "SPN" SG_ 2369650430 DutyCommand_X1_14 516611;
BA_ "SigType" SG_ 2369650430 DutyCommand_X1_14 1;
BA_ "SPN" SG_ 2369650430 DutyCommand_X1_15 516612;
BA_ "SigType" SG_ 2369650430 DutyCommand_X1_15 1;
BA_ "SPN" SG_ 2369650430 DutyCommand_X1_16 516613;
BA_ "SigType" SG_ 2369650430 DutyCommand_X1_16 1;
BA_ "SPN" SG_ 2369650430 DutyCommand_X1_17 516614;
BA_ "SigType" SG_ 2369650430 DutyCommand_X1_17 1;
BA_ "SPN" SG_ 2369650430 DutyCommand_X1_18 516615;
BA_ "SigType" SG_ 2369650430 DutyCommand_X1_18 1;
BA_ "SPN" SG_ 2369715966 DutyCommand_X1_24 516616;
BA_ "SigType" SG_ 2369715966 DutyCommand_X1_24 1;
BA_ "SPN" SG_ 2369715966 DutyCommand_X1_25 516617;
BA_ "SigType" SG_ 2369715966 DutyCommand_X1_25 1;
BA_ "SPN" SG_ 2369715966 DutyCommand_X1_3 516618;
BA_ "SigType" SG_ 2369715966 DutyCommand_X1_3 1;
BA_ "SPN" SG_ 2369715966 DutyCommand_X1_4 516619;
BA_ "SigType" SG_ 2369715966 DutyCommand_X1_4 1;
BA_ "SPN" SG_ 2369715966 DutyCommand_X2_24 516620;
BA_ "SigType" SG_ 2369715966 DutyCommand_X2_24 1;
BA_ "SPN" SG_ 2369715966 DutyCommand_X2_25 516621;
BA_ "SigType" SG_ 2369715966 DutyCommand_X2_25 1;
BA_ "SPN" SG_ 2369715966 DutyCommand_X2_27 516622;
BA_ "SigType" SG_ 2369715966 DutyCommand_X2_27 1;
BA_ "SPN" SG_ 2369715966 DutyCommand_X2_28 516623;
BA_ "SigType" SG_ 2369715966 DutyCommand_X2_28 1;
BA_ "SPN" SG_ 2370043646 DutyCommand_X1_11 516608;
BA_ "SigType" SG_ 2370043646 DutyCommand_X1_11 1;
BA_ "SPN" SG_ 2370043646 DutyCommand_X1_12 516609;
BA_ "SigType" SG_ 2370043646 DutyCommand_X1_12 1;
BA_ "SPN" SG_ 2370043646 DutyCommand_X1_13 516610;
BA_ "SigType" SG_ 2370043646 DutyCommand_X1_13 1;
BA_ "SPN" SG_ 2370043646 DutyCommand_X1_14 516611;
BA_ "SigType" SG_ 2370043646 DutyCommand_X1_14 1;
BA_ "SPN" SG_ 2370043646 DutyCommand_X1_15 516612;
BA_ "SigType" SG_ 2370043646 DutyCommand_X1_15 1;
BA_ "SPN" SG_ 2370043646 DutyCommand_X1_16 516613;
BA_ "SigType" SG_ 2370043646 DutyCommand_X1_16 1;
BA_ "SPN" SG_ 2370043646 DutyCommand_X1_17 516614;
BA_ "SigType" SG_ 2370043646 DutyCommand_X1_17 1;
BA_ "SPN" SG_ 2370043646 DutyCommand_X1_18 516615;
BA_ "SigType" SG_ 2370043646 DutyCommand_X1_18 1;
BA_ "SPN" SG_ 2370043646 DutyCommand_X1_24 516616;
BA_ "SigType" SG_ 2370043646 DutyCommand_X1_24 1;
BA_ "SPN" SG_ 2370043646 DutyCommand_X1_25 516617;
BA_ "SigType" SG_ 2370043646 DutyCommand_X1_25 1;
BA_ "SPN" SG_ 2370043646 DutyCommand_X1_3 516618;
BA_ "SigType" SG_ 2370043646 DutyCommand_X1_3 1;
BA_ "SPN" SG_ 2370043646 DutyCommand_X1_4 516619;
BA_ "SigType" SG_ 2370043646 DutyCommand_X1_4 1;
BA_ "SPN" SG_ 2370043646 DutyCommand_X2_24 516620;
BA_ "SigType" SG_ 2370043646 DutyCommand_X2_24 1;
BA_ "SPN" SG_ 2370043646 DutyCommand_X2_25 516621;
BA_ "SigType" SG_ 2370043646 DutyCommand_X2_25 1;
BA_ "SPN" SG_ 2370043646 DutyCommand_X2_27 516622;
BA_ "SigType" SG_ 2370043646 DutyCommand_X2_27 1;
BA_ "SPN" SG_ 2370043646 DutyCommand_X2_28 516623;
BA_ "SigType" SG_ 2370043646 DutyCommand_X2_28 1;
BA_ "SPN" SG_ 2369388286 PinModeCommand_X1_11 516640;
BA_ "SPN" SG_ 2369388286 PinPullModeCommand_X1_11 516641;
BA_ "SPN" SG_ 2369388286 LoadDetectionCommand_X1_11 516642;
BA_ "SPN" SG_ 2369388286 PinModeCommand_X1_12 516643;
BA_ "SPN" SG_ 2369388286 PinPullModeCommand_X1_12 516644;
BA_ "SPN" SG_ 2369388286 LoadDetectionCommand_X1_12 516645;
BA_ "SPN" SG_ 2369388286 PinModeCommand_X1_13 516646;
BA_ "SPN" SG_ 2369388286 PinPullModeCommand_X1_13 516647;
BA_ "SPN" SG_ 2369388286 LoadDetectionCommand_X1_13 516648;
BA_ "SPN" SG_ 2369388286 PinModeCommand_X1_14 516649;
BA_ "SPN" SG_ 2369388286 PinPullModeCommand_X1_14 516650;
BA_ "SPN" SG_ 2369388286 LoadDetectionCommand_X1_14 516651;
BA_ "SPN" SG_ 2369388286 PinModeCommand_X1_15 516652;
BA_ "SPN" SG_ 2369388286 PinPullModeCommand_X1_15 516653;
BA_ "SPN" SG_ 2369388286 LoadDetectionCommand_X1_15 516654;
BA_ "SPN" SG_ 2369388286 PinModeCommand_X1_16 516655;
BA_ "SPN" SG_ 2369388286 PinPullModeCommand_X1_16 516656;
BA_ "SPN" SG_ 2369388286 LoadDetectionCommand_X1_16 516657;
BA_ "SPN" SG_ 2369388286 PinModeCommand_X1_17 516658;
BA_ "SPN" SG_ 2369388286 PinPullModeCommand_X1_17 516659;
BA_ "SPN" SG_ 2369388286 LoadDetectionCommand_X1_17 516660;
BA_ "SPN" SG_ 2369388286 PinModeCommand_X1_18 516661;
BA_ "SPN" SG_ 2369388286 PinPullModeCommand_X1_18 516662;
BA_ "SPN" SG_ 2369388286 LoadDetectionCommand_X1_18 516663;
BA_ "SPN" SG_ 2369453822 PinModeCommand_X1_24 516664;
BA_ "SPN" SG_ 2369453822 PinPullModeCommand_X1_24 516665;
BA_ "SPN" SG_ 2369453822 LoadDetectionCommand_X1_24 516666;
BA_ "SPN" SG_ 2369453822 PinModeCommand_X1_25 516667;
BA_ "SPN" SG_ 2369453822 PinPullModeCommand_X1_25 516668;
BA_ "SPN" SG_ 2369453822 LoadDetectionCommand_X1_25 516669;
BA_ "SPN" SG_ 2369453822 PinModeCommand_X1_3 516670;
BA_ "SPN" SG_ 2369453822 PinPullModeCommand_X1_3 516671;
BA_ "SPN" SG_ 2369453822 LoadDetectionCommand_X1_3 516672;
BA_ "SPN" SG_ 2369453822 PinModeCommand_X1_4 516673;
BA_ "SPN" SG_ 2369453822 PinPullModeCommand_X1_4 516674;
BA_ "SPN" SG_ 2369453822 LoadDetectionCommand_X1_4 516675;
BA_ "SPN" SG_ 2369453822 PinModeCommand_X2_24 516676;
BA_ "SPN" SG_ 2369453822 PinPullModeCommand_X2_24 516677;
BA_ "SPN" SG_ 2369453822 LoadDetectionCommand_X2_24 516678;
BA_ "SPN" SG_ 2369453822 PinModeCommand_X2_25 516679;
BA_ "SPN" SG_ 2369453822 PinPullModeCommand_X2_25 516680;
BA_ "SPN" SG_ 2369453822 LoadDetectionCommand_X2_25 516681;
BA_ "SPN" SG_ 2369453822 PinModeCommand_X2_27 516682;
BA_ "SPN" SG_ 2369453822 PinPullModeCommand_X2_27 516683;
BA_ "SPN" SG_ 2369453822 LoadDetectionCommand_X2_27 516684;
BA_ "SPN" SG_ 2369453822 PinModeCommand_X2_28 516685;
BA_ "SPN" SG_ 2369453822 PinPullModeCommand_X2_28 516686;
BA_ "SPN" SG_ 2369453822 LoadDetectionCommand_X2_28 516687;
BA_ "SPN" SG_ 2369519358 PinModeCommand_X2_11 516688;
BA_ "SPN" SG_ 2369519358 PinPullModeCommand_X2_11 516689;
BA_ "SPN" SG_ 2369519358 LoadDetectionCommand_X2_11 516690;
BA_ "SPN" SG_ 2369519358 PinModeCommand_X2_12 516691;
BA_ "SPN" SG_ 2369519358 PinPullModeCommand_X2_12 516692;
BA_ "SPN" SG_ 2369519358 LoadDetectionCommand_X2_12 516693;
BA_ "SPN" SG_ 2369519358 PinModeCommand_X2_13 516694;
BA_ "SPN" SG_ 2369519358 PinPullModeCommand_X2_13 516695;
BA_ "SPN" SG_ 2369519358 LoadDetectionCommand_X2_13 516696;
BA_ "SPN" SG_ 2369519358 PinModeCommand_X2_14 516697;
BA_ "SPN" SG_ 2369519358 PinPullModeCommand_X2_14 516698;
BA_ "SPN" SG_ 2369519358 LoadDetectionCommand_X2_14 516699;
BA_ "SPN" SG_ 2369519358 PinModeCommand_X2_15 516700;
BA_ "SPN" SG_ 2369519358 PinPullModeCommand_X2_15 516701;
BA_ "SPN" SG_ 2369519358 LoadDetectionCommand_X2_15 516702;
BA_ "SPN" SG_ 2369519358 PinModeCommand_X2_16 516703;
BA_ "SPN" SG_ 2369519358 PinPullModeCommand_X2_16 516704;
BA_ "SPN" SG_ 2369519358 LoadDetectionCommand_X2_16 516705;
BA_ "SPN" SG_ 2369519358 PinModeCommand_X2_17 516706;
BA_ "SPN" SG_ 2369519358 PinPullModeCommand_X2_17 516707;
BA_ "SPN" SG_ 2369519358 LoadDetectionCommand_X2_17 516708;
BA_ "SPN" SG_ 2369519358 PinModeCommand_X2_18 516709;
BA_ "SPN" SG_ 2369519358 PinPullModeCommand_X2_18 516710;
BA_ "SPN" SG_ 2369519358 LoadDetectionCommand_X2_18 516711;
BA_ "SPN" SG_ 2369912574 PwmFrequencyCommand_X1_11 516736;
BA_ "SPN" SG_ 2369912574 PwmFrequencyCommand_X1_12 516737;
BA_ "SPN" SG_ 2369912574 PwmFrequencyCommand_X1_13 516738;
BA_ "SPN" SG_ 2369912574 PwmFrequencyCommand_X1_14 516739;
BA_ "SPN" SG_ 2369912574 PwmFrequencyCommand_X1_15 516740;
BA_ "SPN" SG_ 2369912574 PwmFrequencyCommand_X1_16 516741;
BA_ "SPN" SG_ 2369912574 PwmFrequencyCommand_X1_17 516742;
BA_ "SPN" SG_ 2369912574 PwmFrequencyCommand_X1_18 516743;
BA_ "SPN" SG_ 2369912574 PwmFrequencyCommand_X1_24 516744;
BA_ "SPN" SG_ 2369912574 PwmFrequencyCommand_X1_25 516745;
BA_ "SPN" SG_ 2369912574 PwmFrequencyCommand_X1_3 516746;
BA_ "SPN" SG_ 2369912574 PwmFrequencyCommand_X1_4 516747;
BA_ "SPN" SG_ 2369912574 PwmFrequencyCommand_X2_24 516748;
BA_ "SPN" SG_ 2369912574 PwmFrequencyCommand_X2_25 516749;
BA_ "SPN" SG_ 2369912574 PwmFrequencyCommand_X2_27 516750;
BA_ "SPN" SG_ 2369912574 PwmFrequencyCommand_X2_28 516751;
BA_ "SPN" SG_ 2583656702 PinDutyStatus_X1_11 516768;
BA_ "SigType" SG_ 2583656702 PinDutyStatus_X1_11 1;
BA_ "SPN" SG_ 2583656702 PinDutyStatus_X1_12 516769;
BA_ "SigType" SG_ 2583656702 PinDutyStatus_X1_12 1;
BA_ "SPN" SG_ 2583656702 PinDutyStatus_X1_13 516770;
BA_ "SigType" SG_ 2583656702 PinDutyStatus_X1_13 1;
BA_ "SPN" SG_ 2583656702 PinDutyStatus_X1_14 516771;
BA_ "SigType" SG_ 2583656702 PinDutyStatus_X1_14 1;
BA_ "SPN" SG_ 2583656446 PinFrequencyStatus_X1_11 516776;
BA_ "SigType" SG_ 2583656446 PinFrequencyStatus_X1_11 1;
BA_ "SPN" SG_ 2583656446 PinFrequencyStatus_X1_12 516777;
BA_ "SigType" SG_ 2583656446 PinFrequencyStatus_X1_12 1;
BA_ "SPN" SG_ 2583656446 PinFrequencyStatus_X1_13 516778;
BA_ "SigType" SG_ 2583656446 PinFrequencyStatus_X1_13 1;
BA_ "SPN" SG_ 2583656446 PinFrequencyStatus_X1_14 516779;
BA_ "SigType" SG_ 2583656446 PinFrequencyStatus_X1_14 1;
BA_ "SPN" SG_ 2583656190 BridgeModeStatus_b01 516784;
BA_ "SPN" SG_ 2583656190 BridgeStatus_b01 516785;
BA_ "SPN" SG_ 2583656190 BridgeModeStatus_b02 516786;
BA_ "SPN" SG_ 2583656190 BridgeStatus_b02 516787;
BA_ "SPN" SG_ 2583656190 BridgeModeStatus_b03 516788;
BA_ "SPN" SG_ 2583656190 BridgeStatus_b03 516789;
BA_ "SPN" SG_ 2583656190 BridgeModeStatus_b04 516790;
BA_ "SPN" SG_ 2583656190 BridgeStatus_b04 516791;
BA_ "SPN" SG_ 2583656190 BridgeModeStatus_b05 516792;
BA_ "SPN" SG_ 2583656190 BridgeStatus_b05 516793;
BA_ "SPN" SG_ 2583656190 BridgeModeStatus_b06 516794;
BA_ "SPN" SG_ 2583656190 BridgeStatus_b06 516795;
BA_ "SPN" SG_ 2583656190 BridgeModeStatus_b07 516796;
BA_ "SPN" SG_ 2583656190 BridgeStatus_b07 516797;
BA_ "SPN" SG_ 2583656190 BridgeModeStatus_b08 516798;
BA_ "SPN" SG_ 2583656190 BridgeStatus_b08 516799;
BA_ "GenSigStartValue" SG_ 2583647742 CurrentStatus_X1_11 32000;
BA_ "SPN" SG_ 2583647742 CurrentStatus_X1_11 516900;
BA_ "SigType" SG_ 2583647742 CurrentStatus_X1_11 1;
BA_ "GenSigStartValue" SG_ 2583647742 CurrentStatus_X1_12 32000;
BA_ "SPN" SG_ 2583647742 CurrentStatus_X1_12 516901;
BA_ "SigType" SG_ 2583647742 CurrentStatus_X1_12 1;
BA_ "GenSigStartValue" SG_ 2583647742 CurrentStatus_X1_13 32000;
BA_ "SPN" SG_ 2583647742 CurrentStatus_X1_13 516902;
BA_ "SigType" SG_ 2583647742 CurrentStatus_X1_13 1;
BA_ "GenSigStartValue" SG_ 2583647742 CurrentStatus_X1_14 32000;
BA_ "SPN" SG_ 2583647742 CurrentStatus_X1_14 516903;
BA_ "SigType" SG_ 2583647742 CurrentStatus_X1_14 1;
BA_ "GenSigStartValue" SG_ 2583647998 CurrentStatus_X1_15 32000;
BA_ "SPN" SG_ 2583647998 CurrentStatus_X1_15 516904;
BA_ "SigType" SG_ 2583647998 CurrentStatus_X1_15 1;
BA_ "GenSigStartValue" SG_ 2583647998 CurrentStatus_X1_16 32000;
BA_ "SPN" SG_ 2583647998 CurrentStatus_X1_16 516905;
BA_ "SigType" SG_ 2583647998 CurrentStatus_X1_16 1;
BA_ "GenSigStartValue" SG_ 2583647998 CurrentStatus_X1_17 32000;
BA_ "SPN" SG_ 2583647998 CurrentStatus_X1_17 516906;
BA_ "SigType" SG_ 2583647998 CurrentStatus_X1_17 1;
BA_ "GenSigStartValue" SG_ 2583647998 CurrentStatus_X1_18 32000;
BA_ "SPN" SG_ 2583647998 CurrentStatus_X1_18 516907;
BA_ "SigType" SG_ 2583647998 CurrentStatus_X1_18 1;
BA_ "GenSigStartValue" SG_ 2583648254 CurrentStatus_X1_24 32000;
BA_ "SPN" SG_ 2583648254 CurrentStatus_X1_24 516908;
BA_ "SigType" SG_ 2583648254 CurrentStatus_X1_24 1;
BA_ "GenSigStartValue" SG_ 2583648254 CurrentStatus_X1_25 32000;
BA_ "SPN" SG_ 2583648254 CurrentStatus_X1_25 516909;
BA_ "SigType" SG_ 2583648254 CurrentStatus_X1_25 1;
BA_ "GenSigStartValue" SG_ 2583648254 CurrentStatus_X1_3 32000;
BA_ "SPN" SG_ 2583648254 CurrentStatus_X1_3 516910;
BA_ "SigType" SG_ 2583648254 CurrentStatus_X1_3 1;
BA_ "GenSigStartValue" SG_ 2583648254 CurrentStatus_X1_4 32000;
BA_ "SPN" SG_ 2583648254 CurrentStatus_X1_4 516911;
BA_ "SigType" SG_ 2583648254 CurrentStatus_X1_4 1;
BA_ "GenSigStartValue" SG_ 2583648510 CurrentStatus_X2_24 32000;
BA_ "SPN" SG_ 2583648510 CurrentStatus_X2_24 516912;
BA_ "SigType" SG_ 2583648510 CurrentStatus_X2_24 1;
BA_ "GenSigStartValue" SG_ 2583648510 CurrentStatus_X2_25 32000;
BA_ "SPN" SG_ 2583648510 CurrentStatus_X2_25 516913;
BA_ "SigType" SG_ 2583648510 CurrentStatus_X2_25 1;
BA_ "GenSigStartValue" SG_ 2583648510 CurrentStatus_X2_27 32000;
BA_ "SPN" SG_ 2583648510 CurrentStatus_X2_27 516914;
BA_ "SigType" SG_ 2583648510 CurrentStatus_X2_27 1;
BA_ "GenSigStartValue" SG_ 2583648510 CurrentStatus_X2_28 32000;
BA_ "SPN" SG_ 2583648510 CurrentStatus_X2_28 516915;
BA_ "SigType" SG_ 2583648510 CurrentStatus_X2_28 1;
BA_ "GenSigStartValue" SG_ 2582845950 CurrentStatus_X1_11 32000;
BA_ "SPN" SG_ 2582845950 CurrentStatus_X1_11 516900;
BA_ "SigType" SG_ 2582845950 CurrentStatus_X1_11 1;
BA_ "GenSigStartValue" SG_ 2582845950 CurrentStatus_X1_12 32000;
BA_ "SPN" SG_ 2582845950 CurrentStatus_X1_12 516901;
BA_ "SigType" SG_ 2582845950 CurrentStatus_X1_12 1;
BA_ "GenSigStartValue" SG_ 2582845950 CurrentStatus_X1_13 32000;
BA_ "SPN" SG_ 2582845950 CurrentStatus_X1_13 516902;
BA_ "SigType" SG_ 2582845950 CurrentStatus_X1_13 1;
BA_ "GenSigStartValue" SG_ 2582845950 CurrentStatus_X1_14 32000;
BA_ "SPN" SG_ 2582845950 CurrentStatus_X1_14 516903;
BA_ "SigType" SG_ 2582845950 CurrentStatus_X1_14 1;
BA_ "GenSigStartValue" SG_ 2582845950 CurrentStatus_X1_15 32000;
BA_ "SPN" SG_ 2582845950 CurrentStatus_X1_15 516904;
BA_ "SigType" SG_ 2582845950 CurrentStatus_X1_15 1;
BA_ "GenSigStartValue" SG_ 2582845950 CurrentStatus_X1_16 32000;
BA_ "SPN" SG_ 2582845950 CurrentStatus_X1_16 516905;
BA_ "SigType" SG_ 2582845950 CurrentStatus_X1_16 1;
BA_ "GenSigStartValue" SG_ 2582845950 CurrentStatus_X1_17 32000;
BA_ "SPN" SG_ 2582845950 CurrentStatus_X1_17 516906;
BA_ "SigType" SG_ 2582845950 CurrentStatus_X1_17 1;
BA_ "GenSigStartValue" SG_ 2582845950 CurrentStatus_X1_18 32000;
BA_ "SPN" SG_ 2582845950 CurrentStatus_X1_18 516907;
BA_ "SigType" SG_ 2582845950 CurrentStatus_X1_18 1;
BA_ "GenSigStartValue" SG_ 2582845950 CurrentStatus_X1_24 32000;
BA_ "SPN" SG_ 2582845950 CurrentStatus_X1_24 516908;
BA_ "SigType" SG_ 2582845950 CurrentStatus_X1_24 1;
BA_ "GenSigStartValue" SG_ 2582845950 CurrentStatus_X1_25 32000;
BA_ "SPN" SG_ 2582845950 CurrentStatus_X1_25 516909;
BA_ "SigType" SG_ 2582845950 CurrentStatus_X1_25 1;
BA_ "GenSigStartValue" SG_ 2582845950 CurrentStatus_X1_3 32000;
BA_ "SPN" SG_ 2582845950 CurrentStatus_X1_3 516910;
BA_ "SigType" SG_ 2582845950 CurrentStatus_X1_3 1;
BA_ "GenSigStartValue" SG_ 2582845950 CurrentStatus_X1_4 32000;
BA_ "SPN" SG_ 2582845950 CurrentStatus_X1_4 516911;
BA_ "SigType" SG_ 2582845950 CurrentStatus_X1_4 1;
BA_ "GenSigStartValue" SG_ 2582845950 CurrentStatus_X2_24 32000;
BA_ "SPN" SG_ 2582845950 CurrentStatus_X2_24 516912;
BA_ "SigType" SG_ 2582845950 CurrentStatus_X2_24 1;
BA_ "GenSigStartValue" SG_ 2582845950 CurrentStatus_X2_25 32000;
BA_ "SPN" SG_ 2582845950 CurrentStatus_X2_25 516913;
BA_ "SigType" SG_ 2582845950 CurrentStatus_X2_25 1;
BA_ "GenSigStartValue" SG_ 2582845950 CurrentStatus_X2_27 32000;
BA_ "SPN" SG_ 2582845950 CurrentStatus_X2_27 516914;
BA_ "SigType" SG_ 2582845950 CurrentStatus_X2_27 1;
BA_ "GenSigStartValue" SG_ 2582845950 CurrentStatus_X2_28 32000;
BA_ "SPN" SG_ 2582845950 CurrentStatus_X2_28 516915;
BA_ "SigType" SG_ 2582845950 CurrentStatus_X2_28 1;
BA_ "SPN" SG_ 2583648766 DiagnosticStatus_X1_11 516932;
BA_ "SigType" SG_ 2583648766 DiagnosticStatus_X1_11 4;
BA_ "SPN" SG_ 2583648766 DiagnosticStatus_X1_12 516933;
BA_ "SPN" SG_ 2583648766 DiagnosticStatus_X1_13 516934;
BA_ "SPN" SG_ 2583648766 DiagnosticStatus_X1_14 516935;
BA_ "SPN" SG_ 2583648766 DiagnosticStatus_X1_15 516936;
BA_ "SPN" SG_ 2583648766 DiagnosticStatus_X1_16 516937;
BA_ "SPN" SG_ 2583648766 DiagnosticStatus_X1_17 516938;
BA_ "SPN" SG_ 2583648766 DiagnosticStatus_X1_18 516939;
BA_ "SPN" SG_ 2583648766 DiagnosticStatus_X1_24 516940;
BA_ "SPN" SG_ 2583648766 DiagnosticStatus_X1_25 516941;
BA_ "SPN" SG_ 2583648766 DiagnosticStatus_X1_3 516942;
BA_ "SPN" SG_ 2583648766 DiagnosticStatus_X1_4 516943;
BA_ "SPN" SG_ 2583648766 DiagnosticStatus_X2_24 516944;
BA_ "SPN" SG_ 2583648766 DiagnosticStatus_X2_25 516945;
BA_ "SPN" SG_ 2583648766 DiagnosticStatus_X2_27 516946;
BA_ "SPN" SG_ 2583648766 DiagnosticStatus_X2_28 516947;
BA_ "SPN" SG_ 2583649022 DiagnosticStatus_X2_11 516948;
BA_ "SPN" SG_ 2583649022 DiagnosticStatus_X2_12 516949;
BA_ "SPN" SG_ 2583649022 DiagnosticStatus_X2_13 516950;
BA_ "SPN" SG_ 2583649022 DiagnosticStatus_X2_14 516951;
BA_ "SPN" SG_ 2583649022 DiagnosticStatus_X2_15 516952;
BA_ "SPN" SG_ 2583649022 DiagnosticStatus_X2_16 516953;
BA_ "SPN" SG_ 2583649022 DiagnosticStatus_X2_17 516954;
BA_ "SPN" SG_ 2583649022 DiagnosticStatus_X2_18 516955;
BA_ "SPN" SG_ 2582847486 DiagnosticStatus_X1_11 516932;
BA_ "SigType" SG_ 2582847486 DiagnosticStatus_X1_11 4;
BA_ "SPN" SG_ 2582847486 DiagnosticStatus_X1_12 516933;
BA_ "SPN" SG_ 2582847486 DiagnosticStatus_X1_13 516934;
BA_ "SPN" SG_ 2582847486 DiagnosticStatus_X1_14 516935;
BA_ "SPN" SG_ 2582847486 DiagnosticStatus_X1_15 516936;
BA_ "SPN" SG_ 2582847486 DiagnosticStatus_X1_16 516937;
BA_ "SPN" SG_ 2582847486 DiagnosticStatus_X1_17 516938;
BA_ "SPN" SG_ 2582847486 DiagnosticStatus_X1_18 516939;
BA_ "SPN" SG_ 2582847486 DiagnosticStatus_X1_24 516940;
BA_ "SPN" SG_ 2582847486 DiagnosticStatus_X1_25 516941;
BA_ "SPN" SG_ 2582847486 DiagnosticStatus_X1_3 516942;
BA_ "SPN" SG_ 2582847486 DiagnosticStatus_X1_4 516943;
BA_ "SPN" SG_ 2582847486 DiagnosticStatus_X2_24 516944;
BA_ "SPN" SG_ 2582847486 DiagnosticStatus_X2_25 516945;
BA_ "SPN" SG_ 2582847486 DiagnosticStatus_X2_27 516946;
BA_ "SPN" SG_ 2582847486 DiagnosticStatus_X2_28 516947;
BA_ "SPN" SG_ 2582847486 DiagnosticStatus_X2_11 516948;
BA_ "SPN" SG_ 2582847486 DiagnosticStatus_X2_12 516949;
BA_ "SPN" SG_ 2582847486 DiagnosticStatus_X2_13 516950;
BA_ "SPN" SG_ 2582847486 DiagnosticStatus_X2_14 516951;
BA_ "SPN" SG_ 2582847486 DiagnosticStatus_X2_15 516952;
BA_ "SPN" SG_ 2582847486 DiagnosticStatus_X2_16 516953;
BA_ "SPN" SG_ 2582847486 DiagnosticStatus_X2_17 516954;
BA_ "SPN" SG_ 2582847486 DiagnosticStatus_X2_18 516955;
BA_ "SPN" SG_ 2583651326 DutyStatus_X1_11 516964;
BA_ "SigType" SG_ 2583651326 DutyStatus_X1_11 1;
BA_ "SPN" SG_ 2583651326 DutyStatus_X1_12 516965;
BA_ "SigType" SG_ 2583651326 DutyStatus_X1_12 1;
BA_ "SPN" SG_ 2583651326 DutyStatus_X1_13 516966;
BA_ "SigType" SG_ 2583651326 DutyStatus_X1_13 1;
BA_ "SPN" SG_ 2583651326 DutyStatus_X1_14 516967;
BA_ "SigType" SG_ 2583651326 DutyStatus_X1_14 1;
BA_ "SPN" SG_ 2583651326 DutyStatus_X1_15 516968;
BA_ "SigType" SG_ 2583651326 DutyStatus_X1_15 1;
BA_ "SPN" SG_ 2583651326 DutyStatus_X1_16 516969;
BA_ "SigType" SG_ 2583651326 DutyStatus_X1_16 1;
BA_ "SPN" SG_ 2583651326 DutyStatus_X1_17 516970;
BA_ "SigType" SG_ 2583651326 DutyStatus_X1_17 1;
BA_ "SPN" SG_ 2583651326 DutyStatus_X1_18 516971;
BA_ "SigType" SG_ 2583651326 DutyStatus_X1_18 1;
BA_ "SPN" SG_ 2583651582 DutyStatus_X1_24 516972;
BA_ "SigType" SG_ 2583651582 DutyStatus_X1_24 1;
BA_ "SPN" SG_ 2583651582 DutyStatus_X1_25 516973;
BA_ "SigType" SG_ 2583651582 DutyStatus_X1_25 1;
BA_ "SPN" SG_ 2583651582 DutyStatus_X1_3 516974;
BA_ "SigType" SG_ 2583651582 DutyStatus_X1_3 1;
BA_ "SPN" SG_ 2583651582 DutyStatus_X1_4 516975;
BA_ "SigType" SG_ 2583651582 DutyStatus_X1_4 1;
BA_ "SPN" SG_ 2583651582 DutyStatus_X2_24 516976;
BA_ "SigType" SG_ 2583651582 DutyStatus_X2_24 1;
BA_ "SPN" SG_ 2583651582 DutyStatus_X2_25 516977;
BA_ "SigType" SG_ 2583651582 DutyStatus_X2_25 1;
BA_ "SPN" SG_ 2583651582 DutyStatus_X2_27 516978;
BA_ "SigType" SG_ 2583651582 DutyStatus_X2_27 1;
BA_ "SPN" SG_ 2583651582 DutyStatus_X2_28 516979;
BA_ "SigType" SG_ 2583651582 DutyStatus_X2_28 1;
BA_ "SPN" SG_ 2582847742 DutyStatus_X1_11 516964;
BA_ "SigType" SG_ 2582847742 DutyStatus_X1_11 1;
BA_ "SPN" SG_ 2582847742 DutyStatus_X1_12 516965;
BA_ "SigType" SG_ 2582847742 DutyStatus_X1_12 1;
BA_ "SPN" SG_ 2582847742 DutyStatus_X1_13 516966;
BA_ "SigType" SG_ 2582847742 DutyStatus_X1_13 1;
BA_ "SPN" SG_ 2582847742 DutyStatus_X1_14 516967;
BA_ "SigType" SG_ 2582847742 DutyStatus_X1_14 1;
BA_ "SPN" SG_ 2582847742 DutyStatus_X1_15 516968;
BA_ "SigType" SG_ 2582847742 DutyStatus_X1_15 1;
BA_ "SPN" SG_ 2582847742 DutyStatus_X1_16 516969;
BA_ "SigType" SG_ 2582847742 DutyStatus_X1_16 1;
BA_ "SPN" SG_ 2582847742 DutyStatus_X1_17 516970;
BA_ "SigType" SG_ 2582847742 DutyStatus_X1_17 1;
BA_ "SPN" SG_ 2582847742 DutyStatus_X1_18 516971;
BA_ "SigType" SG_ 2582847742 DutyStatus_X1_18 1;
BA_ "SPN" SG_ 2582847742 DutyStatus_X1_24 516972;
BA_ "SigType" SG_ 2582847742 DutyStatus_X1_24 1;
BA_ "SPN" SG_ 2582847742 DutyStatus_X1_25 516973;
BA_ "SigType" SG_ 2582847742 DutyStatus_X1_25 1;
BA_ "SPN" SG_ 2582847742 DutyStatus_X1_3 516974;
BA_ "SigType" SG_ 2582847742 DutyStatus_X1_3 1;
BA_ "SPN" SG_ 2582847742 DutyStatus_X1_4 516975;
BA_ "SigType" SG_ 2582847742 DutyStatus_X1_4 1;
BA_ "SPN" SG_ 2582847742 DutyStatus_X2_24 516976;
BA_ "SigType" SG_ 2582847742 DutyStatus_X2_24 1;
BA_ "SPN" SG_ 2582847742 DutyStatus_X2_25 516977;
BA_ "SigType" SG_ 2582847742 DutyStatus_X2_25 1;
BA_ "SPN" SG_ 2582847742 DutyStatus_X2_27 516978;
BA_ "SigType" SG_ 2582847742 DutyStatus_X2_27 1;
BA_ "SPN" SG_ 2582847742 DutyStatus_X2_28 516979;
BA_ "SigType" SG_ 2582847742 DutyStatus_X2_28 1;
BA_ "SPN" SG_ 2582843646 FaultCountStatus_X1_11 516996;
BA_ "SigType" SG_ 2582843646 FaultCountStatus_X1_11 1;
BA_ "SPN" SG_ 2582843646 FaultCountStatus_X1_12 516997;
BA_ "SigType" SG_ 2582843646 FaultCountStatus_X1_12 1;
BA_ "SPN" SG_ 2582843646 FaultCountStatus_X1_13 516998;
BA_ "SigType" SG_ 2582843646 FaultCountStatus_X1_13 1;
BA_ "SPN" SG_ 2582843646 FaultCountStatus_X1_14 516999;
BA_ "SigType" SG_ 2582843646 FaultCountStatus_X1_14 1;
BA_ "SPN" SG_ 2582843902 FaultCountStatus_X1_15 519000;
BA_ "SigType" SG_ 2582843902 FaultCountStatus_X1_15 1;
BA_ "SPN" SG_ 2582843902 FaultCountStatus_X1_16 519001;
BA_ "SigType" SG_ 2582843902 FaultCountStatus_X1_16 1;
BA_ "SPN" SG_ 2582843902 FaultCountStatus_X1_17 519002;
BA_ "SigType" SG_ 2582843902 FaultCountStatus_X1_17 1;
BA_ "SPN" SG_ 2582843902 FaultCountStatus_X1_18 519003;
BA_ "SigType" SG_ 2582843902 FaultCountStatus_X1_18 1;
BA_ "SPN" SG_ 2582844158 FaultCountStatus_X1_24 519004;
BA_ "SigType" SG_ 2582844158 FaultCountStatus_X1_24 1;
BA_ "SPN" SG_ 2582844158 FaultCountStatus_X1_25 519005;
BA_ "SigType" SG_ 2582844158 FaultCountStatus_X1_25 1;
BA_ "SPN" SG_ 2582844158 FaultCountStatus_X1_3 519006;
BA_ "SigType" SG_ 2582844158 FaultCountStatus_X1_3 1;
BA_ "SPN" SG_ 2582844158 FaultCountStatus_X1_4 519007;
BA_ "SigType" SG_ 2582844158 FaultCountStatus_X1_4 1;
BA_ "SPN" SG_ 2582844414 FaultCountStatus_X2_24 519008;
BA_ "SigType" SG_ 2582844414 FaultCountStatus_X2_24 1;
BA_ "SPN" SG_ 2582844414 FaultCountStatus_X2_25 519009;
BA_ "SigType" SG_ 2582844414 FaultCountStatus_X2_25 1;
BA_ "SPN" SG_ 2582844414 FaultCountStatus_X2_27 519010;
BA_ "SigType" SG_ 2582844414 FaultCountStatus_X2_27 1;
BA_ "SPN" SG_ 2582844414 FaultCountStatus_X2_28 519011;
BA_ "SigType" SG_ 2582844414 FaultCountStatus_X2_28 1;
BA_ "SPN" SG_ 2582844670 FaultCountStatus_X2_11 519012;
BA_ "SigType" SG_ 2582844670 FaultCountStatus_X2_11 1;
BA_ "SPN" SG_ 2582844670 FaultCountStatus_X2_12 519013;
BA_ "SigType" SG_ 2582844670 FaultCountStatus_X2_12 1;
BA_ "SPN" SG_ 2582844670 FaultCountStatus_X2_13 519014;
BA_ "SigType" SG_ 2582844670 FaultCountStatus_X2_13 1;
BA_ "SPN" SG_ 2582844670 FaultCountStatus_X2_14 519015;
BA_ "SigType" SG_ 2582844670 FaultCountStatus_X2_14 1;
BA_ "SPN" SG_ 2582844926 FaultCountStatus_X2_15 519016;
BA_ "SigType" SG_ 2582844926 FaultCountStatus_X2_15 1;
BA_ "SPN" SG_ 2582844926 FaultCountStatus_X2_16 519017;
BA_ "SigType" SG_ 2582844926 FaultCountStatus_X2_16 1;
BA_ "SPN" SG_ 2582844926 FaultCountStatus_X2_17 519018;
BA_ "SigType" SG_ 2582844926 FaultCountStatus_X2_17 1;
BA_ "SPN" SG_ 2582844926 FaultCountStatus_X2_18 519019;
BA_ "SigType" SG_ 2582844926 FaultCountStatus_X2_18 1;
BA_ "SPN" SG_ 2582846206 FaultCountStatus_X1_11 516996;
BA_ "SigType" SG_ 2582846206 FaultCountStatus_X1_11 1;
BA_ "SPN" SG_ 2582846206 FaultCountStatus_X1_12 516997;
BA_ "SigType" SG_ 2582846206 FaultCountStatus_X1_12 1;
BA_ "SPN" SG_ 2582846206 FaultCountStatus_X1_13 516998;
BA_ "SigType" SG_ 2582846206 FaultCountStatus_X1_13 1;
BA_ "SPN" SG_ 2582846206 FaultCountStatus_X1_14 516999;
BA_ "SigType" SG_ 2582846206 FaultCountStatus_X1_14 1;
BA_ "SPN" SG_ 2582846206 FaultCountStatus_X1_15 519000;
BA_ "SigType" SG_ 2582846206 FaultCountStatus_X1_15 1;
BA_ "SPN" SG_ 2582846206 FaultCountStatus_X1_16 519001;
BA_ "SigType" SG_ 2582846206 FaultCountStatus_X1_16 1;
BA_ "SPN" SG_ 2582846206 FaultCountStatus_X1_17 519002;
BA_ "SigType" SG_ 2582846206 FaultCountStatus_X1_17 1;
BA_ "SPN" SG_ 2582846206 FaultCountStatus_X1_18 519003;
BA_ "SigType" SG_ 2582846206 FaultCountStatus_X1_18 1;
BA_ "SPN" SG_ 2582846206 FaultCountStatus_X1_24 519004;
BA_ "SigType" SG_ 2582846206 FaultCountStatus_X1_24 1;
BA_ "SPN" SG_ 2582846206 FaultCountStatus_X1_25 519005;
BA_ "SigType" SG_ 2582846206 FaultCountStatus_X1_25 1;
BA_ "SPN" SG_ 2582846206 FaultCountStatus_X1_3 519006;
BA_ "SigType" SG_ 2582846206 FaultCountStatus_X1_3 1;
BA_ "SPN" SG_ 2582846206 FaultCountStatus_X1_4 519007;
BA_ "SigType" SG_ 2582846206 FaultCountStatus_X1_4 1;
BA_ "SPN" SG_ 2582846206 FaultCountStatus_X2_24 519008;
BA_ "SigType" SG_ 2582846206 FaultCountStatus_X2_24 1;
BA_ "SPN" SG_ 2582846206 FaultCountStatus_X2_25 519009;
BA_ "SigType" SG_ 2582846206 FaultCountStatus_X2_25 1;
BA_ "SPN" SG_ 2582846206 FaultCountStatus_X2_27 519010;
BA_ "SigType" SG_ 2582846206 FaultCountStatus_X2_27 1;
BA_ "SPN" SG_ 2582846206 FaultCountStatus_X2_28 519011;
BA_ "SigType" SG_ 2582846206 FaultCountStatus_X2_28 1;
BA_ "SPN" SG_ 2582846206 FaultCountStatus_X2_11 519012;
BA_ "SigType" SG_ 2582846206 FaultCountStatus_X2_11 1;
BA_ "SPN" SG_ 2582846206 FaultCountStatus_X2_12 519013;
BA_ "SigType" SG_ 2582846206 FaultCountStatus_X2_12 1;
BA_ "SPN" SG_ 2582846206 FaultCountStatus_X2_13 519014;
BA_ "SigType" SG_ 2582846206 FaultCountStatus_X2_13 1;
BA_ "SPN" SG_ 2582846206 FaultCountStatus_X2_14 519015;
BA_ "SigType" SG_ 2582846206 FaultCountStatus_X2_14 1;
BA_ "SPN" SG_ 2582846206 FaultCountStatus_X2_15 519016;
BA_ "SigType" SG_ 2582846206 FaultCountStatus_X2_15 1;
BA_ "SPN" SG_ 2582846206 FaultCountStatus_X2_16 519017;
BA_ "SigType" SG_ 2582846206 FaultCountStatus_X2_16 1;
BA_ "SPN" SG_ 2582846206 FaultCountStatus_X2_17 519018;
BA_ "SigType" SG_ 2582846206 FaultCountStatus_X2_17 1;
BA_ "SPN" SG_ 2582846206 FaultCountStatus_X2_18 519019;
BA_ "SigType" SG_ 2582846206 FaultCountStatus_X2_18 1;
BA_ "GenSigStartValue" SG_ 2582839550 FaultCurrentStatus_X1_11 32000;
BA_ "SPN" SG_ 2582839550 FaultCurrentStatus_X1_11 519028;
BA_ "SigType" SG_ 2582839550 FaultCurrentStatus_X1_11 1;
BA_ "GenSigStartValue" SG_ 2582839550 FaultCurrentStatus_X1_12 32000;
BA_ "SPN" SG_ 2582839550 FaultCurrentStatus_X1_12 519029;
BA_ "SigType" SG_ 2582839550 FaultCurrentStatus_X1_12 1;
BA_ "GenSigStartValue" SG_ 2582839550 FaultCurrentStatus_X1_13 32000;
BA_ "SPN" SG_ 2582839550 FaultCurrentStatus_X1_13 519030;
BA_ "SigType" SG_ 2582839550 FaultCurrentStatus_X1_13 1;
BA_ "GenSigStartValue" SG_ 2582839550 FaultCurrentStatus_X1_14 32000;
BA_ "SPN" SG_ 2582839550 FaultCurrentStatus_X1_14 519031;
BA_ "SigType" SG_ 2582839550 FaultCurrentStatus_X1_14 1;
BA_ "GenSigStartValue" SG_ 2582839806 FaultCurrentStatus_X1_15 32000;
BA_ "SPN" SG_ 2582839806 FaultCurrentStatus_X1_15 519032;
BA_ "SigType" SG_ 2582839806 FaultCurrentStatus_X1_15 1;
BA_ "GenSigStartValue" SG_ 2582839806 FaultCurrentStatus_X1_16 32000;
BA_ "SPN" SG_ 2582839806 FaultCurrentStatus_X1_16 519033;
BA_ "SigType" SG_ 2582839806 FaultCurrentStatus_X1_16 1;
BA_ "GenSigStartValue" SG_ 2582839806 FaultCurrentStatus_X1_17 32000;
BA_ "SPN" SG_ 2582839806 FaultCurrentStatus_X1_17 519034;
BA_ "SigType" SG_ 2582839806 FaultCurrentStatus_X1_17 1;
BA_ "GenSigStartValue" SG_ 2582839806 FaultCurrentStatus_X1_18 32000;
BA_ "SPN" SG_ 2582839806 FaultCurrentStatus_X1_18 519035;
BA_ "SigType" SG_ 2582839806 FaultCurrentStatus_X1_18 1;
BA_ "GenSigStartValue" SG_ 2582840062 FaultCurrentStatus_X1_24 32000;
BA_ "SPN" SG_ 2582840062 FaultCurrentStatus_X1_24 519036;
BA_ "SigType" SG_ 2582840062 FaultCurrentStatus_X1_24 1;
BA_ "GenSigStartValue" SG_ 2582840062 FaultCurrentStatus_X1_25 32000;
BA_ "SPN" SG_ 2582840062 FaultCurrentStatus_X1_25 519037;
BA_ "SigType" SG_ 2582840062 FaultCurrentStatus_X1_25 1;
BA_ "GenSigStartValue" SG_ 2582840062 FaultCurrentStatus_X1_3 32000;
BA_ "SPN" SG_ 2582840062 FaultCurrentStatus_X1_3 519038;
BA_ "SigType" SG_ 2582840062 FaultCurrentStatus_X1_3 1;
BA_ "GenSigStartValue" SG_ 2582840062 FaultCurrentStatus_X1_4 32000;
BA_ "SPN" SG_ 2582840062 FaultCurrentStatus_X1_4 519039;
BA_ "SigType" SG_ 2582840062 FaultCurrentStatus_X1_4 1;
BA_ "GenSigStartValue" SG_ 2582840318 FaultCurrentStatus_X2_24 32000;
BA_ "SPN" SG_ 2582840318 FaultCurrentStatus_X2_24 519040;
BA_ "SigType" SG_ 2582840318 FaultCurrentStatus_X2_24 1;
BA_ "GenSigStartValue" SG_ 2582840318 FaultCurrentStatus_X2_25 32000;
BA_ "SPN" SG_ 2582840318 FaultCurrentStatus_X2_25 519041;
BA_ "SigType" SG_ 2582840318 FaultCurrentStatus_X2_25 1;
BA_ "GenSigStartValue" SG_ 2582840318 FaultCurrentStatus_X2_27 32000;
BA_ "SPN" SG_ 2582840318 FaultCurrentStatus_X2_27 519042;
BA_ "SigType" SG_ 2582840318 FaultCurrentStatus_X2_27 1;
BA_ "GenSigStartValue" SG_ 2582840318 FaultCurrentStatus_X2_28 32000;
BA_ "SPN" SG_ 2582840318 FaultCurrentStatus_X2_28 519043;
BA_ "SigType" SG_ 2582840318 FaultCurrentStatus_X2_28 1;
BA_ "GenSigStartValue" SG_ 2582846462 FaultCurrentStatus_X1_11 32000;
BA_ "SPN" SG_ 2582846462 FaultCurrentStatus_X1_11 519028;
BA_ "SigType" SG_ 2582846462 FaultCurrentStatus_X1_11 1;
BA_ "GenSigStartValue" SG_ 2582846462 FaultCurrentStatus_X1_12 32000;
BA_ "SPN" SG_ 2582846462 FaultCurrentStatus_X1_12 519029;
BA_ "SigType" SG_ 2582846462 FaultCurrentStatus_X1_12 1;
BA_ "GenSigStartValue" SG_ 2582846462 FaultCurrentStatus_X1_13 32000;
BA_ "SPN" SG_ 2582846462 FaultCurrentStatus_X1_13 519030;
BA_ "SigType" SG_ 2582846462 FaultCurrentStatus_X1_13 1;
BA_ "GenSigStartValue" SG_ 2582846462 FaultCurrentStatus_X1_14 32000;
BA_ "SPN" SG_ 2582846462 FaultCurrentStatus_X1_14 519031;
BA_ "SigType" SG_ 2582846462 FaultCurrentStatus_X1_14 1;
BA_ "GenSigStartValue" SG_ 2582846462 FaultCurrentStatus_X1_15 32000;
BA_ "SPN" SG_ 2582846462 FaultCurrentStatus_X1_15 519032;
BA_ "SigType" SG_ 2582846462 FaultCurrentStatus_X1_15 1;
BA_ "GenSigStartValue" SG_ 2582846462 FaultCurrentStatus_X1_16 32000;
BA_ "SPN" SG_ 2582846462 FaultCurrentStatus_X1_16 519033;
BA_ "SigType" SG_ 2582846462 FaultCurrentStatus_X1_16 1;
BA_ "GenSigStartValue" SG_ 2582846462 FaultCurrentStatus_X1_17 32000;
BA_ "SPN" SG_ 2582846462 FaultCurrentStatus_X1_17 519034;
BA_ "SigType" SG_ 2582846462 FaultCurrentStatus_X1_17 1;
BA_ "GenSigStartValue" SG_ 2582846462 FaultCurrentStatus_X1_18 32000;
BA_ "SPN" SG_ 2582846462 FaultCurrentStatus_X1_18 519035;
BA_ "SigType" SG_ 2582846462 FaultCurrentStatus_X1_18 1;
BA_ "GenSigStartValue" SG_ 2582846462 FaultCurrentStatus_X1_24 32000;
BA_ "SPN" SG_ 2582846462 FaultCurrentStatus_X1_24 519036;
BA_ "SigType" SG_ 2582846462 FaultCurrentStatus_X1_24 1;
BA_ "GenSigStartValue" SG_ 2582846462 FaultCurrentStatus_X1_25 32000;
BA_ "SPN" SG_ 2582846462 FaultCurrentStatus_X1_25 519037;
BA_ "SigType" SG_ 2582846462 FaultCurrentStatus_X1_25 1;
BA_ "GenSigStartValue" SG_ 2582846462 FaultCurrentStatus_X1_3 32000;
BA_ "SPN" SG_ 2582846462 FaultCurrentStatus_X1_3 519038;
BA_ "SigType" SG_ 2582846462 FaultCurrentStatus_X1_3 1;
BA_ "GenSigStartValue" SG_ 2582846462 FaultCurrentStatus_X1_4 32000;
BA_ "SPN" SG_ 2582846462 FaultCurrentStatus_X1_4 519039;
BA_ "SigType" SG_ 2582846462 FaultCurrentStatus_X1_4 1;
BA_ "GenSigStartValue" SG_ 2582846462 FaultCurrentStatus_X2_24 32000;
BA_ "SPN" SG_ 2582846462 FaultCurrentStatus_X2_24 519040;
BA_ "SigType" SG_ 2582846462 FaultCurrentStatus_X2_24 1;
BA_ "GenSigStartValue" SG_ 2582846462 FaultCurrentStatus_X2_25 32000;
BA_ "SPN" SG_ 2582846462 FaultCurrentStatus_X2_25 519041;
BA_ "SigType" SG_ 2582846462 FaultCurrentStatus_X2_25 1;
BA_ "GenSigStartValue" SG_ 2582846462 FaultCurrentStatus_X2_27 32000;
BA_ "SPN" SG_ 2582846462 FaultCurrentStatus_X2_27 519042;
BA_ "SigType" SG_ 2582846462 FaultCurrentStatus_X2_27 1;
BA_ "GenSigStartValue" SG_ 2582846462 FaultCurrentStatus_X2_28 32000;
BA_ "SPN" SG_ 2582846462 FaultCurrentStatus_X2_28 519043;
BA_ "SigType" SG_ 2582846462 FaultCurrentStatus_X2_28 1;
BA_ "SPN" SG_ 2582841598 FaultVoltageStatus_X1_11 519060;
BA_ "SigType" SG_ 2582841598 FaultVoltageStatus_X1_11 1;
BA_ "SPN" SG_ 2582841598 FaultVoltageStatus_X1_12 519061;
BA_ "SigType" SG_ 2582841598 FaultVoltageStatus_X1_12 1;
BA_ "SPN" SG_ 2582841598 FaultVoltageStatus_X1_13 519062;
BA_ "SigType" SG_ 2582841598 FaultVoltageStatus_X1_13 1;
BA_ "SPN" SG_ 2582841598 FaultVoltageStatus_X1_14 519063;
BA_ "SigType" SG_ 2582841598 FaultVoltageStatus_X1_14 1;
BA_ "SPN" SG_ 2582841854 FaultVoltageStatus_X1_15 519064;
BA_ "SigType" SG_ 2582841854 FaultVoltageStatus_X1_15 1;
BA_ "SPN" SG_ 2582841854 FaultVoltageStatus_X1_16 519065;
BA_ "SigType" SG_ 2582841854 FaultVoltageStatus_X1_16 1;
BA_ "SPN" SG_ 2582841854 FaultVoltageStatus_X1_17 519066;
BA_ "SigType" SG_ 2582841854 FaultVoltageStatus_X1_17 1;
BA_ "SPN" SG_ 2582841854 FaultVoltageStatus_X1_18 519067;
BA_ "SigType" SG_ 2582841854 FaultVoltageStatus_X1_18 1;
BA_ "SPN" SG_ 2582842110 FaultVoltageStatus_X1_24 519068;
BA_ "SigType" SG_ 2582842110 FaultVoltageStatus_X1_24 1;
BA_ "SPN" SG_ 2582842110 FaultVoltageStatus_X1_25 519069;
BA_ "SigType" SG_ 2582842110 FaultVoltageStatus_X1_25 1;
BA_ "SPN" SG_ 2582842110 FaultVoltageStatus_X1_3 519070;
BA_ "SigType" SG_ 2582842110 FaultVoltageStatus_X1_3 1;
BA_ "SPN" SG_ 2582842110 FaultVoltageStatus_X1_4 519071;
BA_ "SigType" SG_ 2582842110 FaultVoltageStatus_X1_4 1;
BA_ "SPN" SG_ 2582842366 FaultVoltageStatus_X2_24 519072;
BA_ "SigType" SG_ 2582842366 FaultVoltageStatus_X2_24 1;
BA_ "SPN" SG_ 2582842366 FaultVoltageStatus_X2_25 519073;
BA_ "SigType" SG_ 2582842366 FaultVoltageStatus_X2_25 1;
BA_ "SPN" SG_ 2582842366 FaultVoltageStatus_X2_27 519074;
BA_ "SigType" SG_ 2582842366 FaultVoltageStatus_X2_27 1;
BA_ "SPN" SG_ 2582842366 FaultVoltageStatus_X2_28 519075;
BA_ "SigType" SG_ 2582842366 FaultVoltageStatus_X2_28 1;
BA_ "SPN" SG_ 2582842622 FaultVoltageStatus_X2_11 519076;
BA_ "SigType" SG_ 2582842622 FaultVoltageStatus_X2_11 1;
BA_ "SPN" SG_ 2582842622 FaultVoltageStatus_X2_12 519077;
BA_ "SigType" SG_ 2582842622 FaultVoltageStatus_X2_12 1;
BA_ "SPN" SG_ 2582842622 FaultVoltageStatus_X2_13 519078;
BA_ "SigType" SG_ 2582842622 FaultVoltageStatus_X2_13 1;
BA_ "SPN" SG_ 2582842622 FaultVoltageStatus_X2_14 519079;
BA_ "SigType" SG_ 2582842622 FaultVoltageStatus_X2_14 1;
BA_ "SPN" SG_ 2582842878 FaultVoltageStatus_X2_15 519080;
BA_ "SigType" SG_ 2582842878 FaultVoltageStatus_X2_15 1;
BA_ "SPN" SG_ 2582842878 FaultVoltageStatus_X2_16 519081;
BA_ "SigType" SG_ 2582842878 FaultVoltageStatus_X2_16 1;
BA_ "SPN" SG_ 2582842878 FaultVoltageStatus_X2_17 519082;
BA_ "SigType" SG_ 2582842878 FaultVoltageStatus_X2_17 1;
BA_ "SPN" SG_ 2582842878 FaultVoltageStatus_X2_18 519083;
BA_ "SigType" SG_ 2582842878 FaultVoltageStatus_X2_18 1;
BA_ "SPN" SG_ 2582846718 FaultVoltageStatus_X1_11 519060;
BA_ "SigType" SG_ 2582846718 FaultVoltageStatus_X1_11 1;
BA_ "SPN" SG_ 2582846718 FaultVoltageStatus_X1_12 519061;
BA_ "SigType" SG_ 2582846718 FaultVoltageStatus_X1_12 1;
BA_ "SPN" SG_ 2582846718 FaultVoltageStatus_X1_13 519062;
BA_ "SigType" SG_ 2582846718 FaultVoltageStatus_X1_13 1;
BA_ "SPN" SG_ 2582846718 FaultVoltageStatus_X1_14 519063;
BA_ "SigType" SG_ 2582846718 FaultVoltageStatus_X1_14 1;
BA_ "SPN" SG_ 2582846718 FaultVoltageStatus_X1_15 519064;
BA_ "SigType" SG_ 2582846718 FaultVoltageStatus_X1_15 1;
BA_ "SPN" SG_ 2582846718 FaultVoltageStatus_X1_16 519065;
BA_ "SigType" SG_ 2582846718 FaultVoltageStatus_X1_16 1;
BA_ "SPN" SG_ 2582846718 FaultVoltageStatus_X1_17 519066;
BA_ "SigType" SG_ 2582846718 FaultVoltageStatus_X1_17 1;
BA_ "SPN" SG_ 2582846718 FaultVoltageStatus_X1_18 519067;
BA_ "SigType" SG_ 2582846718 FaultVoltageStatus_X1_18 1;
BA_ "SPN" SG_ 2582846718 FaultVoltageStatus_X1_24 519068;
BA_ "SigType" SG_ 2582846718 FaultVoltageStatus_X1_24 1;
BA_ "SPN" SG_ 2582846718 FaultVoltageStatus_X1_25 519069;
BA_ "SigType" SG_ 2582846718 FaultVoltageStatus_X1_25 1;
BA_ "SPN" SG_ 2582846718 FaultVoltageStatus_X1_3 519070;
BA_ "SigType" SG_ 2582846718 FaultVoltageStatus_X1_3 1;
BA_ "SPN" SG_ 2582846718 FaultVoltageStatus_X1_4 519071;
BA_ "SigType" SG_ 2582846718 FaultVoltageStatus_X1_4 1;
BA_ "SPN" SG_ 2582846718 FaultVoltageStatus_X2_24 519072;
BA_ "SigType" SG_ 2582846718 FaultVoltageStatus_X2_24 1;
BA_ "SPN" SG_ 2582846718 FaultVoltageStatus_X2_25 519073;
BA_ "SigType" SG_ 2582846718 FaultVoltageStatus_X2_25 1;
BA_ "SPN" SG_ 2582846718 FaultVoltageStatus_X2_27 519074;
BA_ "SigType" SG_ 2582846718 FaultVoltageStatus_X2_27 1;
BA_ "SPN" SG_ 2582846718 FaultVoltageStatus_X2_28 519075;
BA_ "SigType" SG_ 2582846718 FaultVoltageStatus_X2_28 1;
BA_ "SPN" SG_ 2582846718 FaultVoltageStatus_X2_11 519076;
BA_ "SigType" SG_ 2582846718 FaultVoltageStatus_X2_11 1;
BA_ "SPN" SG_ 2582846718 FaultVoltageStatus_X2_12 519077;
BA_ "SigType" SG_ 2582846718 FaultVoltageStatus_X2_12 1;
BA_ "SPN" SG_ 2582846718 FaultVoltageStatus_X2_13 519078;
BA_ "SigType" SG_ 2582846718 FaultVoltageStatus_X2_13 1;
BA_ "SPN" SG_ 2582846718 FaultVoltageStatus_X2_14 519079;
BA_ "SigType" SG_ 2582846718 FaultVoltageStatus_X2_14 1;
BA_ "SPN" SG_ 2582846718 FaultVoltageStatus_X2_15 519080;
BA_ "SigType" SG_ 2582846718 FaultVoltageStatus_X2_15 1;
BA_ "SPN" SG_ 2582846718 FaultVoltageStatus_X2_16 519081;
BA_ "SigType" SG_ 2582846718 FaultVoltageStatus_X2_16 1;
BA_ "SPN" SG_ 2582846718 FaultVoltageStatus_X2_17 519082;
BA_ "SigType" SG_ 2582846718 FaultVoltageStatus_X2_17 1;
BA_ "SPN" SG_ 2582846718 FaultVoltageStatus_X2_18 519083;
BA_ "SigType" SG_ 2582846718 FaultVoltageStatus_X2_18 1;
BA_ "SPN" SG_ 2583650046 VoltageStatus_X1_11 519092;
BA_ "SigType" SG_ 2583650046 VoltageStatus_X1_11 1;
BA_ "SPN" SG_ 2583650046 VoltageStatus_X1_12 519093;
BA_ "SigType" SG_ 2583650046 VoltageStatus_X1_12 1;
BA_ "SPN" SG_ 2583650046 VoltageStatus_X1_13 519094;
BA_ "SigType" SG_ 2583650046 VoltageStatus_X1_13 1;
BA_ "SPN" SG_ 2583650046 VoltageStatus_X1_14 519095;
BA_ "SigType" SG_ 2583650046 VoltageStatus_X1_14 1;
BA_ "SPN" SG_ 2583650302 VoltageStatus_X1_15 519096;
BA_ "SigType" SG_ 2583650302 VoltageStatus_X1_15 1;
BA_ "SPN" SG_ 2583650302 VoltageStatus_X1_16 519097;
BA_ "SigType" SG_ 2583650302 VoltageStatus_X1_16 1;
BA_ "SPN" SG_ 2583650302 VoltageStatus_X1_17 519098;
BA_ "SigType" SG_ 2583650302 VoltageStatus_X1_17 1;
BA_ "SPN" SG_ 2583650302 VoltageStatus_X1_18 519099;
BA_ "SigType" SG_ 2583650302 VoltageStatus_X1_18 1;
BA_ "SPN" SG_ 2583650558 VoltageStatus_X1_24 519100;
BA_ "SigType" SG_ 2583650558 VoltageStatus_X1_24 1;
BA_ "SPN" SG_ 2583650558 VoltageStatus_X1_25 519101;
BA_ "SigType" SG_ 2583650558 VoltageStatus_X1_25 1;
BA_ "SPN" SG_ 2583650558 VoltageStatus_X1_3 519102;
BA_ "SigType" SG_ 2583650558 VoltageStatus_X1_3 1;
BA_ "SPN" SG_ 2583650558 VoltageStatus_X1_4 519103;
BA_ "SigType" SG_ 2583650558 VoltageStatus_X1_4 1;
BA_ "SPN" SG_ 2583650814 VoltageStatus_X2_24 519104;
BA_ "SigType" SG_ 2583650814 VoltageStatus_X2_24 1;
BA_ "SPN" SG_ 2583650814 VoltageStatus_X2_25 519105;
BA_ "SigType" SG_ 2583650814 VoltageStatus_X2_25 1;
BA_ "SPN" SG_ 2583650814 VoltageStatus_X2_27 519106;
BA_ "SigType" SG_ 2583650814 VoltageStatus_X2_27 1;
BA_ "SPN" SG_ 2583650814 VoltageStatus_X2_28 519107;
BA_ "SigType" SG_ 2583650814 VoltageStatus_X2_28 1;
BA_ "SPN" SG_ 2583651070 VoltageStatus_X2_11 519108;
BA_ "SigType" SG_ 2583651070 VoltageStatus_X2_11 1;
BA_ "SPN" SG_ 2583651070 VoltageStatus_X2_12 519109;
BA_ "SigType" SG_ 2583651070 VoltageStatus_X2_12 1;
BA_ "SPN" SG_ 2583651070 VoltageStatus_X2_13 519110;
BA_ "SigType" SG_ 2583651070 VoltageStatus_X2_13 1;
BA_ "SPN" SG_ 2583651070 VoltageStatus_X2_14 519111;
BA_ "SigType" SG_ 2583651070 VoltageStatus_X2_14 1;
BA_ "SPN" SG_ 2583654398 VoltageStatus_X2_15 519112;
BA_ "SigType" SG_ 2583654398 VoltageStatus_X2_15 1;
BA_ "SPN" SG_ 2583654398 VoltageStatus_X2_16 519113;
BA_ "SigType" SG_ 2583654398 VoltageStatus_X2_16 1;
BA_ "SPN" SG_ 2583654398 VoltageStatus_X2_17 519114;
BA_ "SigType" SG_ 2583654398 VoltageStatus_X2_17 1;
BA_ "SPN" SG_ 2583654398 VoltageStatus_X2_18 519115;
BA_ "SigType" SG_ 2583654398 VoltageStatus_X2_18 1;
BA_ "SPN" SG_ 2582845694 VoltageStatus_X1_11 519092;
BA_ "SigType" SG_ 2582845694 VoltageStatus_X1_11 1;
BA_ "SPN" SG_ 2582845694 VoltageStatus_X1_12 519093;
BA_ "SigType" SG_ 2582845694 VoltageStatus_X1_12 1;
BA_ "SPN" SG_ 2582845694 VoltageStatus_X1_13 519094;
BA_ "SigType" SG_ 2582845694 VoltageStatus_X1_13 1;
BA_ "SPN" SG_ 2582845694 VoltageStatus_X1_14 519095;
BA_ "SigType" SG_ 2582845694 VoltageStatus_X1_14 1;
BA_ "SPN" SG_ 2582845694 VoltageStatus_X1_15 519096;
BA_ "SigType" SG_ 2582845694 VoltageStatus_X1_15 1;
BA_ "SPN" SG_ 2582845694 VoltageStatus_X1_16 519097;
BA_ "SigType" SG_ 2582845694 VoltageStatus_X1_16 1;
BA_ "SPN" SG_ 2582845694 VoltageStatus_X1_17 519098;
BA_ "SigType" SG_ 2582845694 VoltageStatus_X1_17 1;
BA_ "SPN" SG_ 2582845694 VoltageStatus_X1_18 519099;
BA_ "SigType" SG_ 2582845694 VoltageStatus_X1_18 1;
BA_ "SPN" SG_ 2582845694 VoltageStatus_X1_24 519100;
BA_ "SigType" SG_ 2582845694 VoltageStatus_X1_24 1;
BA_ "SPN" SG_ 2582845694 VoltageStatus_X1_25 519101;
BA_ "SigType" SG_ 2582845694 VoltageStatus_X1_25 1;
BA_ "SPN" SG_ 2582845694 VoltageStatus_X1_3 519102;
BA_ "SigType" SG_ 2582845694 VoltageStatus_X1_3 1;
BA_ "SPN" SG_ 2582845694 VoltageStatus_X1_4 519103;
BA_ "SigType" SG_ 2582845694 VoltageStatus_X1_4 1;
BA_ "SPN" SG_ 2582845694 VoltageStatus_X2_24 519104;
BA_ "SigType" SG_ 2582845694 VoltageStatus_X2_24 1;
BA_ "SPN" SG_ 2582845694 VoltageStatus_X2_25 519105;
BA_ "SigType" SG_ 2582845694 VoltageStatus_X2_25 1;
BA_ "SPN" SG_ 2582845694 VoltageStatus_X2_27 519106;
BA_ "SigType" SG_ 2582845694 VoltageStatus_X2_27 1;
BA_ "SPN" SG_ 2582845694 VoltageStatus_X2_28 519107;
BA_ "SigType" SG_ 2582845694 VoltageStatus_X2_28 1;
BA_ "SPN" SG_ 2582845694 VoltageStatus_X2_11 519108;
BA_ "SigType" SG_ 2582845694 VoltageStatus_X2_11 1;
BA_ "SPN" SG_ 2582845694 VoltageStatus_X2_12 519109;
BA_ "SigType" SG_ 2582845694 VoltageStatus_X2_12 1;
BA_ "SPN" SG_ 2582845694 VoltageStatus_X2_13 519110;
BA_ "SigType" SG_ 2582845694 VoltageStatus_X2_13 1;
BA_ "SPN" SG_ 2582845694 VoltageStatus_X2_14 519111;
BA_ "SigType" SG_ 2582845694 VoltageStatus_X2_14 1;
BA_ "SPN" SG_ 2582845694 VoltageStatus_X2_15 519112;
BA_ "SigType" SG_ 2582845694 VoltageStatus_X2_15 1;
BA_ "SPN" SG_ 2582845694 VoltageStatus_X2_16 519113;
BA_ "SigType" SG_ 2582845694 VoltageStatus_X2_16 1;
BA_ "SPN" SG_ 2582845694 VoltageStatus_X2_17 519114;
BA_ "SigType" SG_ 2582845694 VoltageStatus_X2_17 1;
BA_ "SPN" SG_ 2582845694 VoltageStatus_X2_18 519115;
BA_ "SigType" SG_ 2582845694 VoltageStatus_X2_18 1;
BA_ "SPN" SG_ 2583646718 PinModeStatus_X1_11 519124;
BA_ "SPN" SG_ 2583646718 PinPullModeStatus_X1_11 519125;
BA_ "SPN" SG_ 2583646718 LoadDetectionStatus_X1_11 519126;
BA_ "SPN" SG_ 2583646718 PinModeStatus_X1_12 519127;
BA_ "SPN" SG_ 2583646718 PinPullModeStatus_X1_12 519128;
BA_ "SPN" SG_ 2583646718 LoadDetectionStatus_X1_12 519129;
BA_ "SPN" SG_ 2583646718 PinModeStatus_X1_13 519130;
BA_ "SPN" SG_ 2583646718 PinPullModeStatus_X1_13 519131;
BA_ "SPN" SG_ 2583646718 LoadDetectionStatus_X1_13 519132;
BA_ "SPN" SG_ 2583646718 PinModeStatus_X1_14 519133;
BA_ "SPN" SG_ 2583646718 PinPullModeStatus_X1_14 519134;
BA_ "SPN" SG_ 2583646718 LoadDetectionStatus_X1_14 519135;
BA_ "SPN" SG_ 2583646718 PinModeStatus_X1_15 519136;
BA_ "SPN" SG_ 2583646718 PinPullModeStatus_X1_15 519137;
BA_ "SPN" SG_ 2583646718 LoadDetectionStatus_X1_15 519138;
BA_ "SPN" SG_ 2583646718 PinModeStatus_X1_16 519139;
BA_ "SPN" SG_ 2583646718 PinPullModeStatus_X1_16 519140;
BA_ "SPN" SG_ 2583646718 LoadDetectionStatus_X1_16 519141;
BA_ "SPN" SG_ 2583646718 PinModeStatus_X1_17 519142;
BA_ "SPN" SG_ 2583646718 PinPullModeStatus_X1_17 519143;
BA_ "SPN" SG_ 2583646718 LoadDetectionStatus_X1_17 519144;
BA_ "SPN" SG_ 2583646718 PinModeStatus_X1_18 519145;
BA_ "SPN" SG_ 2583646718 PinPullModeStatus_X1_18 519146;
BA_ "SPN" SG_ 2583646718 LoadDetectionStatus_X1_18 519147;
BA_ "SPN" SG_ 2583646974 PinModeStatus_X1_24 519148;
BA_ "SPN" SG_ 2583646974 PinPullModeStatus_X1_24 519149;
BA_ "SPN" SG_ 2583646974 LoadDetectionStatus_X1_24 519150;
BA_ "SPN" SG_ 2583646974 PinModeStatus_X1_25 519151;
BA_ "SPN" SG_ 2583646974 PinPullModeStatus_X1_25 519152;
BA_ "SPN" SG_ 2583646974 LoadDetectionStatus_X1_25 519153;
BA_ "SPN" SG_ 2583646974 PinModeStatus_X1_3 519154;
BA_ "SPN" SG_ 2583646974 PinPullModeStatus_X1_3 519155;
BA_ "SPN" SG_ 2583646974 LoadDetectionStatus_X1_3 519156;
BA_ "SPN" SG_ 2583646974 PinModeStatus_X1_4 519157;
BA_ "SPN" SG_ 2583646974 PinPullModeStatus_X1_4 519158;
BA_ "SPN" SG_ 2583646974 LoadDetectionStatus_X1_4 519159;
BA_ "SPN" SG_ 2583646974 PinModeStatus_X2_24 519160;
BA_ "SPN" SG_ 2583646974 PinPullModeStatus_X2_24 519161;
BA_ "SPN" SG_ 2583646974 LoadDetectionStatus_X2_24 519162;
BA_ "SPN" SG_ 2583646974 PinModeStatus_X2_25 519163;
BA_ "SPN" SG_ 2583646974 PinPullModeStatus_X2_25 519164;
BA_ "SPN" SG_ 2583646974 LoadDetectionStatus_X2_25 519165;
BA_ "SPN" SG_ 2583646974 PinModeStatus_X2_27 519166;
BA_ "SPN" SG_ 2583646974 PinPullModeStatus_X2_27 519167;
BA_ "SPN" SG_ 2583646974 LoadDetectionStatus_X2_27 519168;
BA_ "SPN" SG_ 2583646974 PinModeStatus_X2_28 519169;
BA_ "SPN" SG_ 2583646974 PinPullModeStatus_X2_28 519170;
BA_ "SPN" SG_ 2583646974 LoadDetectionStatus_X2_28 519171;
BA_ "SPN" SG_ 2583647230 PinModeStatus_X2_11 519172;
BA_ "SPN" SG_ 2583647230 PinPullModeStatus_X2_11 519173;
BA_ "SPN" SG_ 2583647230 LoadDetectionStatus_X2_11 519174;
BA_ "SPN" SG_ 2583647230 PinModeStatus_X2_12 519175;
BA_ "SPN" SG_ 2583647230 PinPullModeStatus_X2_12 519176;
BA_ "SPN" SG_ 2583647230 LoadDetectionStatus_X2_12 519177;
BA_ "SPN" SG_ 2583647230 PinModeStatus_X2_13 519178;
BA_ "SPN" SG_ 2583647230 PinPullModeStatus_X2_13 519179;
BA_ "SPN" SG_ 2583647230 LoadDetectionStatus_X2_13 519180;
BA_ "SPN" SG_ 2583647230 PinModeStatus_X2_14 519181;
BA_ "SPN" SG_ 2583647230 PinPullModeStatus_X2_14 519182;
BA_ "SPN" SG_ 2583647230 LoadDetectionStatus_X2_14 519183;
BA_ "SPN" SG_ 2583647230 PinModeStatus_X2_15 519184;
BA_ "SPN" SG_ 2583647230 PinPullModeStatus_X2_15 519185;
BA_ "SPN" SG_ 2583647230 LoadDetectionStatus_X2_15 519186;
BA_ "SPN" SG_ 2583647230 PinModeStatus_X2_16 519187;
BA_ "SPN" SG_ 2583647230 PinPullModeStatus_X2_16 519188;
BA_ "SPN" SG_ 2583647230 LoadDetectionStatus_X2_16 519189;
BA_ "SPN" SG_ 2583647230 PinModeStatus_X2_17 519190;
BA_ "SPN" SG_ 2583647230 PinPullModeStatus_X2_17 519191;
BA_ "SPN" SG_ 2583647230 LoadDetectionStatus_X2_17 519192;
BA_ "SPN" SG_ 2583647230 PinModeStatus_X2_18 519193;
BA_ "SPN" SG_ 2583647230 PinPullModeStatus_X2_18 519194;
BA_ "SPN" SG_ 2583647230 LoadDetectionStatus_X2_18 519195;
BA_ "SPN" SG_ 2582846974 PinModeStatus_X1_11 519124;
BA_ "SPN" SG_ 2582846974 PinPullModeStatus_X1_11 519125;
BA_ "SPN" SG_ 2582846974 LoadDetectionStatus_X1_11 519126;
BA_ "SPN" SG_ 2582846974 PinModeStatus_X1_12 519127;
BA_ "SPN" SG_ 2582846974 PinPullModeStatus_X1_12 519128;
BA_ "SPN" SG_ 2582846974 LoadDetectionStatus_X1_12 519129;
BA_ "SPN" SG_ 2582846974 PinModeStatus_X1_13 519130;
BA_ "SPN" SG_ 2582846974 PinPullModeStatus_X1_13 519131;
BA_ "SPN" SG_ 2582846974 LoadDetectionStatus_X1_13 519132;
BA_ "SPN" SG_ 2582846974 PinModeStatus_X1_14 519133;
BA_ "SPN" SG_ 2582846974 PinPullModeStatus_X1_14 519134;
BA_ "SPN" SG_ 2582846974 LoadDetectionStatus_X1_14 519135;
BA_ "SPN" SG_ 2582846974 PinModeStatus_X1_15 519136;
BA_ "SPN" SG_ 2582846974 PinPullModeStatus_X1_15 519137;
BA_ "SPN" SG_ 2582846974 LoadDetectionStatus_X1_15 519138;
BA_ "SPN" SG_ 2582846974 PinModeStatus_X1_16 519139;
BA_ "SPN" SG_ 2582846974 PinPullModeStatus_X1_16 519140;
BA_ "SPN" SG_ 2582846974 LoadDetectionStatus_X1_16 519141;
BA_ "SPN" SG_ 2582846974 PinModeStatus_X1_17 519142;
BA_ "SPN" SG_ 2582846974 PinPullModeStatus_X1_17 519143;
BA_ "SPN" SG_ 2582846974 LoadDetectionStatus_X1_17 519144;
BA_ "SPN" SG_ 2582846974 PinModeStatus_X1_18 519145;
BA_ "SPN" SG_ 2582846974 PinPullModeStatus_X1_18 519146;
BA_ "SPN" SG_ 2582846974 LoadDetectionStatus_X1_18 519147;
BA_ "SPN" SG_ 2582846974 PinModeStatus_X1_24 519148;
BA_ "SPN" SG_ 2582846974 PinPullModeStatus_X1_24 519149;
BA_ "SPN" SG_ 2582846974 LoadDetectionStatus_X1_24 519150;
BA_ "SPN" SG_ 2582846974 PinModeStatus_X1_25 519151;
BA_ "SPN" SG_ 2582846974 PinPullModeStatus_X1_25 519152;
BA_ "SPN" SG_ 2582846974 LoadDetectionStatus_X1_25 519153;
BA_ "SPN" SG_ 2582846974 PinModeStatus_X1_3 519154;
BA_ "SPN" SG_ 2582846974 PinPullModeStatus_X1_3 519155;
BA_ "SPN" SG_ 2582846974 LoadDetectionStatus_X1_3 519156;
BA_ "SPN" SG_ 2582846974 PinModeStatus_X1_4 519157;
BA_ "SPN" SG_ 2582846974 PinPullModeStatus_X1_4 519158;
BA_ "SPN" SG_ 2582846974 LoadDetectionStatus_X1_4 519159;
BA_ "SPN" SG_ 2582846974 PinModeStatus_X2_24 519160;
BA_ "SPN" SG_ 2582846974 PinPullModeStatus_X2_24 519161;
BA_ "SPN" SG_ 2582846974 LoadDetectionStatus_X2_24 519162;
BA_ "SPN" SG_ 2582846974 PinModeStatus_X2_25 519163;
BA_ "SPN" SG_ 2582846974 PinPullModeStatus_X2_25 519164;
BA_ "SPN" SG_ 2582846974 LoadDetectionStatus_X2_25 519165;
BA_ "SPN" SG_ 2582846974 PinModeStatus_X2_27 519166;
BA_ "SPN" SG_ 2582846974 PinPullModeStatus_X2_27 519167;
BA_ "SPN" SG_ 2582846974 LoadDetectionStatus_X2_27 519168;
BA_ "SPN" SG_ 2582846974 PinModeStatus_X2_28 519169;
BA_ "SPN" SG_ 2582846974 PinPullModeStatus_X2_28 519170;
BA_ "SPN" SG_ 2582846974 LoadDetectionStatus_X2_28 519171;
BA_ "SPN" SG_ 2582846974 PinModeStatus_X2_11 519172;
BA_ "SPN" SG_ 2582846974 PinPullModeStatus_X2_11 519173;
BA_ "SPN" SG_ 2582846974 LoadDetectionStatus_X2_11 519174;
BA_ "SPN" SG_ 2582846974 PinModeStatus_X2_12 519175;
BA_ "SPN" SG_ 2582846974 PinPullModeStatus_X2_12 519176;
BA_ "SPN" SG_ 2582846974 LoadDetectionStatus_X2_12 519177;
BA_ "SPN" SG_ 2582846974 PinModeStatus_X2_13 519178;
BA_ "SPN" SG_ 2582846974 PinPullModeStatus_X2_13 519179;
BA_ "SPN" SG_ 2582846974 LoadDetectionStatus_X2_13 519180;
BA_ "SPN" SG_ 2582846974 PinModeStatus_X2_14 519181;
BA_ "SPN" SG_ 2582846974 PinPullModeStatus_X2_14 519182;
BA_ "SPN" SG_ 2582846974 LoadDetectionStatus_X2_14 519183;
BA_ "SPN" SG_ 2582846974 PinModeStatus_X2_15 519184;
BA_ "SPN" SG_ 2582846974 PinPullModeStatus_X2_15 519185;
BA_ "SPN" SG_ 2582846974 LoadDetectionStatus_X2_15 519186;
BA_ "SPN" SG_ 2582846974 PinModeStatus_X2_16 519187;
BA_ "SPN" SG_ 2582846974 PinPullModeStatus_X2_16 519188;
BA_ "SPN" SG_ 2582846974 LoadDetectionStatus_X2_16 519189;
BA_ "SPN" SG_ 2582846974 PinModeStatus_X2_17 519190;
BA_ "SPN" SG_ 2582846974 PinPullModeStatus_X2_17 519191;
BA_ "SPN" SG_ 2582846974 LoadDetectionStatus_X2_17 519192;
BA_ "SPN" SG_ 2582846974 PinModeStatus_X2_18 519193;
BA_ "SPN" SG_ 2582846974 PinPullModeStatus_X2_18 519194;
BA_ "SPN" SG_ 2582846974 LoadDetectionStatus_X2_18 519195;
BA_ "SPN" SG_ 2650761214 PwmFrequencyStatus_X1_11 519220;
BA_ "SigType" SG_ 2650761214 PwmFrequencyStatus_X1_11 1;
BA_ "SPN" SG_ 2650761214 PwmFrequencyStatus_X1_12 519221;
BA_ "SigType" SG_ 2650761214 PwmFrequencyStatus_X1_12 1;
BA_ "SPN" SG_ 2650761214 PwmFrequencyStatus_X1_13 519222;
BA_ "SigType" SG_ 2650761214 PwmFrequencyStatus_X1_13 1;
BA_ "SPN" SG_ 2650761214 PwmFrequencyStatus_X1_14 519223;
BA_ "SigType" SG_ 2650761214 PwmFrequencyStatus_X1_14 1;
BA_ "SPN" SG_ 2650761470 PwmFrequencyStatus_X1_15 519224;
BA_ "SigType" SG_ 2650761470 PwmFrequencyStatus_X1_15 1;
BA_ "SPN" SG_ 2650761470 PwmFrequencyStatus_X1_16 519225;
BA_ "SigType" SG_ 2650761470 PwmFrequencyStatus_X1_16 1;
BA_ "SPN" SG_ 2650761470 PwmFrequencyStatus_X1_17 519226;
BA_ "SigType" SG_ 2650761470 PwmFrequencyStatus_X1_17 1;
BA_ "SPN" SG_ 2650761470 PwmFrequencyStatus_X1_18 519227;
BA_ "SigType" SG_ 2650761470 PwmFrequencyStatus_X1_18 1;
BA_ "SPN" SG_ 2650761726 PwmFrequencyStatus_X1_24 519228;
BA_ "SigType" SG_ 2650761726 PwmFrequencyStatus_X1_24 1;
BA_ "SPN" SG_ 2650761726 PwmFrequencyStatus_X1_25 519229;
BA_ "SigType" SG_ 2650761726 PwmFrequencyStatus_X1_25 1;
BA_ "SPN" SG_ 2650761726 PwmFrequencyStatus_X1_3 519230;
BA_ "SigType" SG_ 2650761726 PwmFrequencyStatus_X1_3 1;
BA_ "SPN" SG_ 2650761726 PwmFrequencyStatus_X1_4 519231;
BA_ "SigType" SG_ 2650761726 PwmFrequencyStatus_X1_4 1;
BA_ "SPN" SG_ 2650761982 PwmFrequencyStatus_X2_24 519232;
BA_ "SigType" SG_ 2650761982 PwmFrequencyStatus_X2_24 1;
BA_ "SPN" SG_ 2650761982 PwmFrequencyStatus_X2_25 519233;
BA_ "SigType" SG_ 2650761982 PwmFrequencyStatus_X2_25 1;
BA_ "SPN" SG_ 2650761982 PwmFrequencyStatus_X2_27 519234;
BA_ "SigType" SG_ 2650761982 PwmFrequencyStatus_X2_27 1;
BA_ "SPN" SG_ 2649956094 PwmFrequencyStatus_X1_11 519220;
BA_ "SigType" SG_ 2649956094 PwmFrequencyStatus_X1_11 1;
BA_ "SPN" SG_ 2649956094 PwmFrequencyStatus_X1_12 519221;
BA_ "SigType" SG_ 2649956094 PwmFrequencyStatus_X1_12 1;
BA_ "SPN" SG_ 2649956094 PwmFrequencyStatus_X1_13 519222;
BA_ "SigType" SG_ 2649956094 PwmFrequencyStatus_X1_13 1;
BA_ "SPN" SG_ 2649956094 PwmFrequencyStatus_X1_14 519223;
BA_ "SigType" SG_ 2649956094 PwmFrequencyStatus_X1_14 1;
BA_ "SPN" SG_ 2649956094 PwmFrequencyStatus_X1_15 519224;
BA_ "SigType" SG_ 2649956094 PwmFrequencyStatus_X1_15 1;
BA_ "SPN" SG_ 2649956094 PwmFrequencyStatus_X1_16 519225;
BA_ "SigType" SG_ 2649956094 PwmFrequencyStatus_X1_16 1;
BA_ "SPN" SG_ 2649956094 PwmFrequencyStatus_X1_17 519226;
BA_ "SigType" SG_ 2649956094 PwmFrequencyStatus_X1_17 1;
BA_ "SPN" SG_ 2649956094 PwmFrequencyStatus_X1_18 519227;
BA_ "SigType" SG_ 2649956094 PwmFrequencyStatus_X1_18 1;
BA_ "SPN" SG_ 2649956094 PwmFrequencyStatus_X1_24 519228;
BA_ "SigType" SG_ 2649956094 PwmFrequencyStatus_X1_24 1;
BA_ "SPN" SG_ 2649956094 PwmFrequencyStatus_X1_25 519229;
BA_ "SigType" SG_ 2649956094 PwmFrequencyStatus_X1_25 1;
BA_ "SPN" SG_ 2649956094 PwmFrequencyStatus_X1_3 519230;
BA_ "SigType" SG_ 2649956094 PwmFrequencyStatus_X1_3 1;
BA_ "SPN" SG_ 2649956094 PwmFrequencyStatus_X1_4 519231;
BA_ "SigType" SG_ 2649956094 PwmFrequencyStatus_X1_4 1;
BA_ "SPN" SG_ 2649956094 PwmFrequencyStatus_X2_24 519232;
BA_ "SigType" SG_ 2649956094 PwmFrequencyStatus_X2_24 1;
BA_ "SPN" SG_ 2649956094 PwmFrequencyStatus_X2_25 519233;
BA_ "SigType" SG_ 2649956094 PwmFrequencyStatus_X2_25 1;
BA_ "SPN" SG_ 2649956094 PwmFrequencyStatus_X2_27 519234;
BA_ "SigType" SG_ 2649956094 PwmFrequencyStatus_X2_27 1;
BA_ "SPN" SG_ 2582847998 QEncoderDirection_Q01 519260;
BA_ "GenSigStartValue" SG_ 2582847998 QEncoderCounter_Q01 8000000;
BA_ "SPN" SG_ 2582847998 QEncoderCounter_Q01 519261;
BA_ "SigType" SG_ 2582847998 QEncoderCounter_Q01 1;
BA_ "GenSigStartValue" SG_ 2583649790 TemperatureStatus_NTC1 40;
BA_ "SPN" SG_ 2583649790 TemperatureStatus_NTC1 519252;
BA_ "SigType" SG_ 2583649790 TemperatureStatus_NTC1 1;
BA_ "GenSigStartValue" SG_ 2583649790 TemperatureStatus_NTC2 40;
BA_ "SPN" SG_ 2583649790 TemperatureStatus_NTC2 519253;
BA_ "SigType" SG_ 2583649790 TemperatureStatus_NTC2 1;
BA_ "GenSigStartValue" SG_ 2583649790 TemperatureStatus_NTC3 40;
BA_ "SPN" SG_ 2583649790 TemperatureStatus_NTC3 519254;
BA_ "SigType" SG_ 2583649790 TemperatureStatus_NTC3 1;
BA_ "GenSigStartValue" SG_ 2583649790 TemperatureStatus_NTC4 40;
BA_ "SPN" SG_ 2583649790 TemperatureStatus_NTC4 519255;
BA_ "SigType" SG_ 2583649790 TemperatureStatus_NTC4 1;
BA_ "GenSigStartValue" SG_ 2583649790 TemperatureStatus_HB30_1 40;
BA_ "SPN" SG_ 2583649790 TemperatureStatus_HB30_1 519256;
BA_ "SigType" SG_ 2583649790 TemperatureStatus_HB30_1 1;
BA_ "GenSigStartValue" SG_ 2583649790 TemperatureStatus_HB10_1 40;
BA_ "SPN" SG_ 2583649790 TemperatureStatus_HB10_1 519257;
BA_ "SigType" SG_ 2583649790 TemperatureStatus_HB10_1 1;
BA_ "GenSigStartValue" SG_ 2583649790 TemperatureStatus_HB10_2 40;
BA_ "SPN" SG_ 2583649790 TemperatureStatus_HB10_2 519258;
BA_ "SigType" SG_ 2583649790 TemperatureStatus_HB10_2 1;
BA_ "GenSigStartValue" SG_ 2583649790 TemperatureStatus_HB10_3 40;
BA_ "SPN" SG_ 2583649790 TemperatureStatus_HB10_3 519259;
BA_ "SigType" SG_ 2583649790 TemperatureStatus_HB10_3 1;
VAL_ 2369322750 BridgeModeCommand_b01 0 "Freewheeling" 1 "Forward" 2 "Reverse" 3 "Brake" 6 "Error" 7 "Not Available" ;
VAL_ 2369322750 BridgeModeCommand_b02 0 "Freewheeling" 1 "Forward" 2 "Reverse" 3 "Brake" 6 "Error" 7 "Not Available" ;
VAL_ 2369322750 BridgeModeCommand_b03 0 "Freewheeling" 1 "Forward" 2 "Reverse" 3 "Brake" 6 "Error" 7 "Not Available" ;
VAL_ 2369322750 BridgeModeCommand_b04 0 "Freewheeling" 1 "Forward" 2 "Reverse" 3 "Brake" 6 "Error" 7 "Not Available" ;
VAL_ 2369322750 BridgeModeCommand_b05 0 "Freewheeling" 1 "Forward" 2 "Reverse" 3 "Brake" 6 "Error" 7 "Not Available" ;
VAL_ 2369322750 BridgeModeCommand_b06 0 "Freewheeling" 1 "Forward" 2 "Reverse" 3 "Brake" 6 "Error" 7 "Not Available" ;
VAL_ 2369322750 BridgeModeCommand_b07 0 "Freewheeling" 1 "Forward" 2 "Reverse" 3 "Brake" 6 "Error" 7 "Not Available" ;
VAL_ 2369322750 BridgeModeCommand_b08 0 "Freewheeling" 1 "Forward" 2 "Reverse" 3 "Brake" 6 "Error" 7 "Not Available" ;
VAL_ 2369388286 PinModeCommand_X1_11 0 "Disabled" 1 "VREF" 2 "HighSide" 3 "LowSide" 4 "InputOnly" 5 "Bridge" 14 "Error" 15 "Not Available" ;
VAL_ 2369388286 PinPullModeCommand_X1_11 0 "None" 1 "PullDown" 2 "PullUp" 3 "Not Available" ;
VAL_ 2369388286 LoadDetectionCommand_X1_11 0 "Off" 1 "On" 2 "Error" 3 "Not Available" ;
VAL_ 2369388286 PinModeCommand_X1_12 0 "Disabled" 1 "VREF" 2 "HighSide" 3 "LowSide" 4 "InputOnly" 5 "Bridge" 14 "Error" 15 "Not Available" ;
VAL_ 2369388286 PinPullModeCommand_X1_12 0 "None" 1 "PullDown" 2 "PullUp" 3 "Not Available" ;
VAL_ 2369388286 LoadDetectionCommand_X1_12 0 "Off" 1 "On" 2 "Error" 3 "Not Available" ;
VAL_ 2369388286 PinModeCommand_X1_13 0 "Disabled" 1 "VREF" 2 "HighSide" 3 "LowSide" 4 "InputOnly" 5 "Bridge" 14 "Error" 15 "Not Available" ;
VAL_ 2369388286 PinPullModeCommand_X1_13 0 "None" 1 "PullDown" 2 "PullUp" 3 "Not Available" ;
VAL_ 2369388286 LoadDetectionCommand_X1_13 0 "Off" 1 "On" 2 "Error" 3 "Not Available" ;
VAL_ 2369388286 PinModeCommand_X1_14 0 "Disabled" 1 "VREF" 2 "HighSide" 3 "LowSide" 4 "InputOnly" 5 "Bridge" 14 "Error" 15 "Not Available" ;
VAL_ 2369388286 PinPullModeCommand_X1_14 0 "None" 1 "PullDown" 2 "PullUp" 3 "Not Available" ;
VAL_ 2369388286 LoadDetectionCommand_X1_14 0 "Off" 1 "On" 2 "Error" 3 "Not Available" ;
VAL_ 2369388286 PinModeCommand_X1_15 0 "Disabled" 1 "VREF" 2 "HighSide" 3 "LowSide" 4 "InputOnly" 5 "Bridge" 14 "Error" 15 "Not Available" ;
VAL_ 2369388286 PinPullModeCommand_X1_15 0 "None" 1 "PullDown" 2 "PullUp" 3 "Not Available" ;
VAL_ 2369388286 LoadDetectionCommand_X1_15 0 "Off" 1 "On" 2 "Error" 3 "Not Available" ;
VAL_ 2369388286 PinModeCommand_X1_16 0 "Disabled" 1 "VREF" 2 "HighSide" 3 "LowSide" 4 "InputOnly" 5 "Bridge" 14 "Error" 15 "Not Available" ;
VAL_ 2369388286 PinPullModeCommand_X1_16 0 "None" 1 "PullDown" 2 "PullUp" 3 "Not Available" ;
VAL_ 2369388286 LoadDetectionCommand_X1_16 0 "Off" 1 "On" 2 "Error" 3 "Not Available" ;
VAL_ 2369388286 PinModeCommand_X1_17 0 "Disabled" 1 "VREF" 2 "HighSide" 3 "LowSide" 4 "InputOnly" 5 "Bridge" 14 "Error" 15 "Not Available" ;
VAL_ 2369388286 PinPullModeCommand_X1_17 0 "None" 1 "PullDown" 2 "PullUp" 3 "Not Available" ;
VAL_ 2369388286 LoadDetectionCommand_X1_17 0 "Off" 1 "On" 2 "Error" 3 "Not Available" ;
VAL_ 2369388286 PinModeCommand_X1_18 0 "Disabled" 1 "VREF" 2 "HighSide" 3 "LowSide" 4 "InputOnly" 5 "Bridge" 14 "Error" 15 "Not Available" ;
VAL_ 2369388286 PinPullModeCommand_X1_18 0 "None" 1 "PullDown" 2 "PullUp" 3 "Not Available" ;
VAL_ 2369388286 LoadDetectionCommand_X1_18 0 "Off" 1 "On" 2 "Error" 3 "Not Available" ;
VAL_ 2369453822 PinModeCommand_X1_24 0 "Disabled" 1 "VREF" 2 "HighSide" 3 "LowSide" 4 "InputOnly" 5 "Bridge" 14 "Error" 15 "Not Available" ;
VAL_ 2369453822 PinPullModeCommand_X1_24 0 "None" 1 "PullDown" 2 "PullUp" 3 "Not Available" ;
VAL_ 2369453822 LoadDetectionCommand_X1_24 0 "Off" 1 "On" 2 "Error" 3 "Not Available" ;
VAL_ 2369453822 PinModeCommand_X1_25 0 "Disabled" 1 "VREF" 2 "HighSide" 3 "LowSide" 4 "InputOnly" 5 "Bridge" 14 "Error" 15 "Not Available" ;
VAL_ 2369453822 PinPullModeCommand_X1_25 0 "None" 1 "PullDown" 2 "PullUp" 3 "Not Available" ;
VAL_ 2369453822 LoadDetectionCommand_X1_25 0 "Off" 1 "On" 2 "Error" 3 "Not Available" ;
VAL_ 2369453822 PinModeCommand_X1_3 0 "Disabled" 1 "VREF" 2 "HighSide" 3 "LowSide" 4 "InputOnly" 5 "Bridge" 14 "Error" 15 "Not Available" ;
VAL_ 2369453822 PinPullModeCommand_X1_3 0 "None" 1 "PullDown" 2 "PullUp" 3 "Not Available" ;
VAL_ 2369453822 LoadDetectionCommand_X1_3 0 "Off" 1 "On" 2 "Error" 3 "Not Available" ;
VAL_ 2369453822 PinModeCommand_X1_4 0 "Disabled" 1 "VREF" 2 "HighSide" 3 "LowSide" 4 "InputOnly" 5 "Bridge" 14 "Error" 15 "Not Available" ;
VAL_ 2369453822 PinPullModeCommand_X1_4 0 "None" 1 "PullDown" 2 "PullUp" 3 "Not Available" ;
VAL_ 2369453822 LoadDetectionCommand_X1_4 0 "Off" 1 "On" 2 "Error" 3 "Not Available" ;
VAL_ 2369453822 PinModeCommand_X2_24 0 "Disabled" 1 "VREF" 2 "HighSide" 3 "LowSide" 4 "InputOnly" 5 "Bridge" 14 "Error" 15 "Not Available" ;
VAL_ 2369453822 PinPullModeCommand_X2_24 0 "None" 1 "PullDown" 2 "PullUp" 3 "Not Available" ;
VAL_ 2369453822 LoadDetectionCommand_X2_24 0 "Off" 1 "On" 2 "Error" 3 "Not Available" ;
VAL_ 2369453822 PinModeCommand_X2_25 0 "Disabled" 1 "VREF" 2 "HighSide" 3 "LowSide" 4 "InputOnly" 5 "Bridge" 14 "Error" 15 "Not Available" ;
VAL_ 2369453822 PinPullModeCommand_X2_25 0 "None" 1 "PullDown" 2 "PullUp" 3 "Not Available" ;
VAL_ 2369453822 LoadDetectionCommand_X2_25 0 "Off" 1 "On" 2 "Error" 3 "Not Available" ;
VAL_ 2369453822 PinModeCommand_X2_27 0 "Disabled" 1 "VREF" 2 "HighSide" 3 "LowSide" 4 "InputOnly" 5 "Bridge" 14 "Error" 15 "Not Available" ;
VAL_ 2369453822 PinPullModeCommand_X2_27 0 "None" 1 "PullDown" 2 "PullUp" 3 "Not Available" ;
VAL_ 2369453822 LoadDetectionCommand_X2_27 0 "Off" 1 "On" 2 "Error" 3 "Not Available" ;
VAL_ 2369453822 PinModeCommand_X2_28 0 "Disabled" 1 "VREF" 2 "HighSide" 3 "LowSide" 4 "InputOnly" 5 "Bridge" 14 "Error" 15 "Not Available" ;
VAL_ 2369453822 PinPullModeCommand_X2_28 0 "None" 1 "PullDown" 2 "PullUp" 3 "Not Available" ;
VAL_ 2369453822 LoadDetectionCommand_X2_28 0 "Off" 1 "On" 2 "Error" 3 "Not Available" ;
VAL_ 2369519358 PinModeCommand_X2_11 0 "Disabled" 1 "VREF" 2 "HighSide" 3 "LowSide" 4 "InputOnly" 5 "Bridge" 14 "Error" 15 "Not Available" ;
VAL_ 2369519358 PinPullModeCommand_X2_11 0 "None" 1 "PullDown" 2 "PullUp" 3 "Not Available" ;
VAL_ 2369519358 LoadDetectionCommand_X2_11 0 "Off" 1 "On" 2 "Error" 3 "Not Available" ;
VAL_ 2369519358 PinModeCommand_X2_12 0 "Disabled" 1 "VREF" 2 "HighSide" 3 "LowSide" 4 "InputOnly" 5 "Bridge" 14 "Error" 15 "Not Available" ;
VAL_ 2369519358 PinPullModeCommand_X2_12 0 "None" 1 "PullDown" 2 "PullUp" 3 "Not Available" ;
VAL_ 2369519358 LoadDetectionCommand_X2_12 0 "Off" 1 "On" 2 "Error" 3 "Not Available" ;
VAL_ 2369519358 PinModeCommand_X2_13 0 "Disabled" 1 "VREF" 2 "HighSide" 3 "LowSide" 4 "InputOnly" 5 "Bridge" 14 "Error" 15 "Not Available" ;
VAL_ 2369519358 PinPullModeCommand_X2_13 0 "None" 1 "PullDown" 2 "PullUp" 3 "Not Available" ;
VAL_ 2369519358 LoadDetectionCommand_X2_13 0 "Off" 1 "On" 2 "Error" 3 "Not Available" ;
VAL_ 2369519358 PinModeCommand_X2_14 0 "Disabled" 1 "VREF" 2 "HighSide" 3 "LowSide" 4 "InputOnly" 5 "Bridge" 14 "Error" 15 "Not Available" ;
VAL_ 2369519358 PinPullModeCommand_X2_14 0 "None" 1 "PullDown" 2 "PullUp" 3 "Not Available" ;
VAL_ 2369519358 LoadDetectionCommand_X2_14 0 "Off" 1 "On" 2 "Error" 3 "Not Available" ;
VAL_ 2369519358 PinModeCommand_X2_15 0 "Disabled" 1 "VREF" 2 "HighSide" 3 "LowSide" 4 "InputOnly" 5 "Bridge" 14 "Error" 15 "Not Available" ;
VAL_ 2369519358 PinPullModeCommand_X2_15 0 "None" 1 "PullDown" 2 "PullUp" 3 "Not Available" ;
VAL_ 2369519358 LoadDetectionCommand_X2_15 0 "Off" 1 "On" 2 "Error" 3 "Not Available" ;
VAL_ 2369519358 PinModeCommand_X2_16 0 "Disabled" 1 "VREF" 2 "HighSide" 3 "LowSide" 4 "InputOnly" 5 "Bridge" 14 "Error" 15 "Not Available" ;
VAL_ 2369519358 PinPullModeCommand_X2_16 0 "None" 1 "PullDown" 2 "PullUp" 3 "Not Available" ;
VAL_ 2369519358 LoadDetectionCommand_X2_16 0 "Off" 1 "On" 2 "Error" 3 "Not Available" ;
VAL_ 2369519358 PinModeCommand_X2_17 0 "Disabled" 1 "VREF" 2 "HighSide" 3 "LowSide" 4 "InputOnly" 5 "Bridge" 14 "Error" 15 "Not Available" ;
VAL_ 2369519358 PinPullModeCommand_X2_17 0 "None" 1 "PullDown" 2 "PullUp" 3 "Not Available" ;
VAL_ 2369519358 LoadDetectionCommand_X2_17 0 "Off" 1 "On" 2 "Error" 3 "Not Available" ;
VAL_ 2369519358 PinModeCommand_X2_18 0 "Disabled" 1 "VREF" 2 "HighSide" 3 "LowSide" 4 "InputOnly" 5 "Bridge" 14 "Error" 15 "Not Available" ;
VAL_ 2369519358 PinPullModeCommand_X2_18 0 "None" 1 "PullDown" 2 "PullUp" 3 "Not Available" ;
VAL_ 2369519358 LoadDetectionCommand_X2_18 0 "Off" 1 "On" 2 "Error" 3 "Not Available" ;
VAL_ 2369912574 PwmFrequencyCommand_X1_11 0 "1 Hz" 1 "2 Hz" 2 "5 Hz" 3 "10 Hz" 4 "20 Hz" 5 "50 Hz" 6 "100 Hz" 7 "200 Hz" 8 "500 Hz" 9 "1 KHz" 10 "2 KHz" 11 "5 KHz" 12 "Custom 1" 13 "Custom 2" 14 "Custom 3" 15 "Not Available" ;
VAL_ 2369912574 PwmFrequencyCommand_X1_12 0 "1 Hz" 1 "2 Hz" 2 "5 Hz" 3 "10 Hz" 4 "20 Hz" 5 "50 Hz" 6 "100 Hz" 7 "200 Hz" 8 "500 Hz" 9 "1 KHz" 10 "2 KHz" 11 "5 KHz" 12 "Custom 1" 13 "Custom 2" 14 "Custom 3" 15 "Not Available" ;
VAL_ 2369912574 PwmFrequencyCommand_X1_13 0 "1 Hz" 1 "2 Hz" 2 "5 Hz" 3 "10 Hz" 4 "20 Hz" 5 "50 Hz" 6 "100 Hz" 7 "200 Hz" 8 "500 Hz" 9 "1 KHz" 10 "2 KHz" 11 "5 KHz" 12 "Custom 1" 13 "Custom 2" 14 "Custom 3" 15 "Not Available" ;
VAL_ 2369912574 PwmFrequencyCommand_X1_14 0 "1 Hz" 1 "2 Hz" 2 "5 Hz" 3 "10 Hz" 4 "20 Hz" 5 "50 Hz" 6 "100 Hz" 7 "200 Hz" 8 "500 Hz" 9 "1 KHz" 10 "2 KHz" 11 "5 KHz" 12 "Custom 1" 13 "Custom 2" 14 "Custom 3" 15 "Not Available" ;
VAL_ 2369912574 PwmFrequencyCommand_X1_15 0 "1 Hz" 1 "2 Hz" 2 "5 Hz" 3 "10 Hz" 4 "20 Hz" 5 "50 Hz" 6 "100 Hz" 7 "200 Hz" 8 "500 Hz" 9 "1 KHz" 10 "2 KHz" 11 "5 KHz" 12 "Custom 1" 13 "Custom 2" 14 "Custom 3" 15 "Not Available" ;
VAL_ 2369912574 PwmFrequencyCommand_X1_16 0 "1 Hz" 1 "2 Hz" 2 "5 Hz" 3 "10 Hz" 4 "20 Hz" 5 "50 Hz" 6 "100 Hz" 7 "200 Hz" 8 "500 Hz" 9 "1 KHz" 10 "2 KHz" 11 "5 KHz" 12 "Custom 1" 13 "Custom 2" 14 "Custom 3" 15 "Not Available" ;
VAL_ 2369912574 PwmFrequencyCommand_X1_17 0 "1 Hz" 1 "2 Hz" 2 "5 Hz" 3 "10 Hz" 4 "20 Hz" 5 "50 Hz" 6 "100 Hz" 7 "200 Hz" 8 "500 Hz" 9 "1 KHz" 10 "2 KHz" 11 "5 KHz" 12 "Custom 1" 13 "Custom 2" 14 "Custom 3" 15 "Not Available" ;
VAL_ 2369912574 PwmFrequencyCommand_X1_18 0 "1 Hz" 1 "2 Hz" 2 "5 Hz" 3 "10 Hz" 4 "20 Hz" 5 "50 Hz" 6 "100 Hz" 7 "200 Hz" 8 "500 Hz" 9 "1 KHz" 10 "2 KHz" 11 "5 KHz" 12 "Custom 1" 13 "Custom 2" 14 "Custom 3" 15 "Not Available" ;
VAL_ 2369912574 PwmFrequencyCommand_X1_24 0 "1 Hz" 1 "2 Hz" 2 "5 Hz" 3 "10 Hz" 4 "20 Hz" 5 "50 Hz" 6 "100 Hz" 7 "200 Hz" 8 "500 Hz" 9 "1 KHz" 10 "2 KHz" 11 "5 KHz" 12 "Custom 1" 13 "Custom 2" 14 "Custom 3" 15 "Not Available" ;
VAL_ 2369912574 PwmFrequencyCommand_X1_25 0 "1 Hz" 1 "2 Hz" 2 "5 Hz" 3 "10 Hz" 4 "20 Hz" 5 "50 Hz" 6 "100 Hz" 7 "200 Hz" 8 "500 Hz" 9 "1 KHz" 10 "2 KHz" 11 "5 KHz" 12 "Custom 1" 13 "Custom 2" 14 "Custom 3" 15 "Not Available" ;
VAL_ 2369912574 PwmFrequencyCommand_X1_3 0 "1 Hz" 1 "2 Hz" 2 "5 Hz" 3 "10 Hz" 4 "20 Hz" 5 "50 Hz" 6 "100 Hz" 7 "200 Hz" 8 "500 Hz" 9 "1 KHz" 10 "2 KHz" 11 "5 KHz" 12 "Custom 1" 13 "Custom 2" 14 "Custom 3" 15 "Not Available" ;
VAL_ 2369912574 PwmFrequencyCommand_X1_4 0 "1 Hz" 1 "2 Hz" 2 "5 Hz" 3 "10 Hz" 4 "20 Hz" 5 "50 Hz" 6 "100 Hz" 7 "200 Hz" 8 "500 Hz" 9 "1 KHz" 10 "2 KHz" 11 "5 KHz" 12 "Custom 1" 13 "Custom 2" 14 "Custom 3" 15 "Not Available" ;
VAL_ 2369912574 PwmFrequencyCommand_X2_24 0 "1 Hz" 1 "2 Hz" 2 "5 Hz" 3 "10 Hz" 4 "20 Hz" 5 "50 Hz" 6 "100 Hz" 7 "200 Hz" 8 "500 Hz" 9 "1 KHz" 10 "2 KHz" 11 "5 KHz" 12 "Custom 1" 13 "Custom 2" 14 "Custom 3" 15 "Not Available" ;
VAL_ 2369912574 PwmFrequencyCommand_X2_25 0 "1 Hz" 1 "2 Hz" 2 "5 Hz" 3 "10 Hz" 4 "20 Hz" 5 "50 Hz" 6 "100 Hz" 7 "200 Hz" 8 "500 Hz" 9 "1 KHz" 10 "2 KHz" 11 "5 KHz" 12 "Custom 1" 13 "Custom 2" 14 "Custom 3" 15 "Not Available" ;
VAL_ 2369912574 PwmFrequencyCommand_X2_27 0 "1 Hz" 1 "2 Hz" 2 "5 Hz" 3 "10 Hz" 4 "20 Hz" 5 "50 Hz" 6 "100 Hz" 7 "200 Hz" 8 "500 Hz" 9 "1 KHz" 10 "2 KHz" 11 "5 KHz" 12 "Custom 1" 13 "Custom 2" 14 "Custom 3" 15 "Not Available" ;
VAL_ 2369912574 PwmFrequencyCommand_X2_28 0 "1 Hz" 1 "2 Hz" 2 "5 Hz" 3 "10 Hz" 4 "20 Hz" 5 "50 Hz" 6 "100 Hz" 7 "200 Hz" 8 "500 Hz" 9 "1 KHz" 10 "2 KHz" 11 "5 KHz" 12 "Custom 1" 13 "Custom 2" 14 "Custom 3" 15 "Not Available" ;
VAL_ 2583656190 BridgeModeStatus_b01 0 "Freewheeling" 1 "Forward" 2 "Reverse" 3 "Brake" 6 "Error" 7 "Not Available" ;
VAL_ 2583656190 BridgeStatus_b01 0 "OK" 1 "Shutdown" 2 "Unconfigured" 7 "Not Available" ;
VAL_ 2583656190 BridgeModeStatus_b02 0 "Freewheeling" 1 "Forward" 2 "Reverse" 3 "Brake" 6 "Error" 7 "Not Available" ;
VAL_ 2583656190 BridgeStatus_b02 0 "OK" 1 "Shutdown" 2 "Unconfigured" 7 "Not Available" ;
VAL_ 2583656190 BridgeModeStatus_b03 0 "Freewheeling" 1 "Forward" 2 "Reverse" 3 "Brake" 6 "Error" 7 "Not Available" ;
VAL_ 2583656190 BridgeStatus_b03 0 "OK" 1 "Shutdown" 2 "Unconfigured" 7 "Not Available" ;
VAL_ 2583656190 BridgeModeStatus_b04 0 "Freewheeling" 1 "Forward" 2 "Reverse" 3 "Brake" 6 "Error" 7 "Not Available" ;
VAL_ 2583656190 BridgeStatus_b04 0 "OK" 1 "Shutdown" 2 "Unconfigured" 7 "Not Available" ;
VAL_ 2583656190 BridgeModeStatus_b05 0 "Freewheeling" 1 "Forward" 2 "Reverse" 3 "Brake" 6 "Error" 7 "Not Available" ;
VAL_ 2583656190 BridgeStatus_b05 0 "OK" 1 "Shutdown" 2 "Unconfigured" 7 "Not Available" ;
VAL_ 2583656190 BridgeModeStatus_b06 0 "Freewheeling" 1 "Forward" 2 "Reverse" 3 "Brake" 6 "Error" 7 "Not Available" ;
VAL_ 2583656190 BridgeStatus_b06 0 "OK" 1 "Shutdown" 2 "Unconfigured" 7 "Not Available" ;
VAL_ 2583656190 BridgeModeStatus_b07 0 "Freewheeling" 1 "Forward" 2 "Reverse" 3 "Brake" 6 "Error" 7 "Not Available" ;
VAL_ 2583656190 BridgeStatus_b07 0 "OK" 1 "Shutdown" 2 "Unconfigured" 7 "Not Available" ;
VAL_ 2583656190 BridgeModeStatus_b08 0 "Freewheeling" 1 "Forward" 2 "Reverse" 3 "Brake" 6 "Error" 7 "Not Available" ;
VAL_ 2583656190 BridgeStatus_b08 0 "OK" 1 "Shutdown" 2 "Unconfigured" 7 "Not Available" ;
VAL_ 2583648766 DiagnosticStatus_X1_11 0 "OK" 1 "Open Load" 2 "Short to VBAT" 3 "Short to GND" 4 "Over-current" 5 "Over temperature" 6 "Under voltage" 7 "Over voltage" 8 "Bad Configuration" 9 "HW Fault Detected" 10 "Vbat Error" 14 "Error" 15 "Not Available" ;
VAL_ 2583648766 DiagnosticStatus_X1_12 0 "OK" 1 "Open Load" 2 "Short to VBAT" 3 "Short to GND" 4 "Over-current" 5 "Over temperature" 6 "Under voltage" 7 "Over voltage" 8 "Bad Configuration" 9 "HW Fault Detected" 10 "Vbat Error" 14 "Error" 15 "Not Available" ;
VAL_ 2583648766 DiagnosticStatus_X1_13 0 "OK" 1 "Open Load" 2 "Short to VBAT" 3 "Short to GND" 4 "Over-current" 5 "Over temperature" 6 "Under voltage" 7 "Over voltage" 8 "Bad Configuration" 9 "HW Fault Detected" 10 "Vbat Error" 14 "Error" 15 "Not Available" ;
VAL_ 2583648766 DiagnosticStatus_X1_14 0 "OK" 1 "Open Load" 2 "Short to VBAT" 3 "Short to GND" 4 "Over-current" 5 "Over temperature" 6 "Under voltage" 7 "Over voltage" 8 "Bad Configuration" 9 "HW Fault Detected" 10 "Vbat Error" 14 "Error" 15 "Not Available" ;
VAL_ 2583648766 DiagnosticStatus_X1_15 0 "OK" 1 "Open Load" 2 "Short to VBAT" 3 "Short to GND" 4 "Over-current" 5 "Over temperature" 6 "Under voltage" 7 "Over voltage" 8 "Bad Configuration" 9 "HW Fault Detected" 10 "Vbat Error" 14 "Error" 15 "Not Available" ;
VAL_ 2583648766 DiagnosticStatus_X1_16 0 "OK" 1 "Open Load" 2 "Short to VBAT" 3 "Short to GND" 4 "Over-current" 5 "Over temperature" 6 "Under voltage" 7 "Over voltage" 8 "Bad Configuration" 9 "HW Fault Detected" 10 "Vbat Error" 14 "Error" 15 "Not Available" ;
VAL_ 2583648766 DiagnosticStatus_X1_17 0 "OK" 1 "Open Load" 2 "Short to VBAT" 3 "Short to GND" 4 "Over-current" 5 "Over temperature" 6 "Under voltage" 7 "Over voltage" 8 "Bad Configuration" 9 "HW Fault Detected" 10 "Vbat Error" 14 "Error" 15 "Not Available" ;
VAL_ 2583648766 DiagnosticStatus_X1_18 0 "OK" 1 "Open Load" 2 "Short to VBAT" 3 "Short to GND" 4 "Over-current" 5 "Over temperature" 6 "Under voltage" 7 "Over voltage" 8 "Bad Configuration" 9 "HW Fault Detected" 10 "Vbat Error" 14 "Error" 15 "Not Available" ;
VAL_ 2583648766 DiagnosticStatus_X1_24 0 "OK" 1 "Open Load" 2 "Short to VBAT" 3 "Short to GND" 4 "Over-current" 5 "Over temperature" 6 "Under voltage" 7 "Over voltage" 8 "Bad Configuration" 9 "HW Fault Detected" 10 "Vbat Error" 14 "Error" 15 "Not Available" ;
VAL_ 2583648766 DiagnosticStatus_X1_25 0 "OK" 1 "Open Load" 2 "Short to VBAT" 3 "Short to GND" 4 "Over-current" 5 "Over temperature" 6 "Under voltage" 7 "Over voltage" 8 "Bad Configuration" 9 "HW Fault Detected" 10 "Vbat Error" 14 "Error" 15 "Not Available" ;
VAL_ 2583648766 DiagnosticStatus_X1_3 0 "OK" 1 "Open Load" 2 "Short to VBAT" 3 "Short to GND" 4 "Over-current" 5 "Over temperature" 6 "Under voltage" 7 "Over voltage" 8 "Bad Configuration" 9 "HW Fault Detected" 10 "Vbat Error" 14 "Error" 15 "Not Available" ;
VAL_ 2583648766 DiagnosticStatus_X1_4 0 "OK" 1 "Open Load" 2 "Short to VBAT" 3 "Short to GND" 4 "Over-current" 5 "Over temperature" 6 "Under voltage" 7 "Over voltage" 8 "Bad Configuration" 9 "HW Fault Detected" 10 "Vbat Error" 14 "Error" 15 "Not Available" ;
VAL_ 2583648766 DiagnosticStatus_X2_24 0 "OK" 1 "Open Load" 2 "Short to VBAT" 3 "Short to GND" 4 "Over-current" 5 "Over temperature" 6 "Under voltage" 7 "Over voltage" 8 "Bad Configuration" 9 "HW Fault Detected" 10 "Vbat Error" 14 "Error" 15 "Not Available" ;
VAL_ 2583648766 DiagnosticStatus_X2_25 0 "OK" 1 "Open Load" 2 "Short to VBAT" 3 "Short to GND" 4 "Over-current" 5 "Over temperature" 6 "Under voltage" 7 "Over voltage" 8 "Bad Configuration" 9 "HW Fault Detected" 10 "Vbat Error" 14 "Error" 15 "Not Available" ;
VAL_ 2583648766 DiagnosticStatus_X2_27 0 "OK" 1 "Open Load" 2 "Short to VBAT" 3 "Short to GND" 4 "Over-current" 5 "Over temperature" 6 "Under voltage" 7 "Over voltage" 8 "Bad Configuration" 9 "HW Fault Detected" 10 "Vbat Error" 14 "Error" 15 "Not Available" ;
VAL_ 2583648766 DiagnosticStatus_X2_28 0 "OK" 1 "Open Load" 2 "Short to VBAT" 3 "Short to GND" 4 "Over-current" 5 "Over temperature" 6 "Under voltage" 7 "Over voltage" 8 "Bad Configuration" 9 "HW Fault Detected" 10 "Vbat Error" 14 "Error" 15 "Not Available" ;
VAL_ 2583649022 DiagnosticStatus_X2_11 0 "OK" 1 "Open Load" 2 "Short to VBAT" 3 "Short to GND" 4 "Over-current" 5 "Over temperature" 6 "Under voltage" 7 "Over voltage" 8 "Bad Configuration" 9 "HW Fault Detected" 10 "Vbat Error" 14 "Error" 15 "Not Available" ;
VAL_ 2583649022 DiagnosticStatus_X2_12 0 "OK" 1 "Open Load" 2 "Short to VBAT" 3 "Short to GND" 4 "Over-current" 5 "Over temperature" 6 "Under voltage" 7 "Over voltage" 8 "Bad Configuration" 9 "HW Fault Detected" 10 "Vbat Error" 14 "Error" 15 "Not Available" ;
VAL_ 2583649022 DiagnosticStatus_X2_13 0 "OK" 1 "Open Load" 2 "Short to VBAT" 3 "Short to GND" 4 "Over-current" 5 "Over temperature" 6 "Under voltage" 7 "Over voltage" 8 "Bad Configuration" 9 "HW Fault Detected" 10 "Vbat Error" 14 "Error" 15 "Not Available" ;
VAL_ 2583649022 DiagnosticStatus_X2_14 0 "OK" 1 "Open Load" 2 "Short to VBAT" 3 "Short to GND" 4 "Over-current" 5 "Over temperature" 6 "Under voltage" 7 "Over voltage" 8 "Bad Configuration" 9 "HW Fault Detected" 10 "Vbat Error" 14 "Error" 15 "Not Available" ;
VAL_ 2583649022 DiagnosticStatus_X2_15 0 "OK" 1 "Open Load" 2 "Short to VBAT" 3 "Short to GND" 4 "Over-current" 5 "Over temperature" 6 "Under voltage" 7 "Over voltage" 8 "Bad Configuration" 9 "HW Fault Detected" 10 "Vbat Error" 14 "Error" 15 "Not Available" ;
VAL_ 2583649022 DiagnosticStatus_X2_16 0 "OK" 1 "Open Load" 2 "Short to VBAT" 3 "Short to GND" 4 "Over-current" 5 "Over temperature" 6 "Under voltage" 7 "Over voltage" 8 "Bad Configuration" 9 "HW Fault Detected" 10 "Vbat Error" 14 "Error" 15 "Not Available" ;
VAL_ 2583649022 DiagnosticStatus_X2_17 0 "OK" 1 "Open Load" 2 "Short to VBAT" 3 "Short to GND" 4 "Over-current" 5 "Over temperature" 6 "Under voltage" 7 "Over voltage" 8 "Bad Configuration" 9 "HW Fault Detected" 10 "Vbat Error" 14 "Error" 15 "Not Available" ;
VAL_ 2583649022 DiagnosticStatus_X2_18 0 "OK" 1 "Open Load" 2 "Short to VBAT" 3 "Short to GND" 4 "Over-current" 5 "Over temperature" 6 "Under voltage" 7 "Over voltage" 8 "Bad Configuration" 9 "HW Fault Detected" 10 "Vbat Error" 14 "Error" 15 "Not Available" ;
VAL_ 2582847486 DiagnosticStatus_X1_11 0 "OK" 1 "Open Load" 2 "Short to VBAT" 3 "Short to GND" 4 "Over-current" 5 "Over temperature" 6 "Under voltage" 7 "Over voltage" 8 "Bad Configuration" 9 "HW Fault Detected" 10 "Vbat Error" 14 "Error" 15 "Not Available" ;
VAL_ 2582847486 DiagnosticStatus_X1_12 0 "OK" 1 "Open Load" 2 "Short to VBAT" 3 "Short to GND" 4 "Over-current" 5 "Over temperature" 6 "Under voltage" 7 "Over voltage" 8 "Bad Configuration" 9 "HW Fault Detected" 10 "Vbat Error" 14 "Error" 15 "Not Available" ;
VAL_ 2582847486 DiagnosticStatus_X1_13 0 "OK" 1 "Open Load" 2 "Short to VBAT" 3 "Short to GND" 4 "Over-current" 5 "Over temperature" 6 "Under voltage" 7 "Over voltage" 8 "Bad Configuration" 9 "HW Fault Detected" 10 "Vbat Error" 14 "Error" 15 "Not Available" ;
VAL_ 2582847486 DiagnosticStatus_X1_14 0 "OK" 1 "Open Load" 2 "Short to VBAT" 3 "Short to GND" 4 "Over-current" 5 "Over temperature" 6 "Under voltage" 7 "Over voltage" 8 "Bad Configuration" 9 "HW Fault Detected" 10 "Vbat Error" 14 "Error" 15 "Not Available" ;
VAL_ 2582847486 DiagnosticStatus_X1_15 0 "OK" 1 "Open Load" 2 "Short to VBAT" 3 "Short to GND" 4 "Over-current" 5 "Over temperature" 6 "Under voltage" 7 "Over voltage" 8 "Bad Configuration" 9 "HW Fault Detected" 10 "Vbat Error" 14 "Error" 15 "Not Available" ;
VAL_ 2582847486 DiagnosticStatus_X1_16 0 "OK" 1 "Open Load" 2 "Short to VBAT" 3 "Short to GND" 4 "Over-current" 5 "Over temperature" 6 "Under voltage" 7 "Over voltage" 8 "Bad Configuration" 9 "HW Fault Detected" 10 "Vbat Error" 14 "Error" 15 "Not Available" ;
VAL_ 2582847486 DiagnosticStatus_X1_17 0 "OK" 1 "Open Load" 2 "Short to VBAT" 3 "Short to GND" 4 "Over-current" 5 "Over temperature" 6 "Under voltage" 7 "Over voltage" 8 "Bad Configuration" 9 "HW Fault Detected" 10 "Vbat Error" 14 "Error" 15 "Not Available" ;
VAL_ 2582847486 DiagnosticStatus_X1_18 0 "OK" 1 "Open Load" 2 "Short to VBAT" 3 "Short to GND" 4 "Over-current" 5 "Over temperature" 6 "Under voltage" 7 "Over voltage" 8 "Bad Configuration" 9 "HW Fault Detected" 10 "Vbat Error" 14 "Error" 15 "Not Available" ;
VAL_ 2582847486 DiagnosticStatus_X1_24 0 "OK" 1 "Open Load" 2 "Short to VBAT" 3 "Short to GND" 4 "Over-current" 5 "Over temperature" 6 "Under voltage" 7 "Over voltage" 8 "Bad Configuration" 9 "HW Fault Detected" 10 "Vbat Error" 14 "Error" 15 "Not Available" ;
VAL_ 2582847486 DiagnosticStatus_X1_25 0 "OK" 1 "Open Load" 2 "Short to VBAT" 3 "Short to GND" 4 "Over-current" 5 "Over temperature" 6 "Under voltage" 7 "Over voltage" 8 "Bad Configuration" 9 "HW Fault Detected" 10 "Vbat Error" 14 "Error" 15 "Not Available" ;
VAL_ 2582847486 DiagnosticStatus_X1_3 0 "OK" 1 "Open Load" 2 "Short to VBAT" 3 "Short to GND" 4 "Over-current" 5 "Over temperature" 6 "Under voltage" 7 "Over voltage" 8 "Bad Configuration" 9 "HW Fault Detected" 10 "Vbat Error" 14 "Error" 15 "Not Available" ;
VAL_ 2582847486 DiagnosticStatus_X1_4 0 "OK" 1 "Open Load" 2 "Short to VBAT" 3 "Short to GND" 4 "Over-current" 5 "Over temperature" 6 "Under voltage" 7 "Over voltage" 8 "Bad Configuration" 9 "HW Fault Detected" 10 "Vbat Error" 14 "Error" 15 "Not Available" ;
VAL_ 2582847486 DiagnosticStatus_X2_24 0 "OK" 1 "Open Load" 2 "Short to VBAT" 3 "Short to GND" 4 "Over-current" 5 "Over temperature" 6 "Under voltage" 7 "Over voltage" 8 "Bad Configuration" 9 "HW Fault Detected" 10 "Vbat Error" 14 "Error" 15 "Not Available" ;
VAL_ 2582847486 DiagnosticStatus_X2_25 0 "OK" 1 "Open Load" 2 "Short to VBAT" 3 "Short to GND" 4 "Over-current" 5 "Over temperature" 6 "Under voltage" 7 "Over voltage" 8 "Bad Configuration" 9 "HW Fault Detected" 10 "Vbat Error" 14 "Error" 15 "Not Available" ;
VAL_ 2582847486 DiagnosticStatus_X2_27 0 "OK" 1 "Open Load" 2 "Short to VBAT" 3 "Short to GND" 4 "Over-current" 5 "Over temperature" 6 "Under voltage" 7 "Over voltage" 8 "Bad Configuration" 9 "HW Fault Detected" 10 "Vbat Error" 14 "Error" 15 "Not Available" ;
VAL_ 2582847486 DiagnosticStatus_X2_28 0 "OK" 1 "Open Load" 2 "Short to VBAT" 3 "Short to GND" 4 "Over-current" 5 "Over temperature" 6 "Under voltage" 7 "Over voltage" 8 "Bad Configuration" 9 "HW Fault Detected" 10 "Vbat Error" 14 "Error" 15 "Not Available" ;
VAL_ 2582847486 DiagnosticStatus_X2_11 0 "OK" 1 "Open Load" 2 "Short to VBAT" 3 "Short to GND" 4 "Over-current" 5 "Over temperature" 6 "Under voltage" 7 "Over voltage" 8 "Bad Configuration" 9 "HW Fault Detected" 10 "Vbat Error" 14 "Error" 15 "Not Available" ;
VAL_ 2582847486 DiagnosticStatus_X2_12 0 "OK" 1 "Open Load" 2 "Short to VBAT" 3 "Short to GND" 4 "Over-current" 5 "Over temperature" 6 "Under voltage" 7 "Over voltage" 8 "Bad Configuration" 9 "HW Fault Detected" 10 "Vbat Error" 14 "Error" 15 "Not Available" ;
VAL_ 2582847486 DiagnosticStatus_X2_13 0 "OK" 1 "Open Load" 2 "Short to VBAT" 3 "Short to GND" 4 "Over-current" 5 "Over temperature" 6 "Under voltage" 7 "Over voltage" 8 "Bad Configuration" 9 "HW Fault Detected" 10 "Vbat Error" 14 "Error" 15 "Not Available" ;
VAL_ 2582847486 DiagnosticStatus_X2_14 0 "OK" 1 "Open Load" 2 "Short to VBAT" 3 "Short to GND" 4 "Over-current" 5 "Over temperature" 6 "Under voltage" 7 "Over voltage" 8 "Bad Configuration" 9 "HW Fault Detected" 10 "Vbat Error" 14 "Error" 15 "Not Available" ;
VAL_ 2582847486 DiagnosticStatus_X2_15 0 "OK" 1 "Open Load" 2 "Short to VBAT" 3 "Short to GND" 4 "Over-current" 5 "Over temperature" 6 "Under voltage" 7 "Over voltage" 8 "Bad Configuration" 9 "HW Fault Detected" 10 "Vbat Error" 14 "Error" 15 "Not Available" ;
VAL_ 2582847486 DiagnosticStatus_X2_16 0 "OK" 1 "Open Load" 2 "Short to VBAT" 3 "Short to GND" 4 "Over-current" 5 "Over temperature" 6 "Under voltage" 7 "Over voltage" 8 "Bad Configuration" 9 "HW Fault Detected" 10 "Vbat Error" 14 "Error" 15 "Not Available" ;
VAL_ 2582847486 DiagnosticStatus_X2_17 0 "OK" 1 "Open Load" 2 "Short to VBAT" 3 "Short to GND" 4 "Over-current" 5 "Over temperature" 6 "Under voltage" 7 "Over voltage" 8 "Bad Configuration" 9 "HW Fault Detected" 10 "Vbat Error" 14 "Error" 15 "Not Available" ;
VAL_ 2582847486 DiagnosticStatus_X2_18 0 "OK" 1 "Open Load" 2 "Short to VBAT" 3 "Short to GND" 4 "Over-current" 5 "Over temperature" 6 "Under voltage" 7 "Over voltage" 8 "Bad Configuration" 9 "HW Fault Detected" 10 "Vbat Error" 14 "Error" 15 "Not Available" ;
VAL_ 2583646718 PinModeStatus_X1_11 0 "Disabled" 1 "VREF" 2 "HighSide" 3 "LowSide" 4 "InputOnly" 5 "Bridge" 14 "Error" 15 "Not Available" ;
VAL_ 2583646718 PinPullModeStatus_X1_11 0 "None" 1 "PullDown" 2 "PullUp" 3 "Not Available" ;
VAL_ 2583646718 LoadDetectionStatus_X1_11 0 "Off" 1 "On" 2 "Error" 3 "Not Available" ;
VAL_ 2583646718 PinModeStatus_X1_12 0 "Disabled" 1 "VREF" 2 "HighSide" 3 "LowSide" 4 "InputOnly" 5 "Bridge" 14 "Error" 15 "Not Available" ;
VAL_ 2583646718 PinPullModeStatus_X1_12 0 "None" 1 "PullDown" 2 "PullUp" 3 "Not Available" ;
VAL_ 2583646718 LoadDetectionStatus_X1_12 0 "Off" 1 "On" 2 "Error" 3 "Not Available" ;
VAL_ 2583646718 PinModeStatus_X1_13 0 "Disabled" 1 "VREF" 2 "HighSide" 3 "LowSide" 4 "InputOnly" 5 "Bridge" 14 "Error" 15 "Not Available" ;
VAL_ 2583646718 PinPullModeStatus_X1_13 0 "None" 1 "PullDown" 2 "PullUp" 3 "Not Available" ;
VAL_ 2583646718 LoadDetectionStatus_X1_13 0 "Off" 1 "On" 2 "Error" 3 "Not Available" ;
VAL_ 2583646718 PinModeStatus_X1_14 0 "Disabled" 1 "VREF" 2 "HighSide" 3 "LowSide" 4 "InputOnly" 5 "Bridge" 14 "Error" 15 "Not Available" ;
VAL_ 2583646718 PinPullModeStatus_X1_14 0 "None" 1 "PullDown" 2 "PullUp" 3 "Not Available" ;
VAL_ 2583646718 LoadDetectionStatus_X1_14 0 "Off" 1 "On" 2 "Error" 3 "Not Available" ;
VAL_ 2583646718 PinModeStatus_X1_15 0 "Disabled" 1 "VREF" 2 "HighSide" 3 "LowSide" 4 "InputOnly" 5 "Bridge" 14 "Error" 15 "Not Available" ;
VAL_ 2583646718 PinPullModeStatus_X1_15 0 "None" 1 "PullDown" 2 "PullUp" 3 "Not Available" ;
VAL_ 2583646718 LoadDetectionStatus_X1_15 0 "Off" 1 "On" 2 "Error" 3 "Not Available" ;
VAL_ 2583646718 PinModeStatus_X1_16 0 "Disabled" 1 "VREF" 2 "HighSide" 3 "LowSide" 4 "InputOnly" 5 "Bridge" 14 "Error" 15 "Not Available" ;
VAL_ 2583646718 PinPullModeStatus_X1_16 0 "None" 1 "PullDown" 2 "PullUp" 3 "Not Available" ;
VAL_ 2583646718 LoadDetectionStatus_X1_16 0 "Off" 1 "On" 2 "Error" 3 "Not Available" ;
VAL_ 2583646718 PinModeStatus_X1_17 0 "Disabled" 1 "VREF" 2 "HighSide" 3 "LowSide" 4 "InputOnly" 5 "Bridge" 14 "Error" 15 "Not Available" ;
VAL_ 2583646718 PinPullModeStatus_X1_17 0 "None" 1 "PullDown" 2 "PullUp" 3 "Not Available" ;
VAL_ 2583646718 LoadDetectionStatus_X1_17 0 "Off" 1 "On" 2 "Error" 3 "Not Available" ;
VAL_ 2583646718 PinModeStatus_X1_18 0 "Disabled" 1 "VREF" 2 "HighSide" 3 "LowSide" 4 "InputOnly" 5 "Bridge" 14 "Error" 15 "Not Available" ;
VAL_ 2583646718 PinPullModeStatus_X1_18 0 "None" 1 "PullDown" 2 "PullUp" 3 "Not Available" ;
VAL_ 2583646718 LoadDetectionStatus_X1_18 0 "Off" 1 "On" 2 "Error" 3 "Not Available" ;
VAL_ 2583646974 PinModeStatus_X1_24 0 "Disabled" 1 "VREF" 2 "HighSide" 3 "LowSide" 4 "InputOnly" 5 "Bridge" 14 "Error" 15 "Not Available" ;
VAL_ 2583646974 PinPullModeStatus_X1_24 0 "None" 1 "PullDown" 2 "PullUp" 3 "Not Available" ;
VAL_ 2583646974 LoadDetectionStatus_X1_24 0 "Off" 1 "On" 2 "Error" 3 "Not Available" ;
VAL_ 2583646974 PinModeStatus_X1_25 0 "Disabled" 1 "VREF" 2 "HighSide" 3 "LowSide" 4 "InputOnly" 5 "Bridge" 14 "Error" 15 "Not Available" ;
VAL_ 2583646974 PinPullModeStatus_X1_25 0 "None" 1 "PullDown" 2 "PullUp" 3 "Not Available" ;
VAL_ 2583646974 LoadDetectionStatus_X1_25 0 "Off" 1 "On" 2 "Error" 3 "Not Available" ;
VAL_ 2583646974 PinModeStatus_X1_3 0 "Disabled" 1 "VREF" 2 "HighSide" 3 "LowSide" 4 "InputOnly" 5 "Bridge" 14 "Error" 15 "Not Available" ;
VAL_ 2583646974 PinPullModeStatus_X1_3 0 "None" 1 "PullDown" 2 "PullUp" 3 "Not Available" ;
VAL_ 2583646974 LoadDetectionStatus_X1_3 0 "Off" 1 "On" 2 "Error" 3 "Not Available" ;
VAL_ 2583646974 PinModeStatus_X1_4 0 "Disabled" 1 "VREF" 2 "HighSide" 3 "LowSide" 4 "InputOnly" 5 "Bridge" 14 "Error" 15 "Not Available" ;
VAL_ 2583646974 PinPullModeStatus_X1_4 0 "None" 1 "PullDown" 2 "PullUp" 3 "Not Available" ;
VAL_ 2583646974 LoadDetectionStatus_X1_4 0 "Off" 1 "On" 2 "Error" 3 "Not Available" ;
VAL_ 2583646974 PinModeStatus_X2_24 0 "Disabled" 1 "VREF" 2 "HighSide" 3 "LowSide" 4 "InputOnly" 5 "Bridge" 14 "Error" 15 "Not Available" ;
VAL_ 2583646974 PinPullModeStatus_X2_24 0 "None" 1 "PullDown" 2 "PullUp" 3 "Not Available" ;
VAL_ 2583646974 LoadDetectionStatus_X2_24 0 "Off" 1 "On" 2 "Error" 3 "Not Available" ;
VAL_ 2583646974 PinModeStatus_X2_25 0 "Disabled" 1 "VREF" 2 "HighSide" 3 "LowSide" 4 "InputOnly" 5 "Bridge" 14 "Error" 15 "Not Available" ;
VAL_ 2583646974 PinPullModeStatus_X2_25 0 "None" 1 "PullDown" 2 "PullUp" 3 "Not Available" ;
VAL_ 2583646974 LoadDetectionStatus_X2_25 0 "Off" 1 "On" 2 "Error" 3 "Not Available" ;
VAL_ 2583646974 PinModeStatus_X2_27 0 "Disabled" 1 "VREF" 2 "HighSide" 3 "LowSide" 4 "InputOnly" 5 "Bridge" 14 "Error" 15 "Not Available" ;
VAL_ 2583646974 PinPullModeStatus_X2_27 0 "None" 1 "PullDown" 2 "PullUp" 3 "Not Available" ;
VAL_ 2583646974 LoadDetectionStatus_X2_27 0 "Off" 1 "On" 2 "Error" 3 "Not Available" ;
VAL_ 2583646974 PinModeStatus_X2_28 0 "Disabled" 1 "VREF" 2 "HighSide" 3 "LowSide" 4 "InputOnly" 5 "Bridge" 14 "Error" 15 "Not Available" ;
VAL_ 2583646974 PinPullModeStatus_X2_28 0 "None" 1 "PullDown" 2 "PullUp" 3 "Not Available" ;
VAL_ 2583646974 LoadDetectionStatus_X2_28 0 "Off" 1 "On" 2 "Error" 3 "Not Available" ;
VAL_ 2583647230 PinModeStatus_X2_11 0 "Disabled" 1 "VREF" 2 "HighSide" 3 "LowSide" 4 "InputOnly" 5 "Bridge" 14 "Error" 15 "Not Available" ;
VAL_ 2583647230 PinPullModeStatus_X2_11 0 "None" 1 "PullDown" 2 "PullUp" 3 "Not Available" ;
VAL_ 2583647230 LoadDetectionStatus_X2_11 0 "Off" 1 "On" 2 "Error" 3 "Not Available" ;
VAL_ 2583647230 PinModeStatus_X2_12 0 "Disabled" 1 "VREF" 2 "HighSide" 3 "LowSide" 4 "InputOnly" 5 "Bridge" 14 "Error" 15 "Not Available" ;
VAL_ 2583647230 PinPullModeStatus_X2_12 0 "None" 1 "PullDown" 2 "PullUp" 3 "Not Available" ;
VAL_ 2583647230 LoadDetectionStatus_X2_12 0 "Off" 1 "On" 2 "Error" 3 "Not Available" ;
VAL_ 2583647230 PinModeStatus_X2_13 0 "Disabled" 1 "VREF" 2 "HighSide" 3 "LowSide" 4 "InputOnly" 5 "Bridge" 14 "Error" 15 "Not Available" ;
VAL_ 2583647230 PinPullModeStatus_X2_13 0 "None" 1 "PullDown" 2 "PullUp" 3 "Not Available" ;
VAL_ 2583647230 LoadDetectionStatus_X2_13 0 "Off" 1 "On" 2 "Error" 3 "Not Available" ;
VAL_ 2583647230 PinModeStatus_X2_14 0 "Disabled" 1 "VREF" 2 "HighSide" 3 "LowSide" 4 "InputOnly" 5 "Bridge" 14 "Error" 15 "Not Available" ;
VAL_ 2583647230 PinPullModeStatus_X2_14 0 "None" 1 "PullDown" 2 "PullUp" 3 "Not Available" ;
VAL_ 2583647230 LoadDetectionStatus_X2_14 0 "Off" 1 "On" 2 "Error" 3 "Not Available" ;
VAL_ 2583647230 PinModeStatus_X2_15 0 "Disabled" 1 "VREF" 2 "HighSide" 3 "LowSide" 4 "InputOnly" 5 "Bridge" 14 "Error" 15 "Not Available" ;
VAL_ 2583647230 PinPullModeStatus_X2_15 0 "None" 1 "PullDown" 2 "PullUp" 3 "Not Available" ;
VAL_ 2583647230 LoadDetectionStatus_X2_15 0 "Off" 1 "On" 2 "Error" 3 "Not Available" ;
VAL_ 2583647230 PinModeStatus_X2_16 0 "Disabled" 1 "VREF" 2 "HighSide" 3 "LowSide" 4 "InputOnly" 5 "Bridge" 14 "Error" 15 "Not Available" ;
VAL_ 2583647230 PinPullModeStatus_X2_16 0 "None" 1 "PullDown" 2 "PullUp" 3 "Not Available" ;
VAL_ 2583647230 LoadDetectionStatus_X2_16 0 "Off" 1 "On" 2 "Error" 3 "Not Available" ;
VAL_ 2583647230 PinModeStatus_X2_17 0 "Disabled" 1 "VREF" 2 "HighSide" 3 "LowSide" 4 "InputOnly" 5 "Bridge" 14 "Error" 15 "Not Available" ;
VAL_ 2583647230 PinPullModeStatus_X2_17 0 "None" 1 "PullDown" 2 "PullUp" 3 "Not Available" ;
VAL_ 2583647230 LoadDetectionStatus_X2_17 0 "Off" 1 "On" 2 "Error" 3 "Not Available" ;
VAL_ 2583647230 PinModeStatus_X2_18 0 "Disabled" 1 "VREF" 2 "HighSide" 3 "LowSide" 4 "InputOnly" 5 "Bridge" 14 "Error" 15 "Not Available" ;
VAL_ 2583647230 PinPullModeStatus_X2_18 0 "None" 1 "PullDown" 2 "PullUp" 3 "Not Available" ;
VAL_ 2583647230 LoadDetectionStatus_X2_18 0 "Off" 1 "On" 2 "Error" 3 "Not Available" ;
VAL_ 2582846974 PinModeStatus_X1_11 0 "Disabled" 1 "VREF" 2 "HighSide" 3 "LowSide" 4 "InputOnly" 5 "Bridge" 14 "Error" 15 "Not Available" ;
VAL_ 2582846974 PinPullModeStatus_X1_11 0 "None" 1 "PullDown" 2 "PullUp" 3 "Not Available" ;
VAL_ 2582846974 LoadDetectionStatus_X1_11 0 "Off" 1 "On" 2 "Error" 3 "Not Available" ;
VAL_ 2582846974 PinModeStatus_X1_12 0 "Disabled" 1 "VREF" 2 "HighSide" 3 "LowSide" 4 "InputOnly" 5 "Bridge" 14 "Error" 15 "Not Available" ;
VAL_ 2582846974 PinPullModeStatus_X1_12 0 "None" 1 "PullDown" 2 "PullUp" 3 "Not Available" ;
VAL_ 2582846974 LoadDetectionStatus_X1_12 0 "Off" 1 "On" 2 "Error" 3 "Not Available" ;
VAL_ 2582846974 PinModeStatus_X1_13 0 "Disabled" 1 "VREF" 2 "HighSide" 3 "LowSide" 4 "InputOnly" 5 "Bridge" 14 "Error" 15 "Not Available" ;
VAL_ 2582846974 PinPullModeStatus_X1_13 0 "None" 1 "PullDown" 2 "PullUp" 3 "Not Available" ;
VAL_ 2582846974 LoadDetectionStatus_X1_13 0 "Off" 1 "On" 2 "Error" 3 "Not Available" ;
VAL_ 2582846974 PinModeStatus_X1_14 0 "Disabled" 1 "VREF" 2 "HighSide" 3 "LowSide" 4 "InputOnly" 5 "Bridge" 14 "Error" 15 "Not Available" ;
VAL_ 2582846974 PinPullModeStatus_X1_14 0 "None" 1 "PullDown" 2 "PullUp" 3 "Not Available" ;
VAL_ 2582846974 LoadDetectionStatus_X1_14 0 "Off" 1 "On" 2 "Error" 3 "Not Available" ;
VAL_ 2582846974 PinModeStatus_X1_15 0 "Disabled" 1 "VREF" 2 "HighSide" 3 "LowSide" 4 "InputOnly" 5 "Bridge" 14 "Error" 15 "Not Available" ;
VAL_ 2582846974 PinPullModeStatus_X1_15 0 "None" 1 "PullDown" 2 "PullUp" 3 "Not Available" ;
VAL_ 2582846974 LoadDetectionStatus_X1_15 0 "Off" 1 "On" 2 "Error" 3 "Not Available" ;
VAL_ 2582846974 PinModeStatus_X1_16 0 "Disabled" 1 "VREF" 2 "HighSide" 3 "LowSide" 4 "InputOnly" 5 "Bridge" 14 "Error" 15 "Not Available" ;
VAL_ 2582846974 PinPullModeStatus_X1_16 0 "None" 1 "PullDown" 2 "PullUp" 3 "Not Available" ;
VAL_ 2582846974 LoadDetectionStatus_X1_16 0 "Off" 1 "On" 2 "Error" 3 "Not Available" ;
VAL_ 2582846974 PinModeStatus_X1_17 0 "Disabled" 1 "VREF" 2 "HighSide" 3 "LowSide" 4 "InputOnly" 5 "Bridge" 14 "Error" 15 "Not Available" ;
VAL_ 2582846974 PinPullModeStatus_X1_17 0 "None" 1 "PullDown" 2 "PullUp" 3 "Not Available" ;
VAL_ 2582846974 LoadDetectionStatus_X1_17 0 "Off" 1 "On" 2 "Error" 3 "Not Available" ;
VAL_ 2582846974 PinModeStatus_X1_18 0 "Disabled" 1 "VREF" 2 "HighSide" 3 "LowSide" 4 "InputOnly" 5 "Bridge" 14 "Error" 15 "Not Available" ;
VAL_ 2582846974 PinPullModeStatus_X1_18 0 "None" 1 "PullDown" 2 "PullUp" 3 "Not Available" ;
VAL_ 2582846974 LoadDetectionStatus_X1_18 0 "Off" 1 "On" 2 "Error" 3 "Not Available" ;
VAL_ 2582846974 PinModeStatus_X1_24 0 "Disabled" 1 "VREF" 2 "HighSide" 3 "LowSide" 4 "InputOnly" 5 "Bridge" 14 "Error" 15 "Not Available" ;
VAL_ 2582846974 PinPullModeStatus_X1_24 0 "None" 1 "PullDown" 2 "PullUp" 3 "Not Available" ;
VAL_ 2582846974 LoadDetectionStatus_X1_24 0 "Off" 1 "On" 2 "Error" 3 "Not Available" ;
VAL_ 2582846974 PinModeStatus_X1_25 0 "Disabled" 1 "VREF" 2 "HighSide" 3 "LowSide" 4 "InputOnly" 5 "Bridge" 14 "Error" 15 "Not Available" ;
VAL_ 2582846974 PinPullModeStatus_X1_25 0 "None" 1 "PullDown" 2 "PullUp" 3 "Not Available" ;
VAL_ 2582846974 LoadDetectionStatus_X1_25 0 "Off" 1 "On" 2 "Error" 3 "Not Available" ;
VAL_ 2582846974 PinModeStatus_X1_3 0 "Disabled" 1 "VREF" 2 "HighSide" 3 "LowSide" 4 "InputOnly" 5 "Bridge" 14 "Error" 15 "Not Available" ;
VAL_ 2582846974 PinPullModeStatus_X1_3 0 "None" 1 "PullDown" 2 "PullUp" 3 "Not Available" ;
VAL_ 2582846974 LoadDetectionStatus_X1_3 0 "Off" 1 "On" 2 "Error" 3 "Not Available" ;
VAL_ 2582846974 PinModeStatus_X1_4 0 "Disabled" 1 "VREF" 2 "HighSide" 3 "LowSide" 4 "InputOnly" 5 "Bridge" 14 "Error" 15 "Not Available" ;
VAL_ 2582846974 PinPullModeStatus_X1_4 0 "None" 1 "PullDown" 2 "PullUp" 3 "Not Available" ;
VAL_ 2582846974 LoadDetectionStatus_X1_4 0 "Off" 1 "On" 2 "Error" 3 "Not Available" ;
VAL_ 2582846974 PinModeStatus_X2_24 0 "Disabled" 1 "VREF" 2 "HighSide" 3 "LowSide" 4 "InputOnly" 5 "Bridge" 14 "Error" 15 "Not Available" ;
VAL_ 2582846974 PinPullModeStatus_X2_24 0 "None" 1 "PullDown" 2 "PullUp" 3 "Not Available" ;
VAL_ 2582846974 LoadDetectionStatus_X2_24 0 "Off" 1 "On" 2 "Error" 3 "Not Available" ;
VAL_ 2582846974 PinModeStatus_X2_25 0 "Disabled" 1 "VREF" 2 "HighSide" 3 "LowSide" 4 "InputOnly" 5 "Bridge" 14 "Error" 15 "Not Available" ;
VAL_ 2582846974 PinPullModeStatus_X2_25 0 "None" 1 "PullDown" 2 "PullUp" 3 "Not Available" ;
VAL_ 2582846974 LoadDetectionStatus_X2_25 0 "Off" 1 "On" 2 "Error" 3 "Not Available" ;
VAL_ 2582846974 PinModeStatus_X2_27 0 "Disabled" 1 "VREF" 2 "HighSide" 3 "LowSide" 4 "InputOnly" 5 "Bridge" 14 "Error" 15 "Not Available" ;
VAL_ 2582846974 PinPullModeStatus_X2_27 0 "None" 1 "PullDown" 2 "PullUp" 3 "Not Available" ;
VAL_ 2582846974 LoadDetectionStatus_X2_27 0 "Off" 1 "On" 2 "Error" 3 "Not Available" ;
VAL_ 2582846974 PinModeStatus_X2_28 0 "Disabled" 1 "VREF" 2 "HighSide" 3 "LowSide" 4 "InputOnly" 5 "Bridge" 14 "Error" 15 "Not Available" ;
VAL_ 2582846974 PinPullModeStatus_X2_28 0 "None" 1 "PullDown" 2 "PullUp" 3 "Not Available" ;
VAL_ 2582846974 LoadDetectionStatus_X2_28 0 "Off" 1 "On" 2 "Error" 3 "Not Available" ;
VAL_ 2582846974 PinModeStatus_X2_11 0 "Disabled" 1 "VREF" 2 "HighSide" 3 "LowSide" 4 "InputOnly" 5 "Bridge" 14 "Error" 15 "Not Available" ;
VAL_ 2582846974 PinPullModeStatus_X2_11 0 "None" 1 "PullDown" 2 "PullUp" 3 "Not Available" ;
VAL_ 2582846974 LoadDetectionStatus_X2_11 0 "Off" 1 "On" 2 "Error" 3 "Not Available" ;
VAL_ 2582846974 PinModeStatus_X2_12 0 "Disabled" 1 "VREF" 2 "HighSide" 3 "LowSide" 4 "InputOnly" 5 "Bridge" 14 "Error" 15 "Not Available" ;
VAL_ 2582846974 PinPullModeStatus_X2_12 0 "None" 1 "PullDown" 2 "PullUp" 3 "Not Available" ;
VAL_ 2582846974 LoadDetectionStatus_X2_12 0 "Off" 1 "On" 2 "Error" 3 "Not Available" ;
VAL_ 2582846974 PinModeStatus_X2_13 0 "Disabled" 1 "VREF" 2 "HighSide" 3 "LowSide" 4 "InputOnly" 5 "Bridge" 14 "Error" 15 "Not Available" ;
VAL_ 2582846974 PinPullModeStatus_X2_13 0 "None" 1 "PullDown" 2 "PullUp" 3 "Not Available" ;
VAL_ 2582846974 LoadDetectionStatus_X2_13 0 "Off" 1 "On" 2 "Error" 3 "Not Available" ;
VAL_ 2582846974 PinModeStatus_X2_14 0 "Disabled" 1 "VREF" 2 "HighSide" 3 "LowSide" 4 "InputOnly" 5 "Bridge" 14 "Error" 15 "Not Available" ;
VAL_ 2582846974 PinPullModeStatus_X2_14 0 "None" 1 "PullDown" 2 "PullUp" 3 "Not Available" ;
VAL_ 2582846974 LoadDetectionStatus_X2_14 0 "Off" 1 "On" 2 "Error" 3 "Not Available" ;
VAL_ 2582846974 PinModeStatus_X2_15 0 "Disabled" 1 "VREF" 2 "HighSide" 3 "LowSide" 4 "InputOnly" 5 "Bridge" 14 "Error" 15 "Not Available" ;
VAL_ 2582846974 PinPullModeStatus_X2_15 0 "None" 1 "PullDown" 2 "PullUp" 3 "Not Available" ;
VAL_ 2582846974 LoadDetectionStatus_X2_15 0 "Off" 1 "On" 2 "Error" 3 "Not Available" ;
VAL_ 2582846974 PinModeStatus_X2_16 0 "Disabled" 1 "VREF" 2 "HighSide" 3 "LowSide" 4 "InputOnly" 5 "Bridge" 14 "Error" 15 "Not Available" ;
VAL_ 2582846974 PinPullModeStatus_X2_16 0 "None" 1 "PullDown" 2 "PullUp" 3 "Not Available" ;
VAL_ 2582846974 LoadDetectionStatus_X2_16 0 "Off" 1 "On" 2 "Error" 3 "Not Available" ;
VAL_ 2582846974 PinModeStatus_X2_17 0 "Disabled" 1 "VREF" 2 "HighSide" 3 "LowSide" 4 "InputOnly" 5 "Bridge" 14 "Error" 15 "Not Available" ;
VAL_ 2582846974 PinPullModeStatus_X2_17 0 "None" 1 "PullDown" 2 "PullUp" 3 "Not Available" ;
VAL_ 2582846974 LoadDetectionStatus_X2_17 0 "Off" 1 "On" 2 "Error" 3 "Not Available" ;
VAL_ 2582846974 PinModeStatus_X2_18 0 "Disabled" 1 "VREF" 2 "HighSide" 3 "LowSide" 4 "InputOnly" 5 "Bridge" 14 "Error" 15 "Not Available" ;
VAL_ 2582846974 PinPullModeStatus_X2_18 0 "None" 1 "PullDown" 2 "PullUp" 3 "Not Available" ;
VAL_ 2582846974 LoadDetectionStatus_X2_18 0 "Off" 1 "On" 2 "Error" 3 "Not Available" ;
VAL_ 2582847998 QEncoderDirection_Q01 0 "Stopped" 1 "Forward" 2 "Reverse" 3 "NotAvailable" ;
